[part 10 of 11: package /COM/VECTOR/CFG/WORKFLOW/SYSDESC/SYNC]
AUTOSAR XML (schema 00053)
package /COM/VECTOR/CFG/WORKFLOW/SYSDESC/SYNC  (continued)
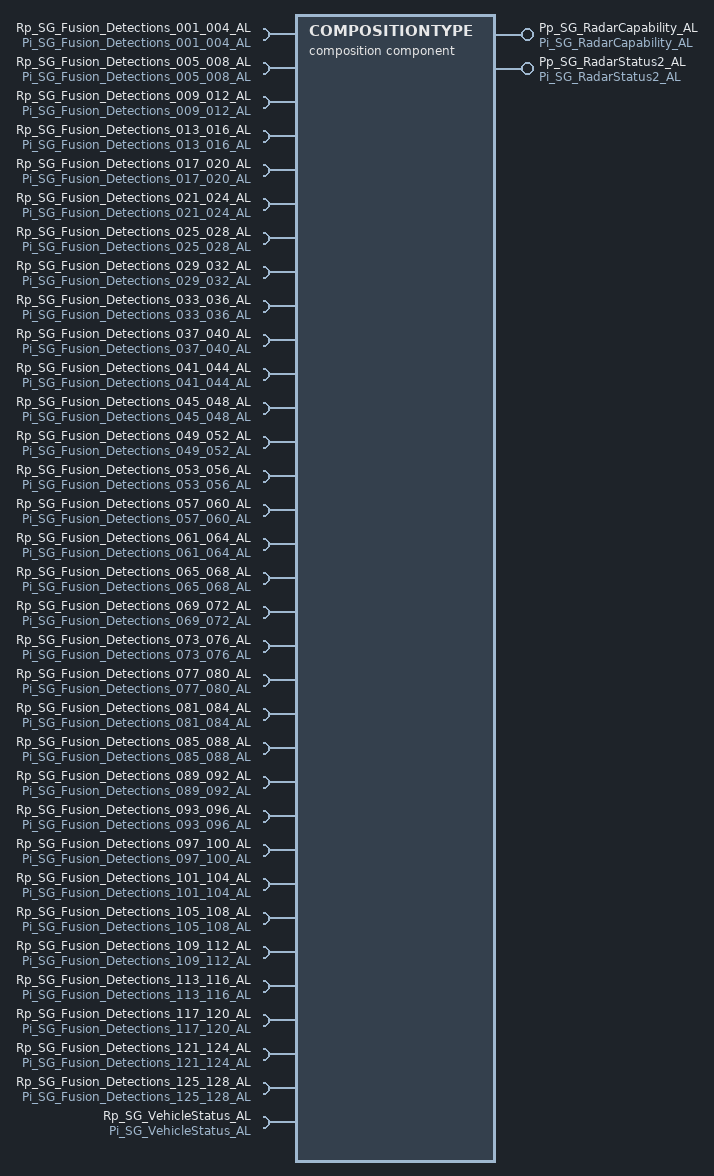
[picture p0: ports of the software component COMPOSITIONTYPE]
  composition sw component type COMPOSITIONTYPE  (continued)
    106 x provide port:  (continued)
      Pp_SG_Detections_185_188_AL: nonqueued-sender-com-spec{data-element=Vdp_SG_Detections_185_188_AL, init-value=fields=[DET_AZIMUTH_185:0, DET_AZIMUTH_186:0, DET_AZIMUTH_187:0, DET_AZIMUTH_188:0, DET_AZIMUTH_ERR_185:0, DET_AZIMUTH_ERR_186:0, DET_AZIMUTH_ERR_187:0, DET_AZIMUTH_ERR_188:0, DET_BELOW_RAIN_THOLD_185:0, DET_BELOW_RAIN_THOLD_186:0, DET_BELOW_RAIN_THOLD_187:0, DET_BELOW_RAIN_THOLD_188:0, DET_BI_STATIC_FLAG_185:0, DET_BI_STATIC_FLAG_186:0, DET_BI_STATIC_FLAG_187:0, DET_BI_STATIC_FLAG_188:0, DET_CONFD_AZIMUTH_185:0, DET_CONFD_AZIMUTH_186:0, DET_CONFD_AZIMUTH_187:0, DET_CONFD_AZIMUTH_188:0, DET_CONFD_ELEVATION_185:0, DET_CONFD_ELEVATION_186:0, DET_CONFD_ELEVATION_187:0, DET_CONFD_ELEVATION_188:0, DET_ELEVATION_185:0, DET_ELEVATION_186:0, DET_ELEVATION_187:0, DET_ELEVATION_188:0, DET_ELEVATION_ERR_185:0, DET_ELEVATION_ERR_186:0, DET_ELEVATION_ERR_187:0, DET_ELEVATION_ERR_188:0, DET_EXISTENCE_PROB_185:0, DET_EXISTENCE_PROB_186:0, DET_EXISTENCE_PROB_187:0, DET_EXISTENCE_PROB_188:0, DET_HVC_FLAG_185:0, DET_HVC_FLAG_186:0, DET_HVC_FLAG_187:0, DET_HVC_FLAG_188:0, DET_IDM_185:0, DET_IDM_186:0, DET_IDM_187:0, DET_IDM_188:0, DET_MH_CRC16_185_188:0, DET_MH_CYCLE_COUNTER_185_188:0, DET_MH_SCAN_INDEX_4LSB_185_188:0, DET_MTD_185:0, DET_MTD_186:0, DET_MTD_187:0, DET_MTD_188:0, DET_PROB_1STAZHYPO_185:0, DET_PROB_1STAZHYPO_186:0, DET_PROB_1STAZHYPO_187:0, DET_PROB_1STAZHYPO_188:0, DET_RANGE_185:0, DET_RANGE_186:0, DET_RANGE_187:0, DET_RANGE_188:0, DET_RANGE_ERR_185:0, DET_RANGE_ERR_186:0, DET_RANGE_ERR_187:0, DET_RANGE_ERR_188:0, DET_RANGE_VELOCITY_185:16384, DET_RANGE_VELOCITY_186:16384, DET_RANGE_VELOCITY_187:16384, DET_RANGE_VELOCITY_188:16384, DET_RANGE_VELOCITY_ERR_185:0, DET_RANGE_VELOCITY_ERR_186:0, DET_RANGE_VELOCITY_ERR_187:0, DET_RANGE_VELOCITY_ERR_188:0, DET_RCS_185:128, DET_RCS_186:128, DET_RCS_187:128, DET_RCS_188:128, DET_SNR_185:0, DET_SNR_186:0, DET_SNR_187:0, DET_SNR_188:0, DET_SUPER_RES_TARGET_185:0, DET_SUPER_RES_TARGET_186:0, DET_SUPER_RES_TARGET_187:0, DET_SUPER_RES_TARGET_188:0]}, provided-interface=Pi_SG_Detections_185_188_AL
      Pp_SG_Detections_189_192_AL: nonqueued-sender-com-spec{data-element=Vdp_SG_Detections_189_192_AL, init-value=fields=[DET_AZIMUTH_189:0, DET_AZIMUTH_190:0, DET_AZIMUTH_191:0, DET_AZIMUTH_192:0, DET_AZIMUTH_ERR_189:0, DET_AZIMUTH_ERR_190:0, DET_AZIMUTH_ERR_191:0, DET_AZIMUTH_ERR_192:0, DET_BELOW_RAIN_THOLD_189:0, DET_BELOW_RAIN_THOLD_190:0, DET_BELOW_RAIN_THOLD_191:0, DET_BELOW_RAIN_THOLD_192:0, DET_BI_STATIC_FLAG_189:0, DET_BI_STATIC_FLAG_190:0, DET_BI_STATIC_FLAG_191:0, DET_BI_STATIC_FLAG_192:0, DET_CONFD_AZIMUTH_189:0, DET_CONFD_AZIMUTH_190:0, DET_CONFD_AZIMUTH_191:0, DET_CONFD_AZIMUTH_192:0, DET_CONFD_ELEVATION_189:0, DET_CONFD_ELEVATION_190:0, DET_CONFD_ELEVATION_191:0, DET_CONFD_ELEVATION_192:0, DET_ELEVATION_189:0, DET_ELEVATION_190:0, DET_ELEVATION_191:0, DET_ELEVATION_192:0, DET_ELEVATION_ERR_189:0, DET_ELEVATION_ERR_190:0, DET_ELEVATION_ERR_191:0, DET_ELEVATION_ERR_192:0, DET_EXISTENCE_PROB_189:0, DET_EXISTENCE_PROB_190:0, DET_EXISTENCE_PROB_191:0, DET_EXISTENCE_PROB_192:0, DET_HVC_FLAG_189:0, DET_HVC_FLAG_190:0, DET_HVC_FLAG_191:0, DET_HVC_FLAG_192:0, DET_IDM_189:0, DET_IDM_190:0, DET_IDM_191:0, DET_IDM_192:0, DET_MH_CRC16_189_192:0, DET_MH_CYCLE_COUNTER_189_192:0, DET_MH_SCAN_INDEX_4LSB_189_192:0, DET_MTD_189:0, DET_MTD_190:0, DET_MTD_191:0, DET_MTD_192:0, DET_PROB_1STAZHYPO_189:0, DET_PROB_1STAZHYPO_190:0, DET_PROB_1STAZHYPO_191:0, DET_PROB_1STAZHYPO_192:0, DET_RANGE_189:0, DET_RANGE_190:0, DET_RANGE_191:0, DET_RANGE_192:0, DET_RANGE_ERR_189:0, DET_RANGE_ERR_190:0, DET_RANGE_ERR_191:0, DET_RANGE_ERR_192:0, DET_RANGE_VELOCITY_189:16384, DET_RANGE_VELOCITY_190:16384, DET_RANGE_VELOCITY_191:16384, DET_RANGE_VELOCITY_192:16384, DET_RANGE_VELOCITY_ERR_189:0, DET_RANGE_VELOCITY_ERR_190:0, DET_RANGE_VELOCITY_ERR_191:0, DET_RANGE_VELOCITY_ERR_192:0, DET_RCS_189:128, DET_RCS_190:128, DET_RCS_191:128, DET_RCS_192:128, DET_SNR_189:0, DET_SNR_190:0, DET_SNR_191:0, DET_SNR_192:0, DET_SUPER_RES_TARGET_189:0, DET_SUPER_RES_TARGET_190:0, DET_SUPER_RES_TARGET_191:0, DET_SUPER_RES_TARGET_192:0]}, provided-interface=Pi_SG_Detections_189_192_AL
      Pp_SG_Detections_193_196_AL: nonqueued-sender-com-spec{data-element=Vdp_SG_Detections_193_196_AL, init-value=fields=[DET_AZIMUTH_193:0, DET_AZIMUTH_194:0, DET_AZIMUTH_195:0, DET_AZIMUTH_196:0, DET_AZIMUTH_ERR_193:0, DET_AZIMUTH_ERR_194:0, DET_AZIMUTH_ERR_195:0, DET_AZIMUTH_ERR_196:0, DET_BELOW_RAIN_THOLD_193:0, DET_BELOW_RAIN_THOLD_194:0, DET_BELOW_RAIN_THOLD_195:0, DET_BELOW_RAIN_THOLD_196:0, DET_BI_STATIC_FLAG_193:0, DET_BI_STATIC_FLAG_194:0, DET_BI_STATIC_FLAG_195:0, DET_BI_STATIC_FLAG_196:0, DET_CONFD_AZIMUTH_193:0, DET_CONFD_AZIMUTH_194:0, DET_CONFD_AZIMUTH_195:0, DET_CONFD_AZIMUTH_196:0, DET_CONFD_ELEVATION_193:0, DET_CONFD_ELEVATION_194:0, DET_CONFD_ELEVATION_195:0, DET_CONFD_ELEVATION_196:0, DET_ELEVATION_193:0, DET_ELEVATION_194:0, DET_ELEVATION_195:0, DET_ELEVATION_196:0, DET_ELEVATION_ERR_193:0, DET_ELEVATION_ERR_194:0, DET_ELEVATION_ERR_195:0, DET_ELEVATION_ERR_196:0, DET_EXISTENCE_PROB_193:0, DET_EXISTENCE_PROB_194:0, DET_EXISTENCE_PROB_195:0, DET_EXISTENCE_PROB_196:0, DET_HVC_FLAG_193:0, DET_HVC_FLAG_194:0, DET_HVC_FLAG_195:0, DET_HVC_FLAG_196:0, DET_IDM_193:0, DET_IDM_194:0, DET_IDM_195:0, DET_IDM_196:0, DET_MH_CRC16_193_196:0, DET_MH_CYCLE_COUNTER_193_196:0, DET_MH_SCAN_INDEX_4LSB_193_196:0, DET_MTD_193:0, DET_MTD_194:0, DET_MTD_195:0, DET_MTD_196:0, DET_PROB_1STAZHYPO_193:0, DET_PROB_1STAZHYPO_194:0, DET_PROB_1STAZHYPO_195:0, DET_PROB_1STAZHYPO_196:0, DET_RANGE_193:0, DET_RANGE_194:0, DET_RANGE_195:0, DET_RANGE_196:0, DET_RANGE_ERR_193:0, DET_RANGE_ERR_194:0, DET_RANGE_ERR_195:0, DET_RANGE_ERR_196:0, DET_RANGE_VELOCITY_193:16384, DET_RANGE_VELOCITY_194:16384, DET_RANGE_VELOCITY_195:16384, DET_RANGE_VELOCITY_196:16384, DET_RANGE_VELOCITY_ERR_193:0, DET_RANGE_VELOCITY_ERR_194:0, DET_RANGE_VELOCITY_ERR_195:0, DET_RANGE_VELOCITY_ERR_196:0, DET_RCS_193:128, DET_RCS_194:128, DET_RCS_195:128, DET_RCS_196:128, DET_SNR_193:0, DET_SNR_194:0, DET_SNR_195:0, DET_SNR_196:0, DET_SUPER_RES_TARGET_193:0, DET_SUPER_RES_TARGET_194:0, DET_SUPER_RES_TARGET_195:0, DET_SUPER_RES_TARGET_196:0]}, provided-interface=Pi_SG_Detections_193_196_AL
      Pp_SG_Detections_197_200_AL: nonqueued-sender-com-spec{data-element=Vdp_SG_Detections_197_200_AL, init-value=fields=[DET_AZIMUTH_197:0, DET_AZIMUTH_198:0, DET_AZIMUTH_199:0, DET_AZIMUTH_200:0, DET_AZIMUTH_ERR_197:0, DET_AZIMUTH_ERR_198:0, DET_AZIMUTH_ERR_199:0, DET_AZIMUTH_ERR_200:0, DET_BELOW_RAIN_THOLD_197:0, DET_BELOW_RAIN_THOLD_198:0, DET_BELOW_RAIN_THOLD_199:0, DET_BELOW_RAIN_THOLD_200:0, DET_BI_STATIC_FLAG_197:0, DET_BI_STATIC_FLAG_198:0, DET_BI_STATIC_FLAG_199:0, DET_BI_STATIC_FLAG_200:0, DET_CONFD_AZIMUTH_197:0, DET_CONFD_AZIMUTH_198:0, DET_CONFD_AZIMUTH_199:0, DET_CONFD_AZIMUTH_200:0, DET_CONFD_ELEVATION_197:0, DET_CONFD_ELEVATION_198:0, DET_CONFD_ELEVATION_199:0, DET_CONFD_ELEVATION_200:0, DET_ELEVATION_197:0, DET_ELEVATION_198:0, DET_ELEVATION_199:0, DET_ELEVATION_200:0, DET_ELEVATION_ERR_197:0, DET_ELEVATION_ERR_198:0, DET_ELEVATION_ERR_199:0, DET_ELEVATION_ERR_200:0, DET_EXISTENCE_PROB_197:0, DET_EXISTENCE_PROB_198:0, DET_EXISTENCE_PROB_199:0, DET_EXISTENCE_PROB_200:0, DET_HVC_FLAG_197:0, DET_HVC_FLAG_198:0, DET_HVC_FLAG_199:0, DET_HVC_FLAG_200:0, DET_IDM_197:0, DET_IDM_198:0, DET_IDM_199:0, DET_IDM_200:0, DET_MH_CRC16_197_200:0, DET_MH_CYCLE_COUNTER_197_200:0, DET_MH_SCAN_INDEX_4LSB_197_200:0, DET_MTD_197:0, DET_MTD_198:0, DET_MTD_199:0, DET_MTD_200:0, DET_PROB_1STAZHYPO_197:0, DET_PROB_1STAZHYPO_198:0, DET_PROB_1STAZHYPO_199:0, DET_PROB_1STAZHYPO_200:0, DET_RANGE_197:0, DET_RANGE_198:0, DET_RANGE_199:0, DET_RANGE_200:0, DET_RANGE_ERR_197:0, DET_RANGE_ERR_198:0, DET_RANGE_ERR_199:0, DET_RANGE_ERR_200:0, DET_RANGE_VELOCITY_197:16384, DET_RANGE_VELOCITY_198:16384, DET_RANGE_VELOCITY_199:16384, DET_RANGE_VELOCITY_200:16384, DET_RANGE_VELOCITY_ERR_197:0, DET_RANGE_VELOCITY_ERR_198:0, DET_RANGE_VELOCITY_ERR_199:0, DET_RANGE_VELOCITY_ERR_200:0, DET_RCS_197:128, DET_RCS_198:128, DET_RCS_199:128, DET_RCS_200:128, DET_SNR_197:0, DET_SNR_198:0, DET_SNR_199:0, DET_SNR_200:0, DET_SUPER_RES_TARGET_197:0, DET_SUPER_RES_TARGET_198:0, DET_SUPER_RES_TARGET_199:0, DET_SUPER_RES_TARGET_200:0]}, provided-interface=Pi_SG_Detections_197_200_AL
      Pp_SG_Detections_201_204_AL: nonqueued-sender-com-spec{data-element=Vdp_SG_Detections_201_204_AL, init-value=fields=[DET_AZIMUTH_201:0, DET_AZIMUTH_202:0, DET_AZIMUTH_203:0, DET_AZIMUTH_204:0, DET_AZIMUTH_ERR_201:0, DET_AZIMUTH_ERR_202:0, DET_AZIMUTH_ERR_203:0, DET_AZIMUTH_ERR_204:0, DET_BELOW_RAIN_THOLD_201:0, DET_BELOW_RAIN_THOLD_202:0, DET_BELOW_RAIN_THOLD_203:0, DET_BELOW_RAIN_THOLD_204:0, DET_BI_STATIC_FLAG_201:0, DET_BI_STATIC_FLAG_202:0, DET_BI_STATIC_FLAG_203:0, DET_BI_STATIC_FLAG_204:0, DET_CONFD_AZIMUTH_201:0, DET_CONFD_AZIMUTH_202:0, DET_CONFD_AZIMUTH_203:0, DET_CONFD_AZIMUTH_204:0, DET_CONFD_ELEVATION_201:0, DET_CONFD_ELEVATION_202:0, DET_CONFD_ELEVATION_203:0, DET_CONFD_ELEVATION_204:0, DET_ELEVATION_201:0, DET_ELEVATION_202:0, DET_ELEVATION_203:0, DET_ELEVATION_204:0, DET_ELEVATION_ERR_201:0, DET_ELEVATION_ERR_202:0, DET_ELEVATION_ERR_203:0, DET_ELEVATION_ERR_204:0, DET_EXISTENCE_PROB_201:0, DET_EXISTENCE_PROB_202:0, DET_EXISTENCE_PROB_203:0, DET_EXISTENCE_PROB_204:0, DET_HVC_FLAG_201:0, DET_HVC_FLAG_202:0, DET_HVC_FLAG_203:0, DET_HVC_FLAG_204:0, DET_IDM_201:0, DET_IDM_202:0, DET_IDM_203:0, DET_IDM_204:0, DET_MH_CRC16_201_204:0, DET_MH_CYCLE_COUNTER_201_204:0, DET_MH_SCAN_INDEX_4LSB_201_204:0, DET_MTD_201:0, DET_MTD_202:0, DET_MTD_203:0, DET_MTD_204:0, DET_PROB_1STAZHYPO_201:0, DET_PROB_1STAZHYPO_202:0, DET_PROB_1STAZHYPO_203:0, DET_PROB_1STAZHYPO_204:0, DET_RANGE_201:0, DET_RANGE_202:0, DET_RANGE_203:0, DET_RANGE_204:0, DET_RANGE_ERR_201:0, DET_RANGE_ERR_202:0, DET_RANGE_ERR_203:0, DET_RANGE_ERR_204:0, DET_RANGE_VELOCITY_201:16384, DET_RANGE_VELOCITY_202:16384, DET_RANGE_VELOCITY_203:16384, DET_RANGE_VELOCITY_204:16384, DET_RANGE_VELOCITY_ERR_201:0, DET_RANGE_VELOCITY_ERR_202:0, DET_RANGE_VELOCITY_ERR_203:0, DET_RANGE_VELOCITY_ERR_204:0, DET_RCS_201:128, DET_RCS_202:128, DET_RCS_203:128, DET_RCS_204:128, DET_SNR_201:0, DET_SNR_202:0, DET_SNR_203:0, DET_SNR_204:0, DET_SUPER_RES_TARGET_201:0, DET_SUPER_RES_TARGET_202:0, DET_SUPER_RES_TARGET_203:0, DET_SUPER_RES_TARGET_204:0]}, provided-interface=Pi_SG_Detections_201_204_AL
      Pp_SG_Detections_205_208_AL: nonqueued-sender-com-spec{data-element=Vdp_SG_Detections_205_208_AL, init-value=fields=[DET_AZIMUTH_205:0, DET_AZIMUTH_206:0, DET_AZIMUTH_207:0, DET_AZIMUTH_208:0, DET_AZIMUTH_ERR_205:0, DET_AZIMUTH_ERR_206:0, DET_AZIMUTH_ERR_207:0, DET_AZIMUTH_ERR_208:0, DET_BELOW_RAIN_THOLD_205:0, DET_BELOW_RAIN_THOLD_206:0, DET_BELOW_RAIN_THOLD_207:0, DET_BELOW_RAIN_THOLD_208:0, DET_BI_STATIC_FLAG_205:0, DET_BI_STATIC_FLAG_206:0, DET_BI_STATIC_FLAG_207:0, DET_BI_STATIC_FLAG_208:0, DET_CONFD_AZIMUTH_205:0, DET_CONFD_AZIMUTH_206:0, DET_CONFD_AZIMUTH_207:0, DET_CONFD_AZIMUTH_208:0, DET_CONFD_ELEVATION_205:0, DET_CONFD_ELEVATION_206:0, DET_CONFD_ELEVATION_207:0, DET_CONFD_ELEVATION_208:0, DET_ELEVATION_205:0, DET_ELEVATION_206:0, DET_ELEVATION_207:0, DET_ELEVATION_208:0, DET_ELEVATION_ERR_205:0, DET_ELEVATION_ERR_206:0, DET_ELEVATION_ERR_207:0, DET_ELEVATION_ERR_208:0, DET_EXISTENCE_PROB_205:0, DET_EXISTENCE_PROB_206:0, DET_EXISTENCE_PROB_207:0, DET_EXISTENCE_PROB_208:0, DET_HVC_FLAG_205:0, DET_HVC_FLAG_206:0, DET_HVC_FLAG_207:0, DET_HVC_FLAG_208:0, DET_IDM_205:0, DET_IDM_206:0, DET_IDM_207:0, DET_IDM_208:0, DET_MH_CRC16_205_208:0, DET_MH_CYCLE_COUNTER_205_208:0, DET_MH_SCAN_INDEX_4LSB_205_208:0, DET_MTD_205:0, DET_MTD_206:0, DET_MTD_207:0, DET_MTD_208:0, DET_PROB_1STAZHYPO_205:0, DET_PROB_1STAZHYPO_206:0, DET_PROB_1STAZHYPO_207:0, DET_PROB_1STAZHYPO_208:0, DET_RANGE_205:0, DET_RANGE_206:0, DET_RANGE_207:0, DET_RANGE_208:0, DET_RANGE_ERR_205:0, DET_RANGE_ERR_206:0, DET_RANGE_ERR_207:0, DET_RANGE_ERR_208:0, DET_RANGE_VELOCITY_205:16384, DET_RANGE_VELOCITY_206:16384, DET_RANGE_VELOCITY_207:16384, DET_RANGE_VELOCITY_208:16384, DET_RANGE_VELOCITY_ERR_205:0, DET_RANGE_VELOCITY_ERR_206:0, DET_RANGE_VELOCITY_ERR_207:0, DET_RANGE_VELOCITY_ERR_208:0, DET_RCS_205:128, DET_RCS_206:128, DET_RCS_207:128, DET_RCS_208:128, DET_SNR_205:0, DET_SNR_206:0, DET_SNR_207:0, DET_SNR_208:0, DET_SUPER_RES_TARGET_205:0, DET_SUPER_RES_TARGET_206:0, DET_SUPER_RES_TARGET_207:0, DET_SUPER_RES_TARGET_208:0]}, provided-interface=Pi_SG_Detections_205_208_AL
      Pp_SG_Detections_209_212_AL: nonqueued-sender-com-spec{data-element=Vdp_SG_Detections_209_212_AL, init-value=fields=[DET_AZIMUTH_209:0, DET_AZIMUTH_210:0, DET_AZIMUTH_211:0, DET_AZIMUTH_212:0, DET_AZIMUTH_ERR_209:0, DET_AZIMUTH_ERR_210:0, DET_AZIMUTH_ERR_211:0, DET_AZIMUTH_ERR_212:0, DET_BELOW_RAIN_THOLD_209:0, DET_BELOW_RAIN_THOLD_210:0, DET_BELOW_RAIN_THOLD_211:0, DET_BELOW_RAIN_THOLD_212:0, DET_BI_STATIC_FLAG_209:0, DET_BI_STATIC_FLAG_210:0, DET_BI_STATIC_FLAG_211:0, DET_BI_STATIC_FLAG_212:0, DET_CONFD_AZIMUTH_209:0, DET_CONFD_AZIMUTH_210:0, DET_CONFD_AZIMUTH_211:0, DET_CONFD_AZIMUTH_212:0, DET_CONFD_ELEVATION_209:0, DET_CONFD_ELEVATION_210:0, DET_CONFD_ELEVATION_211:0, DET_CONFD_ELEVATION_212:0, DET_ELEVATION_209:0, DET_ELEVATION_210:0, DET_ELEVATION_211:0, DET_ELEVATION_212:0, DET_ELEVATION_ERR_209:0, DET_ELEVATION_ERR_210:0, DET_ELEVATION_ERR_211:0, DET_ELEVATION_ERR_212:0, DET_EXISTENCE_PROB_209:0, DET_EXISTENCE_PROB_210:0, DET_EXISTENCE_PROB_211:0, DET_EXISTENCE_PROB_212:0, DET_HVC_FLAG_209:0, DET_HVC_FLAG_210:0, DET_HVC_FLAG_211:0, DET_HVC_FLAG_212:0, DET_IDM_209:0, DET_IDM_210:0, DET_IDM_211:0, DET_IDM_212:0, DET_MH_CRC16_209_212:0, DET_MH_CYCLE_COUNTER_209_212:0, DET_MH_SCAN_INDEX_4LSB_209_212:0, DET_MTD_209:0, DET_MTD_210:0, DET_MTD_211:0, DET_MTD_212:0, DET_PROB_1STAZHYPO_209:0, DET_PROB_1STAZHYPO_210:0, DET_PROB_1STAZHYPO_211:0, DET_PROB_1STAZHYPO_212:0, DET_RANGE_209:0, DET_RANGE_210:0, DET_RANGE_211:0, DET_RANGE_212:0, DET_RANGE_ERR_209:0, DET_RANGE_ERR_210:0, DET_RANGE_ERR_211:0, DET_RANGE_ERR_212:0, DET_RANGE_VELOCITY_209:16384, DET_RANGE_VELOCITY_210:16384, DET_RANGE_VELOCITY_211:16384, DET_RANGE_VELOCITY_212:16384, DET_RANGE_VELOCITY_ERR_209:0, DET_RANGE_VELOCITY_ERR_210:0, DET_RANGE_VELOCITY_ERR_211:0, DET_RANGE_VELOCITY_ERR_212:0, DET_RCS_209:128, DET_RCS_210:128, DET_RCS_211:128, DET_RCS_212:128, DET_SNR_209:0, DET_SNR_210:0, DET_SNR_211:0, DET_SNR_212:0, DET_SUPER_RES_TARGET_209:0, DET_SUPER_RES_TARGET_210:0, DET_SUPER_RES_TARGET_211:0, DET_SUPER_RES_TARGET_212:0]}, provided-interface=Pi_SG_Detections_209_212_AL
      Pp_SG_Detections_213_216_AL: nonqueued-sender-com-spec{data-element=Vdp_SG_Detections_213_216_AL, init-value=fields=[DET_AZIMUTH_213:0, DET_AZIMUTH_214:0, DET_AZIMUTH_215:0, DET_AZIMUTH_216:0, DET_AZIMUTH_ERR_213:0, DET_AZIMUTH_ERR_214:0, DET_AZIMUTH_ERR_215:0, DET_AZIMUTH_ERR_216:0, DET_BELOW_RAIN_THOLD_213:0, DET_BELOW_RAIN_THOLD_214:0, DET_BELOW_RAIN_THOLD_215:0, DET_BELOW_RAIN_THOLD_216:0, DET_BI_STATIC_FLAG_213:0, DET_BI_STATIC_FLAG_214:0, DET_BI_STATIC_FLAG_215:0, DET_BI_STATIC_FLAG_216:0, DET_CONFD_AZIMUTH_213:0, DET_CONFD_AZIMUTH_214:0, DET_CONFD_AZIMUTH_215:0, DET_CONFD_AZIMUTH_216:0, DET_CONFD_ELEVATION_213:0, DET_CONFD_ELEVATION_214:0, DET_CONFD_ELEVATION_215:0, DET_CONFD_ELEVATION_216:0, DET_ELEVATION_213:0, DET_ELEVATION_214:0, DET_ELEVATION_215:0, DET_ELEVATION_216:0, DET_ELEVATION_ERR_213:0, DET_ELEVATION_ERR_214:0, DET_ELEVATION_ERR_215:0, DET_ELEVATION_ERR_216:0, DET_EXISTENCE_PROB_213:0, DET_EXISTENCE_PROB_214:0, DET_EXISTENCE_PROB_215:0, DET_EXISTENCE_PROB_216:0, DET_HVC_FLAG_213:0, DET_HVC_FLAG_214:0, DET_HVC_FLAG_215:0, DET_HVC_FLAG_216:0, DET_IDM_213:0, DET_IDM_214:0, DET_IDM_215:0, DET_IDM_216:0, DET_MH_CRC16_213_216:0, DET_MH_CYCLE_COUNTER_213_216:0, DET_MH_SCAN_INDEX_4LSB_213_216:0, DET_MTD_213:0, DET_MTD_214:0, DET_MTD_215:0, DET_MTD_216:0, DET_PROB_1STAZHYPO_213:0, DET_PROB_1STAZHYPO_214:0, DET_PROB_1STAZHYPO_215:0, DET_PROB_1STAZHYPO_216:0, DET_RANGE_213:0, DET_RANGE_214:0, DET_RANGE_215:0, DET_RANGE_216:0, DET_RANGE_ERR_213:0, DET_RANGE_ERR_214:0, DET_RANGE_ERR_215:0, DET_RANGE_ERR_216:0, DET_RANGE_VELOCITY_213:16384, DET_RANGE_VELOCITY_214:16384, DET_RANGE_VELOCITY_215:16384, DET_RANGE_VELOCITY_216:16384, DET_RANGE_VELOCITY_ERR_213:0, DET_RANGE_VELOCITY_ERR_214:0, DET_RANGE_VELOCITY_ERR_215:0, DET_RANGE_VELOCITY_ERR_216:0, DET_RCS_213:128, DET_RCS_214:128, DET_RCS_215:128, DET_RCS_216:128, DET_SNR_213:0, DET_SNR_214:0, DET_SNR_215:0, DET_SNR_216:0, DET_SUPER_RES_TARGET_213:0, DET_SUPER_RES_TARGET_214:0, DET_SUPER_RES_TARGET_215:0, DET_SUPER_RES_TARGET_216:0]}, provided-interface=Pi_SG_Detections_213_216_AL
      Pp_SG_Detections_217_220_AL: nonqueued-sender-com-spec{data-element=Vdp_SG_Detections_217_220_AL, init-value=fields=[DET_AZIMUTH_217:0, DET_AZIMUTH_218:0, DET_AZIMUTH_219:0, DET_AZIMUTH_220:0, DET_AZIMUTH_ERR_217:0, DET_AZIMUTH_ERR_218:0, DET_AZIMUTH_ERR_219:0, DET_AZIMUTH_ERR_220:0, DET_BELOW_RAIN_THOLD_217:0, DET_BELOW_RAIN_THOLD_218:0, DET_BELOW_RAIN_THOLD_219:0, DET_BELOW_RAIN_THOLD_220:0, DET_BI_STATIC_FLAG_217:0, DET_BI_STATIC_FLAG_218:0, DET_BI_STATIC_FLAG_219:0, DET_BI_STATIC_FLAG_220:0, DET_CONFD_AZIMUTH_217:0, DET_CONFD_AZIMUTH_218:0, DET_CONFD_AZIMUTH_219:0, DET_CONFD_AZIMUTH_220:0, DET_CONFD_ELEVATION_217:0, DET_CONFD_ELEVATION_218:0, DET_CONFD_ELEVATION_219:0, DET_CONFD_ELEVATION_220:0, DET_ELEVATION_217:0, DET_ELEVATION_218:0, DET_ELEVATION_219:0, DET_ELEVATION_220:0, DET_ELEVATION_ERR_217:0, DET_ELEVATION_ERR_218:0, DET_ELEVATION_ERR_219:0, DET_ELEVATION_ERR_220:0, DET_EXISTENCE_PROB_217:0, DET_EXISTENCE_PROB_218:0, DET_EXISTENCE_PROB_219:0, DET_EXISTENCE_PROB_220:0, DET_HVC_FLAG_217:0, DET_HVC_FLAG_218:0, DET_HVC_FLAG_219:0, DET_HVC_FLAG_220:0, DET_IDM_217:0, DET_IDM_218:0, DET_IDM_219:0, DET_IDM_220:0, DET_MH_CRC16_217_220:0, DET_MH_CYCLE_COUNTER_217_220:0, DET_MH_SCAN_INDEX_4LSB_217_220:0, DET_MTD_217:0, DET_MTD_218:0, DET_MTD_219:0, DET_MTD_220:0, DET_PROB_1STAZHYPO_217:0, DET_PROB_1STAZHYPO_218:0, DET_PROB_1STAZHYPO_219:0, DET_PROB_1STAZHYPO_220:0, DET_RANGE_217:0, DET_RANGE_218:0, DET_RANGE_219:0, DET_RANGE_220:0, DET_RANGE_ERR_217:0, DET_RANGE_ERR_218:0, DET_RANGE_ERR_219:0, DET_RANGE_ERR_220:0, DET_RANGE_VELOCITY_217:16384, DET_RANGE_VELOCITY_218:16384, DET_RANGE_VELOCITY_219:16384, DET_RANGE_VELOCITY_220:16384, DET_RANGE_VELOCITY_ERR_217:0, DET_RANGE_VELOCITY_ERR_218:0, DET_RANGE_VELOCITY_ERR_219:0, DET_RANGE_VELOCITY_ERR_220:0, DET_RCS_217:128, DET_RCS_218:128, DET_RCS_219:128, DET_RCS_220:128, DET_SNR_217:0, DET_SNR_218:0, DET_SNR_219:0, DET_SNR_220:0, DET_SUPER_RES_TARGET_217:0, DET_SUPER_RES_TARGET_218:0, DET_SUPER_RES_TARGET_219:0, DET_SUPER_RES_TARGET_220:0]}, provided-interface=Pi_SG_Detections_217_220_AL
      Pp_SG_Detections_221_224_AL: nonqueued-sender-com-spec{data-element=Vdp_SG_Detections_221_224_AL, init-value=fields=[DET_AZIMUTH_221:0, DET_AZIMUTH_222:0, DET_AZIMUTH_223:0, DET_AZIMUTH_224:0, DET_AZIMUTH_ERR_221:0, DET_AZIMUTH_ERR_222:0, DET_AZIMUTH_ERR_223:0, DET_AZIMUTH_ERR_224:0, DET_BELOW_RAIN_THOLD_221:0, DET_BELOW_RAIN_THOLD_222:0, DET_BELOW_RAIN_THOLD_223:0, DET_BELOW_RAIN_THOLD_224:0, DET_BI_STATIC_FLAG_221:0, DET_BI_STATIC_FLAG_222:0, DET_BI_STATIC_FLAG_223:0, DET_BI_STATIC_FLAG_224:0, DET_CONFD_AZIMUTH_221:0, DET_CONFD_AZIMUTH_222:0, DET_CONFD_AZIMUTH_223:0, DET_CONFD_AZIMUTH_224:0, DET_CONFD_ELEVATION_221:0, DET_CONFD_ELEVATION_222:0, DET_CONFD_ELEVATION_223:0, DET_CONFD_ELEVATION_224:0, DET_ELEVATION_221:0, DET_ELEVATION_222:0, DET_ELEVATION_223:0, DET_ELEVATION_224:0, DET_ELEVATION_ERR_221:0, DET_ELEVATION_ERR_222:0, DET_ELEVATION_ERR_223:0, DET_ELEVATION_ERR_224:0, DET_EXISTENCE_PROB_221:0, DET_EXISTENCE_PROB_222:0, DET_EXISTENCE_PROB_223:0, DET_EXISTENCE_PROB_224:0, DET_HVC_FLAG_221:0, DET_HVC_FLAG_222:0, DET_HVC_FLAG_223:0, DET_HVC_FLAG_224:0, DET_IDM_221:0, DET_IDM_222:0, DET_IDM_223:0, DET_IDM_224:0, DET_MH_CRC16_221_224:0, DET_MH_CYCLE_COUNTER_221_224:0, DET_MH_SCAN_INDEX_4LSB_221_224:0, DET_MTD_221:0, DET_MTD_222:0, DET_MTD_223:0, DET_MTD_224:0, DET_PROB_1STAZHYPO_221:0, DET_PROB_1STAZHYPO_222:0, DET_PROB_1STAZHYPO_223:0, DET_PROB_1STAZHYPO_224:0, DET_RANGE_221:0, DET_RANGE_222:0, DET_RANGE_223:0, DET_RANGE_224:0, DET_RANGE_ERR_221:0, DET_RANGE_ERR_222:0, DET_RANGE_ERR_223:0, DET_RANGE_ERR_224:0, DET_RANGE_VELOCITY_221:16384, DET_RANGE_VELOCITY_222:16384, DET_RANGE_VELOCITY_223:16384, DET_RANGE_VELOCITY_224:16384, DET_RANGE_VELOCITY_ERR_221:0, DET_RANGE_VELOCITY_ERR_222:0, DET_RANGE_VELOCITY_ERR_223:0, DET_RANGE_VELOCITY_ERR_224:0, DET_RCS_221:128, DET_RCS_222:128, DET_RCS_223:128, DET_RCS_224:128, DET_SNR_221:0, DET_SNR_222:0, DET_SNR_223:0, DET_SNR_224:0, DET_SUPER_RES_TARGET_221:0, DET_SUPER_RES_TARGET_222:0, DET_SUPER_RES_TARGET_223:0, DET_SUPER_RES_TARGET_224:0]}, provided-interface=Pi_SG_Detections_221_224_AL
      Pp_SG_Detections_225_228_AL: nonqueued-sender-com-spec{data-element=Vdp_SG_Detections_225_228_AL, init-value=fields=[DET_AZIMUTH_225:0, DET_AZIMUTH_226:0, DET_AZIMUTH_227:0, DET_AZIMUTH_228:0, DET_AZIMUTH_ERR_225:0, DET_AZIMUTH_ERR_226:0, DET_AZIMUTH_ERR_227:0, DET_AZIMUTH_ERR_228:0, DET_BELOW_RAIN_THOLD_225:0, DET_BELOW_RAIN_THOLD_226:0, DET_BELOW_RAIN_THOLD_227:0, DET_BELOW_RAIN_THOLD_228:0, DET_BI_STATIC_FLAG_225:0, DET_BI_STATIC_FLAG_226:0, DET_BI_STATIC_FLAG_227:0, DET_BI_STATIC_FLAG_228:0, DET_CONFD_AZIMUTH_225:0, DET_CONFD_AZIMUTH_226:0, DET_CONFD_AZIMUTH_227:0, DET_CONFD_AZIMUTH_228:0, DET_CONFD_ELEVATION_225:0, DET_CONFD_ELEVATION_226:0, DET_CONFD_ELEVATION_227:0, DET_CONFD_ELEVATION_228:0, DET_ELEVATION_225:0, DET_ELEVATION_226:0, DET_ELEVATION_227:0, DET_ELEVATION_228:0, DET_ELEVATION_ERR_225:0, DET_ELEVATION_ERR_226:0, DET_ELEVATION_ERR_227:0, DET_ELEVATION_ERR_228:0, DET_EXISTENCE_PROB_225:0, DET_EXISTENCE_PROB_226:0, DET_EXISTENCE_PROB_227:0, DET_EXISTENCE_PROB_228:0, DET_HVC_FLAG_225:0, DET_HVC_FLAG_226:0, DET_HVC_FLAG_227:0, DET_HVC_FLAG_228:0, DET_IDM_225:0, DET_IDM_226:0, DET_IDM_227:0, DET_IDM_228:0, DET_MH_CRC16_225_228:0, DET_MH_CYCLE_COUNTER_225_228:0, DET_MH_SCAN_INDEX_4LSB_225_228:0, DET_MTD_225:0, DET_MTD_226:0, DET_MTD_227:0, DET_MTD_228:0, DET_PROB_1STAZHYPO_225:0, DET_PROB_1STAZHYPO_226:0, DET_PROB_1STAZHYPO_227:0, DET_PROB_1STAZHYPO_228:0, DET_RANGE_225:0, DET_RANGE_226:0, DET_RANGE_227:0, DET_RANGE_228:0, DET_RANGE_ERR_225:0, DET_RANGE_ERR_226:0, DET_RANGE_ERR_227:0, DET_RANGE_ERR_228:0, DET_RANGE_VELOCITY_225:16384, DET_RANGE_VELOCITY_226:16384, DET_RANGE_VELOCITY_227:16384, DET_RANGE_VELOCITY_228:16384, DET_RANGE_VELOCITY_ERR_225:0, DET_RANGE_VELOCITY_ERR_226:0, DET_RANGE_VELOCITY_ERR_227:0, DET_RANGE_VELOCITY_ERR_228:0, DET_RCS_225:128, DET_RCS_226:128, DET_RCS_227:128, DET_RCS_228:128, DET_SNR_225:0, DET_SNR_226:0, DET_SNR_227:0, DET_SNR_228:0, DET_SUPER_RES_TARGET_225:0, DET_SUPER_RES_TARGET_226:0, DET_SUPER_RES_TARGET_227:0, DET_SUPER_RES_TARGET_228:0]}, provided-interface=Pi_SG_Detections_225_228_AL
      Pp_SG_Detections_229_232_AL: nonqueued-sender-com-spec{data-element=Vdp_SG_Detections_229_232_AL, init-value=fields=[DET_AZIMUTH_229:0, DET_AZIMUTH_230:0, DET_AZIMUTH_231:0, DET_AZIMUTH_232:0, DET_AZIMUTH_ERR_229:0, DET_AZIMUTH_ERR_230:0, DET_AZIMUTH_ERR_231:0, DET_AZIMUTH_ERR_232:0, DET_BELOW_RAIN_THOLD_229:0, DET_BELOW_RAIN_THOLD_230:0, DET_BELOW_RAIN_THOLD_231:0, DET_BELOW_RAIN_THOLD_232:0, DET_BI_STATIC_FLAG_229:0, DET_BI_STATIC_FLAG_230:0, DET_BI_STATIC_FLAG_231:0, DET_BI_STATIC_FLAG_232:0, DET_CONFD_AZIMUTH_229:0, DET_CONFD_AZIMUTH_230:0, DET_CONFD_AZIMUTH_231:0, DET_CONFD_AZIMUTH_232:0, DET_CONFD_ELEVATION_229:0, DET_CONFD_ELEVATION_230:0, DET_CONFD_ELEVATION_231:0, DET_CONFD_ELEVATION_232:0, DET_ELEVATION_229:0, DET_ELEVATION_230:0, DET_ELEVATION_231:0, DET_ELEVATION_232:0, DET_ELEVATION_ERR_229:0, DET_ELEVATION_ERR_230:0, DET_ELEVATION_ERR_231:0, DET_ELEVATION_ERR_232:0, DET_EXISTENCE_PROB_229:0, DET_EXISTENCE_PROB_230:0, DET_EXISTENCE_PROB_231:0, DET_EXISTENCE_PROB_232:0, DET_HVC_FLAG_229:0, DET_HVC_FLAG_230:0, DET_HVC_FLAG_231:0, DET_HVC_FLAG_232:0, DET_IDM_229:0, DET_IDM_230:0, DET_IDM_231:0, DET_IDM_232:0, DET_MH_CRC16_229_232:0, DET_MH_CYCLE_COUNTER_229_232:0, DET_MH_SCAN_INDEX_4LSB_229_232:0, DET_MTD_229:0, DET_MTD_230:0, DET_MTD_231:0, DET_MTD_232:0, DET_PROB_1STAZHYPO_229:0, DET_PROB_1STAZHYPO_230:0, DET_PROB_1STAZHYPO_231:0, DET_PROB_1STAZHYPO_232:0, DET_RANGE_229:0, DET_RANGE_230:0, DET_RANGE_231:0, DET_RANGE_232:0, DET_RANGE_ERR_229:0, DET_RANGE_ERR_230:0, DET_RANGE_ERR_231:0, DET_RANGE_ERR_232:0, DET_RANGE_VELOCITY_229:16384, DET_RANGE_VELOCITY_230:16384, DET_RANGE_VELOCITY_231:16384, DET_RANGE_VELOCITY_232:16384, DET_RANGE_VELOCITY_ERR_229:0, DET_RANGE_VELOCITY_ERR_230:0, DET_RANGE_VELOCITY_ERR_231:0, DET_RANGE_VELOCITY_ERR_232:0, DET_RCS_229:128, DET_RCS_230:128, DET_RCS_231:128, DET_RCS_232:128, DET_SNR_229:0, DET_SNR_230:0, DET_SNR_231:0, DET_SNR_232:0, DET_SUPER_RES_TARGET_229:0, DET_SUPER_RES_TARGET_230:0, DET_SUPER_RES_TARGET_231:0, DET_SUPER_RES_TARGET_232:0]}, provided-interface=Pi_SG_Detections_229_232_AL
      Pp_SG_Detections_233_236_AL: nonqueued-sender-com-spec{data-element=Vdp_SG_Detections_233_236_AL, init-value=fields=[DET_AZIMUTH_233:0, DET_AZIMUTH_234:0, DET_AZIMUTH_235:0, DET_AZIMUTH_236:0, DET_AZIMUTH_ERR_233:0, DET_AZIMUTH_ERR_234:0, DET_AZIMUTH_ERR_235:0, DET_AZIMUTH_ERR_236:0, DET_BELOW_RAIN_THOLD_233:0, DET_BELOW_RAIN_THOLD_234:0, DET_BELOW_RAIN_THOLD_235:0, DET_BELOW_RAIN_THOLD_236:0, DET_BI_STATIC_FLAG_233:0, DET_BI_STATIC_FLAG_234:0, DET_BI_STATIC_FLAG_235:0, DET_BI_STATIC_FLAG_236:0, DET_CONFD_AZIMUTH_233:0, DET_CONFD_AZIMUTH_234:0, DET_CONFD_AZIMUTH_235:0, DET_CONFD_AZIMUTH_236:0, DET_CONFD_ELEVATION_233:0, DET_CONFD_ELEVATION_234:0, DET_CONFD_ELEVATION_235:0, DET_CONFD_ELEVATION_236:0, DET_ELEVATION_233:0, DET_ELEVATION_234:0, DET_ELEVATION_235:0, DET_ELEVATION_236:0, DET_ELEVATION_ERR_233:0, DET_ELEVATION_ERR_234:0, DET_ELEVATION_ERR_235:0, DET_ELEVATION_ERR_236:0, DET_EXISTENCE_PROB_233:0, DET_EXISTENCE_PROB_234:0, DET_EXISTENCE_PROB_235:0, DET_EXISTENCE_PROB_236:0, DET_HVC_FLAG_233:0, DET_HVC_FLAG_234:0, DET_HVC_FLAG_235:0, DET_HVC_FLAG_236:0, DET_IDM_233:0, DET_IDM_234:0, DET_IDM_235:0, DET_IDM_236:0, DET_MH_CRC16_233_236:0, DET_MH_CYCLE_COUNTER_233_236:0, DET_MH_SCAN_INDEX_4LSB_233_236:0, DET_MTD_233:0, DET_MTD_234:0, DET_MTD_235:0, DET_MTD_236:0, DET_PROB_1STAZHYPO_233:0, DET_PROB_1STAZHYPO_234:0, DET_PROB_1STAZHYPO_235:0, DET_PROB_1STAZHYPO_236:0, DET_RANGE_233:0, DET_RANGE_234:0, DET_RANGE_235:0, DET_RANGE_236:0, DET_RANGE_ERR_233:0, DET_RANGE_ERR_234:0, DET_RANGE_ERR_235:0, DET_RANGE_ERR_236:0, DET_RANGE_VELOCITY_233:16384, DET_RANGE_VELOCITY_234:16384, DET_RANGE_VELOCITY_235:16384, DET_RANGE_VELOCITY_236:16384, DET_RANGE_VELOCITY_ERR_233:0, DET_RANGE_VELOCITY_ERR_234:0, DET_RANGE_VELOCITY_ERR_235:0, DET_RANGE_VELOCITY_ERR_236:0, DET_RCS_233:128, DET_RCS_234:128, DET_RCS_235:128, DET_RCS_236:128, DET_SNR_233:0, DET_SNR_234:0, DET_SNR_235:0, DET_SNR_236:0, DET_SUPER_RES_TARGET_233:0, DET_SUPER_RES_TARGET_234:0, DET_SUPER_RES_TARGET_235:0, DET_SUPER_RES_TARGET_236:0]}, provided-interface=Pi_SG_Detections_233_236_AL
      Pp_SG_Detections_237_240_AL: nonqueued-sender-com-spec{data-element=Vdp_SG_Detections_237_240_AL, init-value=fields=[DET_AZIMUTH_237:0, DET_AZIMUTH_238:0, DET_AZIMUTH_239:0, DET_AZIMUTH_240:0, DET_AZIMUTH_ERR_237:0, DET_AZIMUTH_ERR_238:0, DET_AZIMUTH_ERR_239:0, DET_AZIMUTH_ERR_240:0, DET_BELOW_RAIN_THOLD_237:0, DET_BELOW_RAIN_THOLD_238:0, DET_BELOW_RAIN_THOLD_239:0, DET_BELOW_RAIN_THOLD_240:0, DET_BI_STATIC_FLAG_237:0, DET_BI_STATIC_FLAG_238:0, DET_BI_STATIC_FLAG_239:0, DET_BI_STATIC_FLAG_240:0, DET_CONFD_AZIMUTH_237:0, DET_CONFD_AZIMUTH_238:0, DET_CONFD_AZIMUTH_239:0, DET_CONFD_AZIMUTH_240:0, DET_CONFD_ELEVATION_237:0, DET_CONFD_ELEVATION_238:0, DET_CONFD_ELEVATION_239:0, DET_CONFD_ELEVATION_240:0, DET_ELEVATION_237:0, DET_ELEVATION_238:0, DET_ELEVATION_239:0, DET_ELEVATION_240:0, DET_ELEVATION_ERR_237:0, DET_ELEVATION_ERR_238:0, DET_ELEVATION_ERR_239:0, DET_ELEVATION_ERR_240:0, DET_EXISTENCE_PROB_237:0, DET_EXISTENCE_PROB_238:0, DET_EXISTENCE_PROB_239:0, DET_EXISTENCE_PROB_240:0, DET_HVC_FLAG_237:0, DET_HVC_FLAG_238:0, DET_HVC_FLAG_239:0, DET_HVC_FLAG_240:0, DET_IDM_237:0, DET_IDM_238:0, DET_IDM_239:0, DET_IDM_240:0, DET_MH_CRC16_237_240:0, DET_MH_CYCLE_COUNTER_237_240:0, DET_MH_SCAN_INDEX_4LSB_237_240:0, DET_MTD_237:0, DET_MTD_238:0, DET_MTD_239:0, DET_MTD_240:0, DET_PROB_1STAZHYPO_237:0, DET_PROB_1STAZHYPO_238:0, DET_PROB_1STAZHYPO_239:0, DET_PROB_1STAZHYPO_240:0, DET_RANGE_237:0, DET_RANGE_238:0, DET_RANGE_239:0, DET_RANGE_240:0, DET_RANGE_ERR_237:0, DET_RANGE_ERR_238:0, DET_RANGE_ERR_239:0, DET_RANGE_ERR_240:0, DET_RANGE_VELOCITY_237:16384, DET_RANGE_VELOCITY_238:16384, DET_RANGE_VELOCITY_239:16384, DET_RANGE_VELOCITY_240:16384, DET_RANGE_VELOCITY_ERR_237:0, DET_RANGE_VELOCITY_ERR_238:0, DET_RANGE_VELOCITY_ERR_239:0, DET_RANGE_VELOCITY_ERR_240:0, DET_RCS_237:128, DET_RCS_238:128, DET_RCS_239:128, DET_RCS_240:128, DET_SNR_237:0, DET_SNR_238:0, DET_SNR_239:0, DET_SNR_240:0, DET_SUPER_RES_TARGET_237:0, DET_SUPER_RES_TARGET_238:0, DET_SUPER_RES_TARGET_239:0, DET_SUPER_RES_TARGET_240:0]}, provided-interface=Pi_SG_Detections_237_240_AL
      Pp_SG_Detections_241_244_AL: nonqueued-sender-com-spec{data-element=Vdp_SG_Detections_241_244_AL, init-value=fields=[DET_AZIMUTH_241:0, DET_AZIMUTH_242:0, DET_AZIMUTH_243:0, DET_AZIMUTH_244:0, DET_AZIMUTH_ERR_241:0, DET_AZIMUTH_ERR_242:0, DET_AZIMUTH_ERR_243:0, DET_AZIMUTH_ERR_244:0, DET_BELOW_RAIN_THOLD_241:0, DET_BELOW_RAIN_THOLD_242:0, DET_BELOW_RAIN_THOLD_243:0, DET_BELOW_RAIN_THOLD_244:0, DET_BI_STATIC_FLAG_241:0, DET_BI_STATIC_FLAG_242:0, DET_BI_STATIC_FLAG_243:0, DET_BI_STATIC_FLAG_244:0, DET_CONFD_AZIMUTH_241:0, DET_CONFD_AZIMUTH_242:0, DET_CONFD_AZIMUTH_243:0, DET_CONFD_AZIMUTH_244:0, DET_CONFD_ELEVATION_241:0, DET_CONFD_ELEVATION_242:0, DET_CONFD_ELEVATION_243:0, DET_CONFD_ELEVATION_244:0, DET_ELEVATION_241:0, DET_ELEVATION_242:0, DET_ELEVATION_243:0, DET_ELEVATION_244:0, DET_ELEVATION_ERR_241:0, DET_ELEVATION_ERR_242:0, DET_ELEVATION_ERR_243:0, DET_ELEVATION_ERR_244:0, DET_EXISTENCE_PROB_241:0, DET_EXISTENCE_PROB_242:0, DET_EXISTENCE_PROB_243:0, DET_EXISTENCE_PROB_244:0, DET_HVC_FLAG_241:0, DET_HVC_FLAG_242:0, DET_HVC_FLAG_243:0, DET_HVC_FLAG_244:0, DET_IDM_241:0, DET_IDM_242:0, DET_IDM_243:0, DET_IDM_244:0, DET_MH_CRC16_241_244:0, DET_MH_CYCLE_COUNTER_241_244:0, DET_MH_SCAN_INDEX_4LSB_241_244:0, DET_MTD_241:0, DET_MTD_242:0, DET_MTD_243:0, DET_MTD_244:0, DET_PROB_1STAZHYPO_241:0, DET_PROB_1STAZHYPO_242:0, DET_PROB_1STAZHYPO_243:0, DET_PROB_1STAZHYPO_244:0, DET_RANGE_241:0, DET_RANGE_242:0, DET_RANGE_243:0, DET_RANGE_244:0, DET_RANGE_ERR_241:0, DET_RANGE_ERR_242:0, DET_RANGE_ERR_243:0, DET_RANGE_ERR_244:0, DET_RANGE_VELOCITY_241:16384, DET_RANGE_VELOCITY_242:16384, DET_RANGE_VELOCITY_243:16384, DET_RANGE_VELOCITY_244:16384, DET_RANGE_VELOCITY_ERR_241:0, DET_RANGE_VELOCITY_ERR_242:0, DET_RANGE_VELOCITY_ERR_243:0, DET_RANGE_VELOCITY_ERR_244:0, DET_RCS_241:128, DET_RCS_242:128, DET_RCS_243:128, DET_RCS_244:128, DET_SNR_241:0, DET_SNR_242:0, DET_SNR_243:0, DET_SNR_244:0, DET_SUPER_RES_TARGET_241:0, DET_SUPER_RES_TARGET_242:0, DET_SUPER_RES_TARGET_243:0, DET_SUPER_RES_TARGET_244:0]}, provided-interface=Pi_SG_Detections_241_244_AL
      Pp_SG_Detections_245_248_AL: nonqueued-sender-com-spec{data-element=Vdp_SG_Detections_245_248_AL, init-value=fields=[DET_AZIMUTH_245:0, DET_AZIMUTH_246:0, DET_AZIMUTH_247:0, DET_AZIMUTH_248:0, DET_AZIMUTH_ERR_245:0, DET_AZIMUTH_ERR_246:0, DET_AZIMUTH_ERR_247:0, DET_AZIMUTH_ERR_248:0, DET_BELOW_RAIN_THOLD_245:0, DET_BELOW_RAIN_THOLD_246:0, DET_BELOW_RAIN_THOLD_247:0, DET_BELOW_RAIN_THOLD_248:0, DET_BI_STATIC_FLAG_245:0, DET_BI_STATIC_FLAG_246:0, DET_BI_STATIC_FLAG_247:0, DET_BI_STATIC_FLAG_248:0, DET_CONFD_AZIMUTH_245:0, DET_CONFD_AZIMUTH_246:0, DET_CONFD_AZIMUTH_247:0, DET_CONFD_AZIMUTH_248:0, DET_CONFD_ELEVATION_245:0, DET_CONFD_ELEVATION_246:0, DET_CONFD_ELEVATION_247:0, DET_CONFD_ELEVATION_248:0, DET_ELEVATION_245:0, DET_ELEVATION_246:0, DET_ELEVATION_247:0, DET_ELEVATION_248:0, DET_ELEVATION_ERR_245:0, DET_ELEVATION_ERR_246:0, DET_ELEVATION_ERR_247:0, DET_ELEVATION_ERR_248:0, DET_EXISTENCE_PROB_245:0, DET_EXISTENCE_PROB_246:0, DET_EXISTENCE_PROB_247:0, DET_EXISTENCE_PROB_248:0, DET_HVC_FLAG_245:0, DET_HVC_FLAG_246:0, DET_HVC_FLAG_247:0, DET_HVC_FLAG_248:0, DET_IDM_245:0, DET_IDM_246:0, DET_IDM_247:0, DET_IDM_248:0, DET_MH_CRC16_245_248:0, DET_MH_CYCLE_COUNTER_245_248:0, DET_MH_SCAN_INDEX_4LSB_245_248:0, DET_MTD_245:0, DET_MTD_246:0, DET_MTD_247:0, DET_MTD_248:0, DET_PROB_1STAZHYPO_245:0, DET_PROB_1STAZHYPO_246:0, DET_PROB_1STAZHYPO_247:0, DET_PROB_1STAZHYPO_248:0, DET_RANGE_245:0, DET_RANGE_246:0, DET_RANGE_247:0, DET_RANGE_248:0, DET_RANGE_ERR_245:0, DET_RANGE_ERR_246:0, DET_RANGE_ERR_247:0, DET_RANGE_ERR_248:0, DET_RANGE_VELOCITY_245:16384, DET_RANGE_VELOCITY_246:16384, DET_RANGE_VELOCITY_247:16384, DET_RANGE_VELOCITY_248:16384, DET_RANGE_VELOCITY_ERR_245:0, DET_RANGE_VELOCITY_ERR_246:0, DET_RANGE_VELOCITY_ERR_247:0, DET_RANGE_VELOCITY_ERR_248:0, DET_RCS_245:128, DET_RCS_246:128, DET_RCS_247:128, DET_RCS_248:128, DET_SNR_245:0, DET_SNR_246:0, DET_SNR_247:0, DET_SNR_248:0, DET_SUPER_RES_TARGET_245:0, DET_SUPER_RES_TARGET_246:0, DET_SUPER_RES_TARGET_247:0, DET_SUPER_RES_TARGET_248:0]}, provided-interface=Pi_SG_Detections_245_248_AL
      Pp_SG_Detections_249_252_AL: nonqueued-sender-com-spec{data-element=Vdp_SG_Detections_249_252_AL, init-value=fields=[DET_AZIMUTH_249:0, DET_AZIMUTH_250:0, DET_AZIMUTH_251:0, DET_AZIMUTH_252:0, DET_AZIMUTH_ERR_249:0, DET_AZIMUTH_ERR_250:0, DET_AZIMUTH_ERR_251:0, DET_AZIMUTH_ERR_252:0, DET_BELOW_RAIN_THOLD_249:0, DET_BELOW_RAIN_THOLD_250:0, DET_BELOW_RAIN_THOLD_251:0, DET_BELOW_RAIN_THOLD_252:0, DET_BI_STATIC_FLAG_249:0, DET_BI_STATIC_FLAG_250:0, DET_BI_STATIC_FLAG_251:0, DET_BI_STATIC_FLAG_252:0, DET_CONFD_AZIMUTH_249:0, DET_CONFD_AZIMUTH_250:0, DET_CONFD_AZIMUTH_251:0, DET_CONFD_AZIMUTH_252:0, DET_CONFD_ELEVATION_249:0, DET_CONFD_ELEVATION_250:0, DET_CONFD_ELEVATION_251:0, DET_CONFD_ELEVATION_252:0, DET_ELEVATION_249:0, DET_ELEVATION_250:0, DET_ELEVATION_251:0, DET_ELEVATION_252:0, DET_ELEVATION_ERR_249:0, DET_ELEVATION_ERR_250:0, DET_ELEVATION_ERR_251:0, DET_ELEVATION_ERR_252:0, DET_EXISTENCE_PROB_249:0, DET_EXISTENCE_PROB_250:0, DET_EXISTENCE_PROB_251:0, DET_EXISTENCE_PROB_252:0, DET_HVC_FLAG_249:0, DET_HVC_FLAG_250:0, DET_HVC_FLAG_251:0, DET_HVC_FLAG_252:0, DET_IDM_249:0, DET_IDM_250:0, DET_IDM_251:0, DET_IDM_252:0, DET_MH_CRC16_249_252:0, DET_MH_CYCLE_COUNTER_249_252:0, DET_MH_SCAN_INDEX_4LSB_249_252:0, DET_MTD_249:0, DET_MTD_250:0, DET_MTD_251:0, DET_MTD_252:0, DET_PROB_1STAZHYPO_249:0, DET_PROB_1STAZHYPO_250:0, DET_PROB_1STAZHYPO_251:0, DET_PROB_1STAZHYPO_252:0, DET_RANGE_249:0, DET_RANGE_250:0, DET_RANGE_251:0, DET_RANGE_252:0, DET_RANGE_ERR_249:0, DET_RANGE_ERR_250:0, DET_RANGE_ERR_251:0, DET_RANGE_ERR_252:0, DET_RANGE_VELOCITY_249:16384, DET_RANGE_VELOCITY_250:16384, DET_RANGE_VELOCITY_251:16384, DET_RANGE_VELOCITY_252:16384, DET_RANGE_VELOCITY_ERR_249:0, DET_RANGE_VELOCITY_ERR_250:0, DET_RANGE_VELOCITY_ERR_251:0, DET_RANGE_VELOCITY_ERR_252:0, DET_RCS_249:128, DET_RCS_250:128, DET_RCS_251:128, DET_RCS_252:128, DET_SNR_249:0, DET_SNR_250:0, DET_SNR_251:0, DET_SNR_252:0, DET_SUPER_RES_TARGET_249:0, DET_SUPER_RES_TARGET_250:0, DET_SUPER_RES_TARGET_251:0, DET_SUPER_RES_TARGET_252:0]}, provided-interface=Pi_SG_Detections_249_252_AL
      Pp_SG_Detections_253_256_AL: nonqueued-sender-com-spec{data-element=Vdp_SG_Detections_253_256_AL, init-value=fields=[DET_AZIMUTH_253:0, DET_AZIMUTH_254:0, DET_AZIMUTH_255:0, DET_AZIMUTH_256:0, DET_AZIMUTH_ERR_253:0, DET_AZIMUTH_ERR_254:0, DET_AZIMUTH_ERR_255:0, DET_AZIMUTH_ERR_256:0, DET_BELOW_RAIN_THOLD_253:0, DET_BELOW_RAIN_THOLD_254:0, DET_BELOW_RAIN_THOLD_255:0, DET_BELOW_RAIN_THOLD_256:0, DET_BI_STATIC_FLAG_253:0, DET_BI_STATIC_FLAG_254:0, DET_BI_STATIC_FLAG_255:0, DET_BI_STATIC_FLAG_256:0, DET_CONFD_AZIMUTH_253:0, DET_CONFD_AZIMUTH_254:0, DET_CONFD_AZIMUTH_255:0, DET_CONFD_AZIMUTH_256:0, DET_CONFD_ELEVATION_253:0, DET_CONFD_ELEVATION_254:0, DET_CONFD_ELEVATION_255:0, DET_CONFD_ELEVATION_256:0, DET_ELEVATION_253:0, DET_ELEVATION_254:0, DET_ELEVATION_255:0, DET_ELEVATION_256:0, DET_ELEVATION_ERR_253:0, DET_ELEVATION_ERR_254:0, DET_ELEVATION_ERR_255:0, DET_ELEVATION_ERR_256:0, DET_EXISTENCE_PROB_253:0, DET_EXISTENCE_PROB_254:0, DET_EXISTENCE_PROB_255:0, DET_EXISTENCE_PROB_256:0, DET_HVC_FLAG_253:0, DET_HVC_FLAG_254:0, DET_HVC_FLAG_255:0, DET_HVC_FLAG_256:0, DET_IDM_253:0, DET_IDM_254:0, DET_IDM_255:0, DET_IDM_256:0, DET_MH_CRC16_253_256:0, DET_MH_CYCLE_COUNTER_253_256:0, DET_MH_SCAN_INDEX_4LSB_253_256:0, DET_MTD_253:0, DET_MTD_254:0, DET_MTD_255:0, DET_MTD_256:0, DET_PROB_1STAZHYPO_253:0, DET_PROB_1STAZHYPO_254:0, DET_PROB_1STAZHYPO_255:0, DET_PROB_1STAZHYPO_256:0, DET_RANGE_253:0, DET_RANGE_254:0, DET_RANGE_255:0, DET_RANGE_256:0, DET_RANGE_ERR_253:0, DET_RANGE_ERR_254:0, DET_RANGE_ERR_255:0, DET_RANGE_ERR_256:0, DET_RANGE_VELOCITY_253:16384, DET_RANGE_VELOCITY_254:16384, DET_RANGE_VELOCITY_255:16384, DET_RANGE_VELOCITY_256:16384, DET_RANGE_VELOCITY_ERR_253:0, DET_RANGE_VELOCITY_ERR_254:0, DET_RANGE_VELOCITY_ERR_255:0, DET_RANGE_VELOCITY_ERR_256:0, DET_RCS_253:128, DET_RCS_254:128, DET_RCS_255:128, DET_RCS_256:128, DET_SNR_253:0, DET_SNR_254:0, DET_SNR_255:0, DET_SNR_256:0, DET_SUPER_RES_TARGET_253:0, DET_SUPER_RES_TARGET_254:0, DET_SUPER_RES_TARGET_255:0, DET_SUPER_RES_TARGET_256:0]}, provided-interface=Pi_SG_Detections_253_256_AL
      Pp_SG_Detections_257_260_AL: nonqueued-sender-com-spec{data-element=Vdp_SG_Detections_257_260_AL, init-value=fields=[DET_AZIMUTH_257:0, DET_AZIMUTH_258:0, DET_AZIMUTH_259:0, DET_AZIMUTH_260:0, DET_AZIMUTH_ERR_257:0, DET_AZIMUTH_ERR_258:0, DET_AZIMUTH_ERR_259:0, DET_AZIMUTH_ERR_260:0, DET_BELOW_RAIN_THOLD_257:0, DET_BELOW_RAIN_THOLD_258:0, DET_BELOW_RAIN_THOLD_259:0, DET_BELOW_RAIN_THOLD_260:0, DET_BI_STATIC_FLAG_257:0, DET_BI_STATIC_FLAG_258:0, DET_BI_STATIC_FLAG_259:0, DET_BI_STATIC_FLAG_260:0, DET_CONFD_AZIMUTH_257:0, DET_CONFD_AZIMUTH_258:0, DET_CONFD_AZIMUTH_259:0, DET_CONFD_AZIMUTH_260:0, DET_CONFD_ELEVATION_257:0, DET_CONFD_ELEVATION_258:0, DET_CONFD_ELEVATION_259:0, DET_CONFD_ELEVATION_260:0, DET_ELEVATION_257:0, DET_ELEVATION_258:0, DET_ELEVATION_259:0, DET_ELEVATION_260:0, DET_ELEVATION_ERR_257:0, DET_ELEVATION_ERR_258:0, DET_ELEVATION_ERR_259:0, DET_ELEVATION_ERR_260:0, DET_EXISTENCE_PROB_257:0, DET_EXISTENCE_PROB_258:0, DET_EXISTENCE_PROB_259:0, DET_EXISTENCE_PROB_260:0, DET_HVC_FLAG_257:0, DET_HVC_FLAG_258:0, DET_HVC_FLAG_259:0, DET_HVC_FLAG_260:0, DET_IDM_257:0, DET_IDM_258:0, DET_IDM_259:0, DET_IDM_260:0, DET_MH_CRC16_257_260:0, DET_MH_CYCLE_COUNTER_257_260:0, DET_MH_SCAN_INDEX_4LSB_257_260:0, DET_MTD_257:0, DET_MTD_258:0, DET_MTD_259:0, DET_MTD_260:0, DET_PROB_1STAZHYPO_257:0, DET_PROB_1STAZHYPO_258:0, DET_PROB_1STAZHYPO_259:0, DET_PROB_1STAZHYPO_260:0, DET_RANGE_257:0, DET_RANGE_258:0, DET_RANGE_259:0, DET_RANGE_260:0, DET_RANGE_ERR_257:0, DET_RANGE_ERR_258:0, DET_RANGE_ERR_259:0, DET_RANGE_ERR_260:0, DET_RANGE_VELOCITY_257:16384, DET_RANGE_VELOCITY_258:16384, DET_RANGE_VELOCITY_259:16384, DET_RANGE_VELOCITY_260:16384, DET_RANGE_VELOCITY_ERR_257:0, DET_RANGE_VELOCITY_ERR_258:0, DET_RANGE_VELOCITY_ERR_259:0, DET_RANGE_VELOCITY_ERR_260:0, DET_RCS_257:128, DET_RCS_258:128, DET_RCS_259:128, DET_RCS_260:128, DET_SNR_257:0, DET_SNR_258:0, DET_SNR_259:0, DET_SNR_260:0, DET_SUPER_RES_TARGET_257:0, DET_SUPER_RES_TARGET_258:0, DET_SUPER_RES_TARGET_259:0, DET_SUPER_RES_TARGET_260:0]}, provided-interface=Pi_SG_Detections_257_260_AL
      Pp_SG_Detections_261_264_AL: nonqueued-sender-com-spec{data-element=Vdp_SG_Detections_261_264_AL, init-value=fields=[DET_AZIMUTH_261:0, DET_AZIMUTH_262:0, DET_AZIMUTH_263:0, DET_AZIMUTH_264:0, DET_AZIMUTH_ERR_261:0, DET_AZIMUTH_ERR_262:0, DET_AZIMUTH_ERR_263:0, DET_AZIMUTH_ERR_264:0, DET_BELOW_RAIN_THOLD_261:0, DET_BELOW_RAIN_THOLD_262:0, DET_BELOW_RAIN_THOLD_263:0, DET_BELOW_RAIN_THOLD_264:0, DET_BI_STATIC_FLAG_261:0, DET_BI_STATIC_FLAG_262:0, DET_BI_STATIC_FLAG_263:0, DET_BI_STATIC_FLAG_264:0, DET_CONFD_AZIMUTH_261:0, DET_CONFD_AZIMUTH_262:0, DET_CONFD_AZIMUTH_263:0, DET_CONFD_AZIMUTH_264:0, DET_CONFD_ELEVATION_261:0, DET_CONFD_ELEVATION_262:0, DET_CONFD_ELEVATION_263:0, DET_CONFD_ELEVATION_264:0, DET_ELEVATION_261:0, DET_ELEVATION_262:0, DET_ELEVATION_263:0, DET_ELEVATION_264:0, DET_ELEVATION_ERR_261:0, DET_ELEVATION_ERR_262:0, DET_ELEVATION_ERR_263:0, DET_ELEVATION_ERR_264:0, DET_EXISTENCE_PROB_261:0, DET_EXISTENCE_PROB_262:0, DET_EXISTENCE_PROB_263:0, DET_EXISTENCE_PROB_264:0, DET_HVC_FLAG_261:0, DET_HVC_FLAG_262:0, DET_HVC_FLAG_263:0, DET_HVC_FLAG_264:0, DET_IDM_261:0, DET_IDM_262:0, DET_IDM_263:0, DET_IDM_264:0, DET_MH_CRC16_261_264:0, DET_MH_CYCLE_COUNTER_261_264:0, DET_MH_SCAN_INDEX_4LSB_261_264:0, DET_MTD_261:0, DET_MTD_262:0, DET_MTD_263:0, DET_MTD_264:0, DET_PROB_1STAZHYPO_261:0, DET_PROB_1STAZHYPO_262:0, DET_PROB_1STAZHYPO_263:0, DET_PROB_1STAZHYPO_264:0, DET_RANGE_261:0, DET_RANGE_262:0, DET_RANGE_263:0, DET_RANGE_264:0, DET_RANGE_ERR_261:0, DET_RANGE_ERR_262:0, DET_RANGE_ERR_263:0, DET_RANGE_ERR_264:0, DET_RANGE_VELOCITY_261:16384, DET_RANGE_VELOCITY_262:16384, DET_RANGE_VELOCITY_263:16384, DET_RANGE_VELOCITY_264:16384, DET_RANGE_VELOCITY_ERR_261:0, DET_RANGE_VELOCITY_ERR_262:0, DET_RANGE_VELOCITY_ERR_263:0, DET_RANGE_VELOCITY_ERR_264:0, DET_RCS_261:128, DET_RCS_262:128, DET_RCS_263:128, DET_RCS_264:128, DET_SNR_261:0, DET_SNR_262:0, DET_SNR_263:0, DET_SNR_264:0, DET_SUPER_RES_TARGET_261:0, DET_SUPER_RES_TARGET_262:0, DET_SUPER_RES_TARGET_263:0, DET_SUPER_RES_TARGET_264:0]}, provided-interface=Pi_SG_Detections_261_264_AL
      Pp_SG_Detections_265_268_AL: nonqueued-sender-com-spec{data-element=Vdp_SG_Detections_265_268_AL, init-value=fields=[DET_AZIMUTH_265:0, DET_AZIMUTH_266:0, DET_AZIMUTH_267:0, DET_AZIMUTH_268:0, DET_AZIMUTH_ERR_265:0, DET_AZIMUTH_ERR_266:0, DET_AZIMUTH_ERR_267:0, DET_AZIMUTH_ERR_268:0, DET_BELOW_RAIN_THOLD_265:0, DET_BELOW_RAIN_THOLD_266:0, DET_BELOW_RAIN_THOLD_267:0, DET_BELOW_RAIN_THOLD_268:0, DET_BI_STATIC_FLAG_265:0, DET_BI_STATIC_FLAG_266:0, DET_BI_STATIC_FLAG_267:0, DET_BI_STATIC_FLAG_268:0, DET_CONFD_AZIMUTH_265:0, DET_CONFD_AZIMUTH_266:0, DET_CONFD_AZIMUTH_267:0, DET_CONFD_AZIMUTH_268:0, DET_CONFD_ELEVATION_265:0, DET_CONFD_ELEVATION_266:0, DET_CONFD_ELEVATION_267:0, DET_CONFD_ELEVATION_268:0, DET_ELEVATION_265:0, DET_ELEVATION_266:0, DET_ELEVATION_267:0, DET_ELEVATION_268:0, DET_ELEVATION_ERR_265:0, DET_ELEVATION_ERR_266:0, DET_ELEVATION_ERR_267:0, DET_ELEVATION_ERR_268:0, DET_EXISTENCE_PROB_265:0, DET_EXISTENCE_PROB_266:0, DET_EXISTENCE_PROB_267:0, DET_EXISTENCE_PROB_268:0, DET_HVC_FLAG_265:0, DET_HVC_FLAG_266:0, DET_HVC_FLAG_267:0, DET_HVC_FLAG_268:0, DET_IDM_265:0, DET_IDM_266:0, DET_IDM_267:0, DET_IDM_268:0, DET_MH_CRC16_265_268:0, DET_MH_CYCLE_COUNTER_265_268:0, DET_MH_SCAN_INDEX_4LSB_265_268:0, DET_MTD_265:0, DET_MTD_266:0, DET_MTD_267:0, DET_MTD_268:0, DET_PROB_1STAZHYPO_265:0, DET_PROB_1STAZHYPO_266:0, DET_PROB_1STAZHYPO_267:0, DET_PROB_1STAZHYPO_268:0, DET_RANGE_265:0, DET_RANGE_266:0, DET_RANGE_267:0, DET_RANGE_268:0, DET_RANGE_ERR_265:0, DET_RANGE_ERR_266:0, DET_RANGE_ERR_267:0, DET_RANGE_ERR_268:0, DET_RANGE_VELOCITY_265:16384, DET_RANGE_VELOCITY_266:16384, DET_RANGE_VELOCITY_267:16384, DET_RANGE_VELOCITY_268:16384, DET_RANGE_VELOCITY_ERR_265:0, DET_RANGE_VELOCITY_ERR_266:0, DET_RANGE_VELOCITY_ERR_267:0, DET_RANGE_VELOCITY_ERR_268:0, DET_RCS_265:128, DET_RCS_266:128, DET_RCS_267:128, DET_RCS_268:128, DET_SNR_265:0, DET_SNR_266:0, DET_SNR_267:0, DET_SNR_268:0, DET_SUPER_RES_TARGET_265:0, DET_SUPER_RES_TARGET_266:0, DET_SUPER_RES_TARGET_267:0, DET_SUPER_RES_TARGET_268:0]}, provided-interface=Pi_SG_Detections_265_268_AL
      Pp_SG_Detections_269_272_AL: nonqueued-sender-com-spec{data-element=Vdp_SG_Detections_269_272_AL, init-value=fields=[DET_AZIMUTH_269:0, DET_AZIMUTH_270:0, DET_AZIMUTH_271:0, DET_AZIMUTH_272:0, DET_AZIMUTH_ERR_269:0, DET_AZIMUTH_ERR_270:0, DET_AZIMUTH_ERR_271:0, DET_AZIMUTH_ERR_272:0, DET_BELOW_RAIN_THOLD_269:0, DET_BELOW_RAIN_THOLD_270:0, DET_BELOW_RAIN_THOLD_271:0, DET_BELOW_RAIN_THOLD_272:0, DET_BI_STATIC_FLAG_269:0, DET_BI_STATIC_FLAG_270:0, DET_BI_STATIC_FLAG_271:0, DET_BI_STATIC_FLAG_272:0, DET_CONFD_AZIMUTH_269:0, DET_CONFD_AZIMUTH_270:0, DET_CONFD_AZIMUTH_271:0, DET_CONFD_AZIMUTH_272:0, DET_CONFD_ELEVATION_269:0, DET_CONFD_ELEVATION_270:0, DET_CONFD_ELEVATION_271:0, DET_CONFD_ELEVATION_272:0, DET_ELEVATION_269:0, DET_ELEVATION_270:0, DET_ELEVATION_271:0, DET_ELEVATION_272:0, DET_ELEVATION_ERR_269:0, DET_ELEVATION_ERR_270:0, DET_ELEVATION_ERR_271:0, DET_ELEVATION_ERR_272:0, DET_EXISTENCE_PROB_269:0, DET_EXISTENCE_PROB_270:0, DET_EXISTENCE_PROB_271:0, DET_EXISTENCE_PROB_272:0, DET_HVC_FLAG_269:0, DET_HVC_FLAG_270:0, DET_HVC_FLAG_271:0, DET_HVC_FLAG_272:0, DET_IDM_269:0, DET_IDM_270:0, DET_IDM_271:0, DET_IDM_272:0, DET_MH_CRC16_269_272:0, DET_MH_CYCLE_COUNTER_269_272:0, DET_MH_SCAN_INDEX_4LSB_269_272:0, DET_MTD_269:0, DET_MTD_270:0, DET_MTD_271:0, DET_MTD_272:0, DET_PROB_1STAZHYPO_269:0, DET_PROB_1STAZHYPO_270:0, DET_PROB_1STAZHYPO_271:0, DET_PROB_1STAZHYPO_272:0, DET_RANGE_269:0, DET_RANGE_270:0, DET_RANGE_271:0, DET_RANGE_272:0, DET_RANGE_ERR_269:0, DET_RANGE_ERR_270:0, DET_RANGE_ERR_271:0, DET_RANGE_ERR_272:0, DET_RANGE_VELOCITY_269:16384, DET_RANGE_VELOCITY_270:16384, DET_RANGE_VELOCITY_271:16384, DET_RANGE_VELOCITY_272:16384, DET_RANGE_VELOCITY_ERR_269:0, DET_RANGE_VELOCITY_ERR_270:0, DET_RANGE_VELOCITY_ERR_271:0, DET_RANGE_VELOCITY_ERR_272:0, DET_RCS_269:128, DET_RCS_270:128, DET_RCS_271:128, DET_RCS_272:128, DET_SNR_269:0, DET_SNR_270:0, DET_SNR_271:0, DET_SNR_272:0, DET_SUPER_RES_TARGET_269:0, DET_SUPER_RES_TARGET_270:0, DET_SUPER_RES_TARGET_271:0, DET_SUPER_RES_TARGET_272:0]}, provided-interface=Pi_SG_Detections_269_272_AL
      Pp_SG_Detections_273_276_AL: nonqueued-sender-com-spec{data-element=Vdp_SG_Detections_273_276_AL, init-value=fields=[DET_AZIMUTH_273:0, DET_AZIMUTH_274:0, DET_AZIMUTH_275:0, DET_AZIMUTH_276:0, DET_AZIMUTH_ERR_273:0, DET_AZIMUTH_ERR_274:0, DET_AZIMUTH_ERR_275:0, DET_AZIMUTH_ERR_276:0, DET_BELOW_RAIN_THOLD_273:0, DET_BELOW_RAIN_THOLD_274:0, DET_BELOW_RAIN_THOLD_275:0, DET_BELOW_RAIN_THOLD_276:0, DET_BI_STATIC_FLAG_273:0, DET_BI_STATIC_FLAG_274:0, DET_BI_STATIC_FLAG_275:0, DET_BI_STATIC_FLAG_276:0, DET_CONFD_AZIMUTH_273:0, DET_CONFD_AZIMUTH_274:0, DET_CONFD_AZIMUTH_275:0, DET_CONFD_AZIMUTH_276:0, DET_CONFD_ELEVATION_273:0, DET_CONFD_ELEVATION_274:0, DET_CONFD_ELEVATION_275:0, DET_CONFD_ELEVATION_276:0, DET_ELEVATION_273:0, DET_ELEVATION_274:0, DET_ELEVATION_275:0, DET_ELEVATION_276:0, DET_ELEVATION_ERR_273:0, DET_ELEVATION_ERR_274:0, DET_ELEVATION_ERR_275:0, DET_ELEVATION_ERR_276:0, DET_EXISTENCE_PROB_273:0, DET_EXISTENCE_PROB_274:0, DET_EXISTENCE_PROB_275:0, DET_EXISTENCE_PROB_276:0, DET_HVC_FLAG_273:0, DET_HVC_FLAG_274:0, DET_HVC_FLAG_275:0, DET_HVC_FLAG_276:0, DET_IDM_273:0, DET_IDM_274:0, DET_IDM_275:0, DET_IDM_276:0, DET_MH_CRC16_273_276:0, DET_MH_CYCLE_COUNTER_273_276:0, DET_MH_SCAN_INDEX_4LSB_273_276:0, DET_MTD_273:0, DET_MTD_274:0, DET_MTD_275:0, DET_MTD_276:0, DET_PROB_1STAZHYPO_273:0, DET_PROB_1STAZHYPO_274:0, DET_PROB_1STAZHYPO_275:0, DET_PROB_1STAZHYPO_276:0, DET_RANGE_273:0, DET_RANGE_274:0, DET_RANGE_275:0, DET_RANGE_276:0, DET_RANGE_ERR_273:0, DET_RANGE_ERR_274:0, DET_RANGE_ERR_275:0, DET_RANGE_ERR_276:0, DET_RANGE_VELOCITY_273:16384, DET_RANGE_VELOCITY_274:16384, DET_RANGE_VELOCITY_275:16384, DET_RANGE_VELOCITY_276:16384, DET_RANGE_VELOCITY_ERR_273:0, DET_RANGE_VELOCITY_ERR_274:0, DET_RANGE_VELOCITY_ERR_275:0, DET_RANGE_VELOCITY_ERR_276:0, DET_RCS_273:128, DET_RCS_274:128, DET_RCS_275:128, DET_RCS_276:128, DET_SNR_273:0, DET_SNR_274:0, DET_SNR_275:0, DET_SNR_276:0, DET_SUPER_RES_TARGET_273:0, DET_SUPER_RES_TARGET_274:0, DET_SUPER_RES_TARGET_275:0, DET_SUPER_RES_TARGET_276:0]}, provided-interface=Pi_SG_Detections_273_276_AL
      Pp_SG_Detections_277_280_AL: nonqueued-sender-com-spec{data-element=Vdp_SG_Detections_277_280_AL, init-value=fields=[DET_AZIMUTH_277:0, DET_AZIMUTH_278:0, DET_AZIMUTH_279:0, DET_AZIMUTH_280:0, DET_AZIMUTH_ERR_277:0, DET_AZIMUTH_ERR_278:0, DET_AZIMUTH_ERR_279:0, DET_AZIMUTH_ERR_280:0, DET_BELOW_RAIN_THOLD_277:0, DET_BELOW_RAIN_THOLD_278:0, DET_BELOW_RAIN_THOLD_279:0, DET_BELOW_RAIN_THOLD_280:0, DET_BI_STATIC_FLAG_277:0, DET_BI_STATIC_FLAG_278:0, DET_BI_STATIC_FLAG_279:0, DET_BI_STATIC_FLAG_280:0, DET_CONFD_AZIMUTH_277:0, DET_CONFD_AZIMUTH_278:0, DET_CONFD_AZIMUTH_279:0, DET_CONFD_AZIMUTH_280:0, DET_CONFD_ELEVATION_277:0, DET_CONFD_ELEVATION_278:0, DET_CONFD_ELEVATION_279:0, DET_CONFD_ELEVATION_280:0, DET_ELEVATION_277:0, DET_ELEVATION_278:0, DET_ELEVATION_279:0, DET_ELEVATION_280:0, DET_ELEVATION_ERR_277:0, DET_ELEVATION_ERR_278:0, DET_ELEVATION_ERR_279:0, DET_ELEVATION_ERR_280:0, DET_EXISTENCE_PROB_277:0, DET_EXISTENCE_PROB_278:0, DET_EXISTENCE_PROB_279:0, DET_EXISTENCE_PROB_280:0, DET_HVC_FLAG_277:0, DET_HVC_FLAG_278:0, DET_HVC_FLAG_279:0, DET_HVC_FLAG_280:0, DET_IDM_277:0, DET_IDM_278:0, DET_IDM_279:0, DET_IDM_280:0, DET_MH_CRC16_277_280:0, DET_MH_CYCLE_COUNTER_277_280:0, DET_MH_SCAN_INDEX_4LSB_277_280:0, DET_MTD_277:0, DET_MTD_278:0, DET_MTD_279:0, DET_MTD_280:0, DET_PROB_1STAZHYPO_277:0, DET_PROB_1STAZHYPO_278:0, DET_PROB_1STAZHYPO_279:0, DET_PROB_1STAZHYPO_280:0, DET_RANGE_277:0, DET_RANGE_278:0, DET_RANGE_279:0, DET_RANGE_280:0, DET_RANGE_ERR_277:0, DET_RANGE_ERR_278:0, DET_RANGE_ERR_279:0, DET_RANGE_ERR_280:0, DET_RANGE_VELOCITY_277:16384, DET_RANGE_VELOCITY_278:16384, DET_RANGE_VELOCITY_279:16384, DET_RANGE_VELOCITY_280:16384, DET_RANGE_VELOCITY_ERR_277:0, DET_RANGE_VELOCITY_ERR_278:0, DET_RANGE_VELOCITY_ERR_279:0, DET_RANGE_VELOCITY_ERR_280:0, DET_RCS_277:128, DET_RCS_278:128, DET_RCS_279:128, DET_RCS_280:128, DET_SNR_277:0, DET_SNR_278:0, DET_SNR_279:0, DET_SNR_280:0, DET_SUPER_RES_TARGET_277:0, DET_SUPER_RES_TARGET_278:0, DET_SUPER_RES_TARGET_279:0, DET_SUPER_RES_TARGET_280:0]}, provided-interface=Pi_SG_Detections_277_280_AL
      Pp_SG_Detections_281_284_AL: nonqueued-sender-com-spec{data-element=Vdp_SG_Detections_281_284_AL, init-value=fields=[DET_AZIMUTH_281:0, DET_AZIMUTH_282:0, DET_AZIMUTH_283:0, DET_AZIMUTH_284:0, DET_AZIMUTH_ERR_281:0, DET_AZIMUTH_ERR_282:0, DET_AZIMUTH_ERR_283:0, DET_AZIMUTH_ERR_284:0, DET_BELOW_RAIN_THOLD_281:0, DET_BELOW_RAIN_THOLD_282:0, DET_BELOW_RAIN_THOLD_283:0, DET_BELOW_RAIN_THOLD_284:0, DET_BI_STATIC_FLAG_281:0, DET_BI_STATIC_FLAG_282:0, DET_BI_STATIC_FLAG_283:0, DET_BI_STATIC_FLAG_284:0, DET_CONFD_AZIMUTH_281:0, DET_CONFD_AZIMUTH_282:0, DET_CONFD_AZIMUTH_283:0, DET_CONFD_AZIMUTH_284:0, DET_CONFD_ELEVATION_281:0, DET_CONFD_ELEVATION_282:0, DET_CONFD_ELEVATION_283:0, DET_CONFD_ELEVATION_284:0, DET_ELEVATION_281:0, DET_ELEVATION_282:0, DET_ELEVATION_283:0, DET_ELEVATION_284:0, DET_ELEVATION_ERR_281:0, DET_ELEVATION_ERR_282:0, DET_ELEVATION_ERR_283:0, DET_ELEVATION_ERR_284:0, DET_EXISTENCE_PROB_281:0, DET_EXISTENCE_PROB_282:0, DET_EXISTENCE_PROB_283:0, DET_EXISTENCE_PROB_284:0, DET_HVC_FLAG_281:0, DET_HVC_FLAG_282:0, DET_HVC_FLAG_283:0, DET_HVC_FLAG_284:0, DET_IDM_281:0, DET_IDM_282:0, DET_IDM_283:0, DET_IDM_284:0, DET_MH_CRC16_281_284:0, DET_MH_CYCLE_COUNTER_281_284:0, DET_MH_SCAN_INDEX_4LSB_281_284:0, DET_MTD_281:0, DET_MTD_282:0, DET_MTD_283:0, DET_MTD_284:0, DET_PROB_1STAZHYPO_281:0, DET_PROB_1STAZHYPO_282:0, DET_PROB_1STAZHYPO_283:0, DET_PROB_1STAZHYPO_284:0, DET_RANGE_281:0, DET_RANGE_282:0, DET_RANGE_283:0, DET_RANGE_284:0, DET_RANGE_ERR_281:0, DET_RANGE_ERR_282:0, DET_RANGE_ERR_283:0, DET_RANGE_ERR_284:0, DET_RANGE_VELOCITY_281:16384, DET_RANGE_VELOCITY_282:16384, DET_RANGE_VELOCITY_283:16384, DET_RANGE_VELOCITY_284:16384, DET_RANGE_VELOCITY_ERR_281:0, DET_RANGE_VELOCITY_ERR_282:0, DET_RANGE_VELOCITY_ERR_283:0, DET_RANGE_VELOCITY_ERR_284:0, DET_RCS_281:128, DET_RCS_282:128, DET_RCS_283:128, DET_RCS_284:128, DET_SNR_281:0, DET_SNR_282:0, DET_SNR_283:0, DET_SNR_284:0, DET_SUPER_RES_TARGET_281:0, DET_SUPER_RES_TARGET_282:0, DET_SUPER_RES_TARGET_283:0, DET_SUPER_RES_TARGET_284:0]}, provided-interface=Pi_SG_Detections_281_284_AL
      Pp_SG_Detections_285_288_AL: nonqueued-sender-com-spec{data-element=Vdp_SG_Detections_285_288_AL, init-value=fields=[DET_AZIMUTH_285:0, DET_AZIMUTH_286:0, DET_AZIMUTH_287:0, DET_AZIMUTH_288:0, DET_AZIMUTH_ERR_285:0, DET_AZIMUTH_ERR_286:0, DET_AZIMUTH_ERR_287:0, DET_AZIMUTH_ERR_288:0, DET_BELOW_RAIN_THOLD_285:0, DET_BELOW_RAIN_THOLD_286:0, DET_BELOW_RAIN_THOLD_287:0, DET_BELOW_RAIN_THOLD_288:0, DET_BI_STATIC_FLAG_285:0, DET_BI_STATIC_FLAG_286:0, DET_BI_STATIC_FLAG_287:0, DET_BI_STATIC_FLAG_288:0, DET_CONFD_AZIMUTH_285:0, DET_CONFD_AZIMUTH_286:0, DET_CONFD_AZIMUTH_287:0, DET_CONFD_AZIMUTH_288:0, DET_CONFD_ELEVATION_285:0, DET_CONFD_ELEVATION_286:0, DET_CONFD_ELEVATION_287:0, DET_CONFD_ELEVATION_288:0, DET_ELEVATION_285:0, DET_ELEVATION_286:0, DET_ELEVATION_287:0, DET_ELEVATION_288:0, DET_ELEVATION_ERR_285:0, DET_ELEVATION_ERR_286:0, DET_ELEVATION_ERR_287:0, DET_ELEVATION_ERR_288:0, DET_EXISTENCE_PROB_285:0, DET_EXISTENCE_PROB_286:0, DET_EXISTENCE_PROB_287:0, DET_EXISTENCE_PROB_288:0, DET_HVC_FLAG_285:0, DET_HVC_FLAG_286:0, DET_HVC_FLAG_287:0, DET_HVC_FLAG_288:0, DET_IDM_285:0, DET_IDM_286:0, DET_IDM_287:0, DET_IDM_288:0, DET_MH_CRC16_285_288:0, DET_MH_CYCLE_COUNTER_285_288:0, DET_MH_SCAN_INDEX_4LSB_285_288:0, DET_MTD_285:0, DET_MTD_286:0, DET_MTD_287:0, DET_MTD_288:0, DET_PROB_1STAZHYPO_285:0, DET_PROB_1STAZHYPO_286:0, DET_PROB_1STAZHYPO_287:0, DET_PROB_1STAZHYPO_288:0, DET_RANGE_285:0, DET_RANGE_286:0, DET_RANGE_287:0, DET_RANGE_288:0, DET_RANGE_ERR_285:0, DET_RANGE_ERR_286:0, DET_RANGE_ERR_287:0, DET_RANGE_ERR_288:0, DET_RANGE_VELOCITY_285:16384, DET_RANGE_VELOCITY_286:16384, DET_RANGE_VELOCITY_287:16384, DET_RANGE_VELOCITY_288:16384, DET_RANGE_VELOCITY_ERR_285:0, DET_RANGE_VELOCITY_ERR_286:0, DET_RANGE_VELOCITY_ERR_287:0, DET_RANGE_VELOCITY_ERR_288:0, DET_RCS_285:128, DET_RCS_286:128, DET_RCS_287:128, DET_RCS_288:128, DET_SNR_285:0, DET_SNR_286:0, DET_SNR_287:0, DET_SNR_288:0, DET_SUPER_RES_TARGET_285:0, DET_SUPER_RES_TARGET_286:0, DET_SUPER_RES_TARGET_287:0, DET_SUPER_RES_TARGET_288:0]}, provided-interface=Pi_SG_Detections_285_288_AL
      Pp_SG_Detections_289_292_AL: nonqueued-sender-com-spec{data-element=Vdp_SG_Detections_289_292_AL, init-value=fields=[DET_AZIMUTH_289:0, DET_AZIMUTH_290:0, DET_AZIMUTH_291:0, DET_AZIMUTH_292:0, DET_AZIMUTH_ERR_289:0, DET_AZIMUTH_ERR_290:0, DET_AZIMUTH_ERR_291:0, DET_AZIMUTH_ERR_292:0, DET_BELOW_RAIN_THOLD_289:0, DET_BELOW_RAIN_THOLD_290:0, DET_BELOW_RAIN_THOLD_291:0, DET_BELOW_RAIN_THOLD_292:0, DET_BI_STATIC_FLAG_289:0, DET_BI_STATIC_FLAG_290:0, DET_BI_STATIC_FLAG_291:0, DET_BI_STATIC_FLAG_292:0, DET_CONFD_AZIMUTH_289:0, DET_CONFD_AZIMUTH_290:0, DET_CONFD_AZIMUTH_291:0, DET_CONFD_AZIMUTH_292:0, DET_CONFD_ELEVATION_289:0, DET_CONFD_ELEVATION_290:0, DET_CONFD_ELEVATION_291:0, DET_CONFD_ELEVATION_292:0, DET_ELEVATION_289:0, DET_ELEVATION_290:0, DET_ELEVATION_291:0, DET_ELEVATION_292:0, DET_ELEVATION_ERR_289:0, DET_ELEVATION_ERR_290:0, DET_ELEVATION_ERR_291:0, DET_ELEVATION_ERR_292:0, DET_EXISTENCE_PROB_289:0, DET_EXISTENCE_PROB_290:0, DET_EXISTENCE_PROB_291:0, DET_EXISTENCE_PROB_292:0, DET_HVC_FLAG_289:0, DET_HVC_FLAG_290:0, DET_HVC_FLAG_291:0, DET_HVC_FLAG_292:0, DET_IDM_289:0, DET_IDM_290:0, DET_IDM_291:0, DET_IDM_292:0, DET_MH_CRC16_289_292:0, DET_MH_CYCLE_COUNTER_289_292:0, DET_MH_SCAN_INDEX_4LSB_289_292:0, DET_MTD_289:0, DET_MTD_290:0, DET_MTD_291:0, DET_MTD_292:0, DET_PROB_1STAZHYPO_289:0, DET_PROB_1STAZHYPO_290:0, DET_PROB_1STAZHYPO_291:0, DET_PROB_1STAZHYPO_292:0, DET_RANGE_289:0, DET_RANGE_290:0, DET_RANGE_291:0, DET_RANGE_292:0, DET_RANGE_ERR_289:0, DET_RANGE_ERR_290:0, DET_RANGE_ERR_291:0, DET_RANGE_ERR_292:0, DET_RANGE_VELOCITY_289:16384, DET_RANGE_VELOCITY_290:16384, DET_RANGE_VELOCITY_291:16384, DET_RANGE_VELOCITY_292:16384, DET_RANGE_VELOCITY_ERR_289:0, DET_RANGE_VELOCITY_ERR_290:0, DET_RANGE_VELOCITY_ERR_291:0, DET_RANGE_VELOCITY_ERR_292:0, DET_RCS_289:128, DET_RCS_290:128, DET_RCS_291:128, DET_RCS_292:128, DET_SNR_289:0, DET_SNR_290:0, DET_SNR_291:0, DET_SNR_292:0, DET_SUPER_RES_TARGET_289:0, DET_SUPER_RES_TARGET_290:0, DET_SUPER_RES_TARGET_291:0, DET_SUPER_RES_TARGET_292:0]}, provided-interface=Pi_SG_Detections_289_292_AL
      Pp_SG_Detections_293_296_AL: nonqueued-sender-com-spec{data-element=Vdp_SG_Detections_293_296_AL, init-value=fields=[DET_AZIMUTH_293:0, DET_AZIMUTH_294:0, DET_AZIMUTH_295:0, DET_AZIMUTH_296:0, DET_AZIMUTH_ERR_293:0, DET_AZIMUTH_ERR_294:0, DET_AZIMUTH_ERR_295:0, DET_AZIMUTH_ERR_296:0, DET_BELOW_RAIN_THOLD_293:0, DET_BELOW_RAIN_THOLD_294:0, DET_BELOW_RAIN_THOLD_295:0, DET_BELOW_RAIN_THOLD_296:0, DET_BI_STATIC_FLAG_293:0, DET_BI_STATIC_FLAG_294:0, DET_BI_STATIC_FLAG_295:0, DET_BI_STATIC_FLAG_296:0, DET_CONFD_AZIMUTH_293:0, DET_CONFD_AZIMUTH_294:0, DET_CONFD_AZIMUTH_295:0, DET_CONFD_AZIMUTH_296:0, DET_CONFD_ELEVATION_293:0, DET_CONFD_ELEVATION_294:0, DET_CONFD_ELEVATION_295:0, DET_CONFD_ELEVATION_296:0, DET_ELEVATION_293:0, DET_ELEVATION_294:0, DET_ELEVATION_295:0, DET_ELEVATION_296:0, DET_ELEVATION_ERR_293:0, DET_ELEVATION_ERR_294:0, DET_ELEVATION_ERR_295:0, DET_ELEVATION_ERR_296:0, DET_EXISTENCE_PROB_293:0, DET_EXISTENCE_PROB_294:0, DET_EXISTENCE_PROB_295:0, DET_EXISTENCE_PROB_296:0, DET_HVC_FLAG_293:0, DET_HVC_FLAG_294:0, DET_HVC_FLAG_295:0, DET_HVC_FLAG_296:0, DET_IDM_293:0, DET_IDM_294:0, DET_IDM_295:0, DET_IDM_296:0, DET_MH_CRC16_293_296:0, DET_MH_CYCLE_COUNTER_293_296:0, DET_MH_SCAN_INDEX_4LSB_293_296:0, DET_MTD_293:0, DET_MTD_294:0, DET_MTD_295:0, DET_MTD_296:0, DET_PROB_1STAZHYPO_293:0, DET_PROB_1STAZHYPO_294:0, DET_PROB_1STAZHYPO_295:0, DET_PROB_1STAZHYPO_296:0, DET_RANGE_293:0, DET_RANGE_294:0, DET_RANGE_295:0, DET_RANGE_296:0, DET_RANGE_ERR_293:0, DET_RANGE_ERR_294:0, DET_RANGE_ERR_295:0, DET_RANGE_ERR_296:0, DET_RANGE_VELOCITY_293:16384, DET_RANGE_VELOCITY_294:16384, DET_RANGE_VELOCITY_295:16384, DET_RANGE_VELOCITY_296:16384, DET_RANGE_VELOCITY_ERR_293:0, DET_RANGE_VELOCITY_ERR_294:0, DET_RANGE_VELOCITY_ERR_295:0, DET_RANGE_VELOCITY_ERR_296:0, DET_RCS_293:128, DET_RCS_294:128, DET_RCS_295:128, DET_RCS_296:128, DET_SNR_293:0, DET_SNR_294:0, DET_SNR_295:0, DET_SNR_296:0, DET_SUPER_RES_TARGET_293:0, DET_SUPER_RES_TARGET_294:0, DET_SUPER_RES_TARGET_295:0, DET_SUPER_RES_TARGET_296:0]}, provided-interface=Pi_SG_Detections_293_296_AL
      Pp_SG_Detections_297_300_AL: nonqueued-sender-com-spec{data-element=Vdp_SG_Detections_297_300_AL, init-value=fields=[DET_AZIMUTH_297:0, DET_AZIMUTH_298:0, DET_AZIMUTH_299:0, DET_AZIMUTH_300:0, DET_AZIMUTH_ERR_297:0, DET_AZIMUTH_ERR_298:0, DET_AZIMUTH_ERR_299:0, DET_AZIMUTH_ERR_300:0, DET_BELOW_RAIN_THOLD_297:0, DET_BELOW_RAIN_THOLD_298:0, DET_BELOW_RAIN_THOLD_299:0, DET_BELOW_RAIN_THOLD_300:0, DET_BI_STATIC_FLAG_297:0, DET_BI_STATIC_FLAG_298:0, DET_BI_STATIC_FLAG_299:0, DET_BI_STATIC_FLAG_300:0, DET_CONFD_AZIMUTH_297:0, DET_CONFD_AZIMUTH_298:0, DET_CONFD_AZIMUTH_299:0, DET_CONFD_AZIMUTH_300:0, DET_CONFD_ELEVATION_297:0, DET_CONFD_ELEVATION_298:0, DET_CONFD_ELEVATION_299:0, DET_CONFD_ELEVATION_300:0, DET_ELEVATION_297:0, DET_ELEVATION_298:0, DET_ELEVATION_299:0, DET_ELEVATION_300:0, DET_ELEVATION_ERR_297:0, DET_ELEVATION_ERR_298:0, DET_ELEVATION_ERR_299:0, DET_ELEVATION_ERR_300:0, DET_EXISTENCE_PROB_297:0, DET_EXISTENCE_PROB_298:0, DET_EXISTENCE_PROB_299:0, DET_EXISTENCE_PROB_300:0, DET_HVC_FLAG_297:0, DET_HVC_FLAG_298:0, DET_HVC_FLAG_299:0, DET_HVC_FLAG_300:0, DET_IDM_297:0, DET_IDM_298:0, DET_IDM_299:0, DET_IDM_300:0, DET_MH_CRC16_297_300:0, DET_MH_CYCLE_COUNTER_297_300:0, DET_MH_SCAN_INDEX_4LSB_297_300:0, DET_MTD_297:0, DET_MTD_298:0, DET_MTD_299:0, DET_MTD_300:0, DET_PROB_1STAZHYPO_297:0, DET_PROB_1STAZHYPO_298:0, DET_PROB_1STAZHYPO_299:0, DET_PROB_1STAZHYPO_300:0, DET_RANGE_297:0, DET_RANGE_298:0, DET_RANGE_299:0, DET_RANGE_300:0, DET_RANGE_ERR_297:0, DET_RANGE_ERR_298:0, DET_RANGE_ERR_299:0, DET_RANGE_ERR_300:0, DET_RANGE_VELOCITY_297:16384, DET_RANGE_VELOCITY_298:16384, DET_RANGE_VELOCITY_299:16384, DET_RANGE_VELOCITY_300:16384, DET_RANGE_VELOCITY_ERR_297:0, DET_RANGE_VELOCITY_ERR_298:0, DET_RANGE_VELOCITY_ERR_299:0, DET_RANGE_VELOCITY_ERR_300:0, DET_RCS_297:128, DET_RCS_298:128, DET_RCS_299:128, DET_RCS_300:128, DET_SNR_297:0, DET_SNR_298:0, DET_SNR_299:0, DET_SNR_300:0, DET_SUPER_RES_TARGET_297:0, DET_SUPER_RES_TARGET_298:0, DET_SUPER_RES_TARGET_299:0, DET_SUPER_RES_TARGET_300:0]}, provided-interface=Pi_SG_Detections_297_300_AL
      Pp_SG_Detections_301_304_AL: nonqueued-sender-com-spec{data-element=Vdp_SG_Detections_301_304_AL, init-value=fields=[DET_AZIMUTH_301:0, DET_AZIMUTH_302:0, DET_AZIMUTH_303:0, DET_AZIMUTH_304:0, DET_AZIMUTH_ERR_301:0, DET_AZIMUTH_ERR_302:0, DET_AZIMUTH_ERR_303:0, DET_AZIMUTH_ERR_304:0, DET_BELOW_RAIN_THOLD_301:0, DET_BELOW_RAIN_THOLD_302:0, DET_BELOW_RAIN_THOLD_303:0, DET_BELOW_RAIN_THOLD_304:0, DET_BI_STATIC_FLAG_301:0, DET_BI_STATIC_FLAG_302:0, DET_BI_STATIC_FLAG_303:0, DET_BI_STATIC_FLAG_304:0, DET_CONFD_AZIMUTH_301:0, DET_CONFD_AZIMUTH_302:0, DET_CONFD_AZIMUTH_303:0, DET_CONFD_AZIMUTH_304:0, DET_CONFD_ELEVATION_301:0, DET_CONFD_ELEVATION_302:0, DET_CONFD_ELEVATION_303:0, DET_CONFD_ELEVATION_304:0, DET_ELEVATION_301:0, DET_ELEVATION_302:0, DET_ELEVATION_303:0, DET_ELEVATION_304:0, DET_ELEVATION_ERR_301:0, DET_ELEVATION_ERR_302:0, DET_ELEVATION_ERR_303:0, DET_ELEVATION_ERR_304:0, DET_EXISTENCE_PROB_301:0, DET_EXISTENCE_PROB_302:0, DET_EXISTENCE_PROB_303:0, DET_EXISTENCE_PROB_304:0, DET_HVC_FLAG_301:0, DET_HVC_FLAG_302:0, DET_HVC_FLAG_303:0, DET_HVC_FLAG_304:0, DET_IDM_301:0, DET_IDM_302:0, DET_IDM_303:0, DET_IDM_304:0, DET_MH_CRC16_301_304:0, DET_MH_CYCLE_COUNTER_301_304:0, DET_MH_SCAN_INDEX_4LSB_301_304:0, DET_MTD_301:0, DET_MTD_302:0, DET_MTD_303:0, DET_MTD_304:0, DET_PROB_1STAZHYPO_301:0, DET_PROB_1STAZHYPO_302:0, DET_PROB_1STAZHYPO_303:0, DET_PROB_1STAZHYPO_304:0, DET_RANGE_301:0, DET_RANGE_302:0, DET_RANGE_303:0, DET_RANGE_304:0, DET_RANGE_ERR_301:0, DET_RANGE_ERR_302:0, DET_RANGE_ERR_303:0, DET_RANGE_ERR_304:0, DET_RANGE_VELOCITY_301:16384, DET_RANGE_VELOCITY_302:16384, DET_RANGE_VELOCITY_303:16384, DET_RANGE_VELOCITY_304:16384, DET_RANGE_VELOCITY_ERR_301:0, DET_RANGE_VELOCITY_ERR_302:0, DET_RANGE_VELOCITY_ERR_303:0, DET_RANGE_VELOCITY_ERR_304:0, DET_RCS_301:128, DET_RCS_302:128, DET_RCS_303:128, DET_RCS_304:128, DET_SNR_301:0, DET_SNR_302:0, DET_SNR_303:0, DET_SNR_304:0, DET_SUPER_RES_TARGET_301:0, DET_SUPER_RES_TARGET_302:0, DET_SUPER_RES_TARGET_303:0, DET_SUPER_RES_TARGET_304:0]}, provided-interface=Pi_SG_Detections_301_304_AL
      Pp_SG_Detections_305_308_AL: nonqueued-sender-com-spec{data-element=Vdp_SG_Detections_305_308_AL, init-value=fields=[DET_AZIMUTH_305:0, DET_AZIMUTH_306:0, DET_AZIMUTH_307:0, DET_AZIMUTH_308:0, DET_AZIMUTH_ERR_305:0, DET_AZIMUTH_ERR_306:0, DET_AZIMUTH_ERR_307:0, DET_AZIMUTH_ERR_308:0, DET_BELOW_RAIN_THOLD_305:0, DET_BELOW_RAIN_THOLD_306:0, DET_BELOW_RAIN_THOLD_307:0, DET_BELOW_RAIN_THOLD_308:0, DET_BI_STATIC_FLAG_305:0, DET_BI_STATIC_FLAG_306:0, DET_BI_STATIC_FLAG_307:0, DET_BI_STATIC_FLAG_308:0, DET_CONFD_AZIMUTH_305:0, DET_CONFD_AZIMUTH_306:0, DET_CONFD_AZIMUTH_307:0, DET_CONFD_AZIMUTH_308:0, DET_CONFD_ELEVATION_305:0, DET_CONFD_ELEVATION_306:0, DET_CONFD_ELEVATION_307:0, DET_CONFD_ELEVATION_308:0, DET_ELEVATION_305:0, DET_ELEVATION_306:0, DET_ELEVATION_307:0, DET_ELEVATION_308:0, DET_ELEVATION_ERR_305:0, DET_ELEVATION_ERR_306:0, DET_ELEVATION_ERR_307:0, DET_ELEVATION_ERR_308:0, DET_EXISTENCE_PROB_305:0, DET_EXISTENCE_PROB_306:0, DET_EXISTENCE_PROB_307:0, DET_EXISTENCE_PROB_308:0, DET_HVC_FLAG_305:0, DET_HVC_FLAG_306:0, DET_HVC_FLAG_307:0, DET_HVC_FLAG_308:0, DET_IDM_305:0, DET_IDM_306:0, DET_IDM_307:0, DET_IDM_308:0, DET_MH_CRC16_305_308:0, DET_MH_CYCLE_COUNTER_305_308:0, DET_MH_SCAN_INDEX_4LSB_305_308:0, DET_MTD_305:0, DET_MTD_306:0, DET_MTD_307:0, DET_MTD_308:0, DET_PROB_1STAZHYPO_305:0, DET_PROB_1STAZHYPO_306:0, DET_PROB_1STAZHYPO_307:0, DET_PROB_1STAZHYPO_308:0, DET_RANGE_305:0, DET_RANGE_306:0, DET_RANGE_307:0, DET_RANGE_308:0, DET_RANGE_ERR_305:0, DET_RANGE_ERR_306:0, DET_RANGE_ERR_307:0, DET_RANGE_ERR_308:0, DET_RANGE_VELOCITY_305:16384, DET_RANGE_VELOCITY_306:16384, DET_RANGE_VELOCITY_307:16384, DET_RANGE_VELOCITY_308:16384, DET_RANGE_VELOCITY_ERR_305:0, DET_RANGE_VELOCITY_ERR_306:0, DET_RANGE_VELOCITY_ERR_307:0, DET_RANGE_VELOCITY_ERR_308:0, DET_RCS_305:128, DET_RCS_306:128, DET_RCS_307:128, DET_RCS_308:128, DET_SNR_305:0, DET_SNR_306:0, DET_SNR_307:0, DET_SNR_308:0, DET_SUPER_RES_TARGET_305:0, DET_SUPER_RES_TARGET_306:0, DET_SUPER_RES_TARGET_307:0, DET_SUPER_RES_TARGET_308:0]}, provided-interface=Pi_SG_Detections_305_308_AL
      Pp_SG_Detections_309_312_AL: nonqueued-sender-com-spec{data-element=Vdp_SG_Detections_309_312_AL, init-value=fields=[DET_AZIMUTH_309:0, DET_AZIMUTH_310:0, DET_AZIMUTH_311:0, DET_AZIMUTH_312:0, DET_AZIMUTH_ERR_309:0, DET_AZIMUTH_ERR_310:0, DET_AZIMUTH_ERR_311:0, DET_AZIMUTH_ERR_312:0, DET_BELOW_RAIN_THOLD_309:0, DET_BELOW_RAIN_THOLD_310:0, DET_BELOW_RAIN_THOLD_311:0, DET_BELOW_RAIN_THOLD_312:0, DET_BI_STATIC_FLAG_309:0, DET_BI_STATIC_FLAG_310:0, DET_BI_STATIC_FLAG_311:0, DET_BI_STATIC_FLAG_312:0, DET_CONFD_AZIMUTH_309:0, DET_CONFD_AZIMUTH_310:0, DET_CONFD_AZIMUTH_311:0, DET_CONFD_AZIMUTH_312:0, DET_CONFD_ELEVATION_309:0, DET_CONFD_ELEVATION_310:0, DET_CONFD_ELEVATION_311:0, DET_CONFD_ELEVATION_312:0, DET_ELEVATION_309:0, DET_ELEVATION_310:0, DET_ELEVATION_311:0, DET_ELEVATION_312:0, DET_ELEVATION_ERR_309:0, DET_ELEVATION_ERR_310:0, DET_ELEVATION_ERR_311:0, DET_ELEVATION_ERR_312:0, DET_EXISTENCE_PROB_309:0, DET_EXISTENCE_PROB_310:0, DET_EXISTENCE_PROB_311:0, DET_EXISTENCE_PROB_312:0, DET_HVC_FLAG_309:0, DET_HVC_FLAG_310:0, DET_HVC_FLAG_311:0, DET_HVC_FLAG_312:0, DET_IDM_309:0, DET_IDM_310:0, DET_IDM_311:0, DET_IDM_312:0, DET_MH_CRC16_309_312:0, DET_MH_CYCLE_COUNTER_309_312:0, DET_MH_SCAN_INDEX_4LSB_309_312:0, DET_MTD_309:0, DET_MTD_310:0, DET_MTD_311:0, DET_MTD_312:0, DET_PROB_1STAZHYPO_309:0, DET_PROB_1STAZHYPO_310:0, DET_PROB_1STAZHYPO_311:0, DET_PROB_1STAZHYPO_312:0, DET_RANGE_309:0, DET_RANGE_310:0, DET_RANGE_311:0, DET_RANGE_312:0, DET_RANGE_ERR_309:0, DET_RANGE_ERR_310:0, DET_RANGE_ERR_311:0, DET_RANGE_ERR_312:0, DET_RANGE_VELOCITY_309:16384, DET_RANGE_VELOCITY_310:16384, DET_RANGE_VELOCITY_311:16384, DET_RANGE_VELOCITY_312:16384, DET_RANGE_VELOCITY_ERR_309:0, DET_RANGE_VELOCITY_ERR_310:0, DET_RANGE_VELOCITY_ERR_311:0, DET_RANGE_VELOCITY_ERR_312:0, DET_RCS_309:128, DET_RCS_310:128, DET_RCS_311:128, DET_RCS_312:128, DET_SNR_309:0, DET_SNR_310:0, DET_SNR_311:0, DET_SNR_312:0, DET_SUPER_RES_TARGET_309:0, DET_SUPER_RES_TARGET_310:0, DET_SUPER_RES_TARGET_311:0, DET_SUPER_RES_TARGET_312:0]}, provided-interface=Pi_SG_Detections_309_312_AL
      Pp_SG_Detections_313_316_AL: nonqueued-sender-com-spec{data-element=Vdp_SG_Detections_313_316_AL, init-value=fields=[DET_AZIMUTH_313:0, DET_AZIMUTH_314:0, DET_AZIMUTH_315:0, DET_AZIMUTH_316:0, DET_AZIMUTH_ERR_313:0, DET_AZIMUTH_ERR_314:0, DET_AZIMUTH_ERR_315:0, DET_AZIMUTH_ERR_316:0, DET_BELOW_RAIN_THOLD_313:0, DET_BELOW_RAIN_THOLD_314:0, DET_BELOW_RAIN_THOLD_315:0, DET_BELOW_RAIN_THOLD_316:0, DET_BI_STATIC_FLAG_313:0, DET_BI_STATIC_FLAG_314:0, DET_BI_STATIC_FLAG_315:0, DET_BI_STATIC_FLAG_316:0, DET_CONFD_AZIMUTH_313:0, DET_CONFD_AZIMUTH_314:0, DET_CONFD_AZIMUTH_315:0, DET_CONFD_AZIMUTH_316:0, DET_CONFD_ELEVATION_313:0, DET_CONFD_ELEVATION_314:0, DET_CONFD_ELEVATION_315:0, DET_CONFD_ELEVATION_316:0, DET_ELEVATION_313:0, DET_ELEVATION_314:0, DET_ELEVATION_315:0, DET_ELEVATION_316:0, DET_ELEVATION_ERR_313:0, DET_ELEVATION_ERR_314:0, DET_ELEVATION_ERR_315:0, DET_ELEVATION_ERR_316:0, DET_EXISTENCE_PROB_313:0, DET_EXISTENCE_PROB_314:0, DET_EXISTENCE_PROB_315:0, DET_EXISTENCE_PROB_316:0, DET_HVC_FLAG_313:0, DET_HVC_FLAG_314:0, DET_HVC_FLAG_315:0, DET_HVC_FLAG_316:0, DET_IDM_313:0, DET_IDM_314:0, DET_IDM_315:0, DET_IDM_316:0, DET_MH_CRC16_313_316:0, DET_MH_CYCLE_COUNTER_313_316:0, DET_MH_SCAN_INDEX_4LSB_313_316:0, DET_MTD_313:0, DET_MTD_314:0, DET_MTD_315:0, DET_MTD_316:0, DET_PROB_1STAZHYPO_313:0, DET_PROB_1STAZHYPO_314:0, DET_PROB_1STAZHYPO_315:0, DET_PROB_1STAZHYPO_316:0, DET_RANGE_313:0, DET_RANGE_314:0, DET_RANGE_315:0, DET_RANGE_316:0, DET_RANGE_ERR_313:0, DET_RANGE_ERR_314:0, DET_RANGE_ERR_315:0, DET_RANGE_ERR_316:0, DET_RANGE_VELOCITY_313:16384, DET_RANGE_VELOCITY_314:16384, DET_RANGE_VELOCITY_315:16384, DET_RANGE_VELOCITY_316:16384, DET_RANGE_VELOCITY_ERR_313:0, DET_RANGE_VELOCITY_ERR_314:0, DET_RANGE_VELOCITY_ERR_315:0, DET_RANGE_VELOCITY_ERR_316:0, DET_RCS_313:128, DET_RCS_314:128, DET_RCS_315:128, DET_RCS_316:128, DET_SNR_313:0, DET_SNR_314:0, DET_SNR_315:0, DET_SNR_316:0, DET_SUPER_RES_TARGET_313:0, DET_SUPER_RES_TARGET_314:0, DET_SUPER_RES_TARGET_315:0, DET_SUPER_RES_TARGET_316:0]}, provided-interface=Pi_SG_Detections_313_316_AL
      Pp_SG_Detections_317_320_AL: nonqueued-sender-com-spec{data-element=Vdp_SG_Detections_317_320_AL, init-value=fields=[DET_AZIMUTH_317:0, DET_AZIMUTH_318:0, DET_AZIMUTH_319:0, DET_AZIMUTH_320:0, DET_AZIMUTH_ERR_317:0, DET_AZIMUTH_ERR_318:0, DET_AZIMUTH_ERR_319:0, DET_AZIMUTH_ERR_320:0, DET_BELOW_RAIN_THOLD_317:0, DET_BELOW_RAIN_THOLD_318:0, DET_BELOW_RAIN_THOLD_319:0, DET_BELOW_RAIN_THOLD_320:0, DET_BI_STATIC_FLAG_317:0, DET_BI_STATIC_FLAG_318:0, DET_BI_STATIC_FLAG_319:0, DET_BI_STATIC_FLAG_320:0, DET_CONFD_AZIMUTH_317:0, DET_CONFD_AZIMUTH_318:0, DET_CONFD_AZIMUTH_319:0, DET_CONFD_AZIMUTH_320:0, DET_CONFD_ELEVATION_317:0, DET_CONFD_ELEVATION_318:0, DET_CONFD_ELEVATION_319:0, DET_CONFD_ELEVATION_320:0, DET_ELEVATION_317:0, DET_ELEVATION_318:0, DET_ELEVATION_319:0, DET_ELEVATION_320:0, DET_ELEVATION_ERR_317:0, DET_ELEVATION_ERR_318:0, DET_ELEVATION_ERR_319:0, DET_ELEVATION_ERR_320:0, DET_EXISTENCE_PROB_317:0, DET_EXISTENCE_PROB_318:0, DET_EXISTENCE_PROB_319:0, DET_EXISTENCE_PROB_320:0, DET_HVC_FLAG_317:0, DET_HVC_FLAG_318:0, DET_HVC_FLAG_319:0, DET_HVC_FLAG_320:0, DET_IDM_317:0, DET_IDM_318:0, DET_IDM_319:0, DET_IDM_320:0, DET_MH_CRC16_317_320:0, DET_MH_CYCLE_COUNTER_317_320:0, DET_MH_SCAN_INDEX_4LSB_317_320:0, DET_MTD_317:0, DET_MTD_318:0, DET_MTD_319:0, DET_MTD_320:0, DET_PROB_1STAZHYPO_317:0, DET_PROB_1STAZHYPO_318:0, DET_PROB_1STAZHYPO_319:0, DET_PROB_1STAZHYPO_320:0, DET_RANGE_317:0, DET_RANGE_318:0, DET_RANGE_319:0, DET_RANGE_320:0, DET_RANGE_ERR_317:0, DET_RANGE_ERR_318:0, DET_RANGE_ERR_319:0, DET_RANGE_ERR_320:0, DET_RANGE_VELOCITY_317:16384, DET_RANGE_VELOCITY_318:16384, DET_RANGE_VELOCITY_319:16384, DET_RANGE_VELOCITY_320:16384, DET_RANGE_VELOCITY_ERR_317:0, DET_RANGE_VELOCITY_ERR_318:0, DET_RANGE_VELOCITY_ERR_319:0, DET_RANGE_VELOCITY_ERR_320:0, DET_RCS_317:128, DET_RCS_318:128, DET_RCS_319:128, DET_RCS_320:128, DET_SNR_317:0, DET_SNR_318:0, DET_SNR_319:0, DET_SNR_320:0, DET_SUPER_RES_TARGET_317:0, DET_SUPER_RES_TARGET_318:0, DET_SUPER_RES_TARGET_319:0, DET_SUPER_RES_TARGET_320:0]}, provided-interface=Pi_SG_Detections_317_320_AL
      Pp_SG_Detections_321_324_AL: nonqueued-sender-com-spec{data-element=Vdp_SG_Detections_321_324_AL, init-value=fields=[DET_AZIMUTH_321:0, DET_AZIMUTH_322:0, DET_AZIMUTH_323:0, DET_AZIMUTH_324:0, DET_AZIMUTH_ERR_321:0, DET_AZIMUTH_ERR_322:0, DET_AZIMUTH_ERR_323:0, DET_AZIMUTH_ERR_324:0, DET_BELOW_RAIN_THOLD_321:0, DET_BELOW_RAIN_THOLD_322:0, DET_BELOW_RAIN_THOLD_323:0, DET_BELOW_RAIN_THOLD_324:0, DET_BI_STATIC_FLAG_321:0, DET_BI_STATIC_FLAG_322:0, DET_BI_STATIC_FLAG_323:0, DET_BI_STATIC_FLAG_324:0, DET_CONFD_AZIMUTH_321:0, DET_CONFD_AZIMUTH_322:0, DET_CONFD_AZIMUTH_323:0, DET_CONFD_AZIMUTH_324:0, DET_CONFD_ELEVATION_321:0, DET_CONFD_ELEVATION_322:0, DET_CONFD_ELEVATION_323:0, DET_CONFD_ELEVATION_324:0, DET_ELEVATION_321:0, DET_ELEVATION_322:0, DET_ELEVATION_323:0, DET_ELEVATION_324:0, DET_ELEVATION_ERR_321:0, DET_ELEVATION_ERR_322:0, DET_ELEVATION_ERR_323:0, DET_ELEVATION_ERR_324:0, DET_EXISTENCE_PROB_321:0, DET_EXISTENCE_PROB_322:0, DET_EXISTENCE_PROB_323:0, DET_EXISTENCE_PROB_324:0, DET_HVC_FLAG_321:0, DET_HVC_FLAG_322:0, DET_HVC_FLAG_323:0, DET_HVC_FLAG_324:0, DET_IDM_321:0, DET_IDM_322:0, DET_IDM_323:0, DET_IDM_324:0, DET_MH_CRC16_321_324:0, DET_MH_CYCLE_COUNTER_321_324:0, DET_MH_SCAN_INDEX_4LSB_321_324:0, DET_MTD_321:0, DET_MTD_322:0, DET_MTD_323:0, DET_MTD_324:0, DET_PROB_1STAZHYPO_321:0, DET_PROB_1STAZHYPO_322:0, DET_PROB_1STAZHYPO_323:0, DET_PROB_1STAZHYPO_324:0, DET_RANGE_321:0, DET_RANGE_322:0, DET_RANGE_323:0, DET_RANGE_324:0, DET_RANGE_ERR_321:0, DET_RANGE_ERR_322:0, DET_RANGE_ERR_323:0, DET_RANGE_ERR_324:0, DET_RANGE_VELOCITY_321:16384, DET_RANGE_VELOCITY_322:16384, DET_RANGE_VELOCITY_323:16384, DET_RANGE_VELOCITY_324:16384, DET_RANGE_VELOCITY_ERR_321:0, DET_RANGE_VELOCITY_ERR_322:0, DET_RANGE_VELOCITY_ERR_323:0, DET_RANGE_VELOCITY_ERR_324:0, DET_RCS_321:128, DET_RCS_322:128, DET_RCS_323:128, DET_RCS_324:128, DET_SNR_321:0, DET_SNR_322:0, DET_SNR_323:0, DET_SNR_324:0, DET_SUPER_RES_TARGET_321:0, DET_SUPER_RES_TARGET_322:0, DET_SUPER_RES_TARGET_323:0, DET_SUPER_RES_TARGET_324:0]}, provided-interface=Pi_SG_Detections_321_324_AL
      Pp_SG_Detections_325_328_AL: nonqueued-sender-com-spec{data-element=Vdp_SG_Detections_325_328_AL, init-value=fields=[DET_AZIMUTH_325:0, DET_AZIMUTH_326:0, DET_AZIMUTH_327:0, DET_AZIMUTH_328:0, DET_AZIMUTH_ERR_325:0, DET_AZIMUTH_ERR_326:0, DET_AZIMUTH_ERR_327:0, DET_AZIMUTH_ERR_328:0, DET_BELOW_RAIN_THOLD_325:0, DET_BELOW_RAIN_THOLD_326:0, DET_BELOW_RAIN_THOLD_327:0, DET_BELOW_RAIN_THOLD_328:0, DET_BI_STATIC_FLAG_325:0, DET_BI_STATIC_FLAG_326:0, DET_BI_STATIC_FLAG_327:0, DET_BI_STATIC_FLAG_328:0, DET_CONFD_AZIMUTH_325:0, DET_CONFD_AZIMUTH_326:0, DET_CONFD_AZIMUTH_327:0, DET_CONFD_AZIMUTH_328:0, DET_CONFD_ELEVATION_325:0, DET_CONFD_ELEVATION_326:0, DET_CONFD_ELEVATION_327:0, DET_CONFD_ELEVATION_328:0, DET_ELEVATION_325:0, DET_ELEVATION_326:0, DET_ELEVATION_327:0, DET_ELEVATION_328:0, DET_ELEVATION_ERR_325:0, DET_ELEVATION_ERR_326:0, DET_ELEVATION_ERR_327:0, DET_ELEVATION_ERR_328:0, DET_EXISTENCE_PROB_325:0, DET_EXISTENCE_PROB_326:0, DET_EXISTENCE_PROB_327:0, DET_EXISTENCE_PROB_328:0, DET_HVC_FLAG_325:0, DET_HVC_FLAG_326:0, DET_HVC_FLAG_327:0, DET_HVC_FLAG_328:0, DET_IDM_325:0, DET_IDM_326:0, DET_IDM_327:0, DET_IDM_328:0, DET_MH_CRC16_325_328:0, DET_MH_CYCLE_COUNTER_325_328:0, DET_MH_SCAN_INDEX_4LSB_325_328:0, DET_MTD_325:0, DET_MTD_326:0, DET_MTD_327:0, DET_MTD_328:0, DET_PROB_1STAZHYPO_325:0, DET_PROB_1STAZHYPO_326:0, DET_PROB_1STAZHYPO_327:0, DET_PROB_1STAZHYPO_328:0, DET_RANGE_325:0, DET_RANGE_326:0, DET_RANGE_327:0, DET_RANGE_328:0, DET_RANGE_ERR_325:0, DET_RANGE_ERR_326:0, DET_RANGE_ERR_327:0, DET_RANGE_ERR_328:0, DET_RANGE_VELOCITY_325:16384, DET_RANGE_VELOCITY_326:16384, DET_RANGE_VELOCITY_327:16384, DET_RANGE_VELOCITY_328:16384, DET_RANGE_VELOCITY_ERR_325:0, DET_RANGE_VELOCITY_ERR_326:0, DET_RANGE_VELOCITY_ERR_327:0, DET_RANGE_VELOCITY_ERR_328:0, DET_RCS_325:128, DET_RCS_326:128, DET_RCS_327:128, DET_RCS_328:128, DET_SNR_325:0, DET_SNR_326:0, DET_SNR_327:0, DET_SNR_328:0, DET_SUPER_RES_TARGET_325:0, DET_SUPER_RES_TARGET_326:0, DET_SUPER_RES_TARGET_327:0, DET_SUPER_RES_TARGET_328:0]}, provided-interface=Pi_SG_Detections_325_328_AL
      Pp_SG_Detections_329_332_AL: nonqueued-sender-com-spec{data-element=Vdp_SG_Detections_329_332_AL, init-value=fields=[DET_AZIMUTH_329:0, DET_AZIMUTH_330:0, DET_AZIMUTH_331:0, DET_AZIMUTH_332:0, DET_AZIMUTH_ERR_329:0, DET_AZIMUTH_ERR_330:0, DET_AZIMUTH_ERR_331:0, DET_AZIMUTH_ERR_332:0, DET_BELOW_RAIN_THOLD_329:0, DET_BELOW_RAIN_THOLD_330:0, DET_BELOW_RAIN_THOLD_331:0, DET_BELOW_RAIN_THOLD_332:0, DET_BI_STATIC_FLAG_329:0, DET_BI_STATIC_FLAG_330:0, DET_BI_STATIC_FLAG_331:0, DET_BI_STATIC_FLAG_332:0, DET_CONFD_AZIMUTH_329:0, DET_CONFD_AZIMUTH_330:0, DET_CONFD_AZIMUTH_331:0, DET_CONFD_AZIMUTH_332:0, DET_CONFD_ELEVATION_329:0, DET_CONFD_ELEVATION_330:0, DET_CONFD_ELEVATION_331:0, DET_CONFD_ELEVATION_332:0, DET_ELEVATION_329:0, DET_ELEVATION_330:0, DET_ELEVATION_331:0, DET_ELEVATION_332:0, DET_ELEVATION_ERR_329:0, DET_ELEVATION_ERR_330:0, DET_ELEVATION_ERR_331:0, DET_ELEVATION_ERR_332:0, DET_EXISTENCE_PROB_329:0, DET_EXISTENCE_PROB_330:0, DET_EXISTENCE_PROB_331:0, DET_EXISTENCE_PROB_332:0, DET_HVC_FLAG_329:0, DET_HVC_FLAG_330:0, DET_HVC_FLAG_331:0, DET_HVC_FLAG_332:0, DET_IDM_329:0, DET_IDM_330:0, DET_IDM_331:0, DET_IDM_332:0, DET_MH_CRC16_329_332:0, DET_MH_CYCLE_COUNTER_329_332:0, DET_MH_SCAN_INDEX_4LSB_329_332:0, DET_MTD_329:0, DET_MTD_330:0, DET_MTD_331:0, DET_MTD_332:0, DET_PROB_1STAZHYPO_329:0, DET_PROB_1STAZHYPO_330:0, DET_PROB_1STAZHYPO_331:0, DET_PROB_1STAZHYPO_332:0, DET_RANGE_329:0, DET_RANGE_330:0, DET_RANGE_331:0, DET_RANGE_332:0, DET_RANGE_ERR_329:0, DET_RANGE_ERR_330:0, DET_RANGE_ERR_331:0, DET_RANGE_ERR_332:0, DET_RANGE_VELOCITY_329:16384, DET_RANGE_VELOCITY_330:16384, DET_RANGE_VELOCITY_331:16384, DET_RANGE_VELOCITY_332:16384, DET_RANGE_VELOCITY_ERR_329:0, DET_RANGE_VELOCITY_ERR_330:0, DET_RANGE_VELOCITY_ERR_331:0, DET_RANGE_VELOCITY_ERR_332:0, DET_RCS_329:128, DET_RCS_330:128, DET_RCS_331:128, DET_RCS_332:128, DET_SNR_329:0, DET_SNR_330:0, DET_SNR_331:0, DET_SNR_332:0, DET_SUPER_RES_TARGET_329:0, DET_SUPER_RES_TARGET_330:0, DET_SUPER_RES_TARGET_331:0, DET_SUPER_RES_TARGET_332:0]}, provided-interface=Pi_SG_Detections_329_332_AL
      Pp_SG_Detections_333_336_AL: nonqueued-sender-com-spec{data-element=Vdp_SG_Detections_333_336_AL, init-value=fields=[DET_AZIMUTH_333:0, DET_AZIMUTH_334:0, DET_AZIMUTH_335:0, DET_AZIMUTH_336:0, DET_AZIMUTH_ERR_333:0, DET_AZIMUTH_ERR_334:0, DET_AZIMUTH_ERR_335:0, DET_AZIMUTH_ERR_336:0, DET_BELOW_RAIN_THOLD_333:0, DET_BELOW_RAIN_THOLD_334:0, DET_BELOW_RAIN_THOLD_335:0, DET_BELOW_RAIN_THOLD_336:0, DET_BI_STATIC_FLAG_333:0, DET_BI_STATIC_FLAG_334:0, DET_BI_STATIC_FLAG_335:0, DET_BI_STATIC_FLAG_336:0, DET_CONFD_AZIMUTH_333:0, DET_CONFD_AZIMUTH_334:0, DET_CONFD_AZIMUTH_335:0, DET_CONFD_AZIMUTH_336:0, DET_CONFD_ELEVATION_333:0, DET_CONFD_ELEVATION_334:0, DET_CONFD_ELEVATION_335:0, DET_CONFD_ELEVATION_336:0, DET_ELEVATION_333:0, DET_ELEVATION_334:0, DET_ELEVATION_335:0, DET_ELEVATION_336:0, DET_ELEVATION_ERR_333:0, DET_ELEVATION_ERR_334:0, DET_ELEVATION_ERR_335:0, DET_ELEVATION_ERR_336:0, DET_EXISTENCE_PROB_333:0, DET_EXISTENCE_PROB_334:0, DET_EXISTENCE_PROB_335:0, DET_EXISTENCE_PROB_336:0, DET_HVC_FLAG_333:0, DET_HVC_FLAG_334:0, DET_HVC_FLAG_335:0, DET_HVC_FLAG_336:0, DET_IDM_333:0, DET_IDM_334:0, DET_IDM_335:0, DET_IDM_336:0, DET_MH_CRC16_333_336:0, DET_MH_CYCLE_COUNTER_333_336:0, DET_MH_SCAN_INDEX_4LSB_333_336:0, DET_MTD_333:0, DET_MTD_334:0, DET_MTD_335:0, DET_MTD_336:0, DET_PROB_1STAZHYPO_333:0, DET_PROB_1STAZHYPO_334:0, DET_PROB_1STAZHYPO_335:0, DET_PROB_1STAZHYPO_336:0, DET_RANGE_333:0, DET_RANGE_334:0, DET_RANGE_335:0, DET_RANGE_336:0, DET_RANGE_ERR_333:0, DET_RANGE_ERR_334:0, DET_RANGE_ERR_335:0, DET_RANGE_ERR_336:0, DET_RANGE_VELOCITY_333:16384, DET_RANGE_VELOCITY_334:16384, DET_RANGE_VELOCITY_335:16384, DET_RANGE_VELOCITY_336:16384, DET_RANGE_VELOCITY_ERR_333:0, DET_RANGE_VELOCITY_ERR_334:0, DET_RANGE_VELOCITY_ERR_335:0, DET_RANGE_VELOCITY_ERR_336:0, DET_RCS_333:128, DET_RCS_334:128, DET_RCS_335:128, DET_RCS_336:128, DET_SNR_333:0, DET_SNR_334:0, DET_SNR_335:0, DET_SNR_336:0, DET_SUPER_RES_TARGET_333:0, DET_SUPER_RES_TARGET_334:0, DET_SUPER_RES_TARGET_335:0, DET_SUPER_RES_TARGET_336:0]}, provided-interface=Pi_SG_Detections_333_336_AL
      Pp_SG_Detections_337_340_AL: nonqueued-sender-com-spec{data-element=Vdp_SG_Detections_337_340_AL, init-value=fields=[DET_AZIMUTH_337:0, DET_AZIMUTH_338:0, DET_AZIMUTH_339:0, DET_AZIMUTH_340:0, DET_AZIMUTH_ERR_337:0, DET_AZIMUTH_ERR_338:0, DET_AZIMUTH_ERR_339:0, DET_AZIMUTH_ERR_340:0, DET_BELOW_RAIN_THOLD_337:0, DET_BELOW_RAIN_THOLD_338:0, DET_BELOW_RAIN_THOLD_339:0, DET_BELOW_RAIN_THOLD_340:0, DET_BI_STATIC_FLAG_337:0, DET_BI_STATIC_FLAG_338:0, DET_BI_STATIC_FLAG_339:0, DET_BI_STATIC_FLAG_340:0, DET_CONFD_AZIMUTH_337:0, DET_CONFD_AZIMUTH_338:0, DET_CONFD_AZIMUTH_339:0, DET_CONFD_AZIMUTH_340:0, DET_CONFD_ELEVATION_337:0, DET_CONFD_ELEVATION_338:0, DET_CONFD_ELEVATION_339:0, DET_CONFD_ELEVATION_340:0, DET_ELEVATION_337:0, DET_ELEVATION_338:0, DET_ELEVATION_339:0, DET_ELEVATION_340:0, DET_ELEVATION_ERR_337:0, DET_ELEVATION_ERR_338:0, DET_ELEVATION_ERR_339:0, DET_ELEVATION_ERR_340:0, DET_EXISTENCE_PROB_337:0, DET_EXISTENCE_PROB_338:0, DET_EXISTENCE_PROB_339:0, DET_EXISTENCE_PROB_340:0, DET_HVC_FLAG_337:0, DET_HVC_FLAG_338:0, DET_HVC_FLAG_339:0, DET_HVC_FLAG_340:0, DET_IDM_337:0, DET_IDM_338:0, DET_IDM_339:0, DET_IDM_340:0, DET_MH_CRC16_337_340:0, DET_MH_CYCLE_COUNTER_337_340:0, DET_MH_SCAN_INDEX_4LSB_337_340:0, DET_MTD_337:0, DET_MTD_338:0, DET_MTD_339:0, DET_MTD_340:0, DET_PROB_1STAZHYPO_337:0, DET_PROB_1STAZHYPO_338:0, DET_PROB_1STAZHYPO_339:0, DET_PROB_1STAZHYPO_340:0, DET_RANGE_337:0, DET_RANGE_338:0, DET_RANGE_339:0, DET_RANGE_340:0, DET_RANGE_ERR_337:0, DET_RANGE_ERR_338:0, DET_RANGE_ERR_339:0, DET_RANGE_ERR_340:0, DET_RANGE_VELOCITY_337:16384, DET_RANGE_VELOCITY_338:16384, DET_RANGE_VELOCITY_339:16384, DET_RANGE_VELOCITY_340:16384, DET_RANGE_VELOCITY_ERR_337:0, DET_RANGE_VELOCITY_ERR_338:0, DET_RANGE_VELOCITY_ERR_339:0, DET_RANGE_VELOCITY_ERR_340:0, DET_RCS_337:128, DET_RCS_338:128, DET_RCS_339:128, DET_RCS_340:128, DET_SNR_337:0, DET_SNR_338:0, DET_SNR_339:0, DET_SNR_340:0, DET_SUPER_RES_TARGET_337:0, DET_SUPER_RES_TARGET_338:0, DET_SUPER_RES_TARGET_339:0, DET_SUPER_RES_TARGET_340:0]}, provided-interface=Pi_SG_Detections_337_340_AL
      Pp_SG_Detections_341_344_AL: nonqueued-sender-com-spec{data-element=Vdp_SG_Detections_341_344_AL, init-value=fields=[DET_AZIMUTH_341:0, DET_AZIMUTH_342:0, DET_AZIMUTH_343:0, DET_AZIMUTH_344:0, DET_AZIMUTH_ERR_341:0, DET_AZIMUTH_ERR_342:0, DET_AZIMUTH_ERR_343:0, DET_AZIMUTH_ERR_344:0, DET_BELOW_RAIN_THOLD_341:0, DET_BELOW_RAIN_THOLD_342:0, DET_BELOW_RAIN_THOLD_343:0, DET_BELOW_RAIN_THOLD_344:0, DET_BI_STATIC_FLAG_341:0, DET_BI_STATIC_FLAG_342:0, DET_BI_STATIC_FLAG_343:0, DET_BI_STATIC_FLAG_344:0, DET_CONFD_AZIMUTH_341:0, DET_CONFD_AZIMUTH_342:0, DET_CONFD_AZIMUTH_343:0, DET_CONFD_AZIMUTH_344:0, DET_CONFD_ELEVATION_341:0, DET_CONFD_ELEVATION_342:0, DET_CONFD_ELEVATION_343:0, DET_CONFD_ELEVATION_344:0, DET_ELEVATION_341:0, DET_ELEVATION_342:0, DET_ELEVATION_343:0, DET_ELEVATION_344:0, DET_ELEVATION_ERR_341:0, DET_ELEVATION_ERR_342:0, DET_ELEVATION_ERR_343:0, DET_ELEVATION_ERR_344:0, DET_EXISTENCE_PROB_341:0, DET_EXISTENCE_PROB_342:0, DET_EXISTENCE_PROB_343:0, DET_EXISTENCE_PROB_344:0, DET_HVC_FLAG_341:0, DET_HVC_FLAG_342:0, DET_HVC_FLAG_343:0, DET_HVC_FLAG_344:0, DET_IDM_341:0, DET_IDM_342:0, DET_IDM_343:0, DET_IDM_344:0, DET_MH_CRC16_341_344:0, DET_MH_CYCLE_COUNTER_341_344:0, DET_MH_SCAN_INDEX_4LSB_341_344:0, DET_MTD_341:0, DET_MTD_342:0, DET_MTD_343:0, DET_MTD_344:0, DET_PROB_1STAZHYPO_341:0, DET_PROB_1STAZHYPO_342:0, DET_PROB_1STAZHYPO_343:0, DET_PROB_1STAZHYPO_344:0, DET_RANGE_341:0, DET_RANGE_342:0, DET_RANGE_343:0, DET_RANGE_344:0, DET_RANGE_ERR_341:0, DET_RANGE_ERR_342:0, DET_RANGE_ERR_343:0, DET_RANGE_ERR_344:0, DET_RANGE_VELOCITY_341:16384, DET_RANGE_VELOCITY_342:16384, DET_RANGE_VELOCITY_343:16384, DET_RANGE_VELOCITY_344:16384, DET_RANGE_VELOCITY_ERR_341:0, DET_RANGE_VELOCITY_ERR_342:0, DET_RANGE_VELOCITY_ERR_343:0, DET_RANGE_VELOCITY_ERR_344:0, DET_RCS_341:128, DET_RCS_342:128, DET_RCS_343:128, DET_RCS_344:128, DET_SNR_341:0, DET_SNR_342:0, DET_SNR_343:0, DET_SNR_344:0, DET_SUPER_RES_TARGET_341:0, DET_SUPER_RES_TARGET_342:0, DET_SUPER_RES_TARGET_343:0, DET_SUPER_RES_TARGET_344:0]}, provided-interface=Pi_SG_Detections_341_344_AL
      Pp_SG_Detections_345_348_AL: nonqueued-sender-com-spec{data-element=Vdp_SG_Detections_345_348_AL, init-value=fields=[DET_AZIMUTH_345:0, DET_AZIMUTH_346:0, DET_AZIMUTH_347:0, DET_AZIMUTH_348:0, DET_AZIMUTH_ERR_345:0, DET_AZIMUTH_ERR_346:0, DET_AZIMUTH_ERR_347:0, DET_AZIMUTH_ERR_348:0, DET_BELOW_RAIN_THOLD_345:0, DET_BELOW_RAIN_THOLD_346:0, DET_BELOW_RAIN_THOLD_347:0, DET_BELOW_RAIN_THOLD_348:0, DET_BI_STATIC_FLAG_345:0, DET_BI_STATIC_FLAG_346:0, DET_BI_STATIC_FLAG_347:0, DET_BI_STATIC_FLAG_348:0, DET_CONFD_AZIMUTH_345:0, DET_CONFD_AZIMUTH_346:0, DET_CONFD_AZIMUTH_347:0, DET_CONFD_AZIMUTH_348:0, DET_CONFD_ELEVATION_345:0, DET_CONFD_ELEVATION_346:0, DET_CONFD_ELEVATION_347:0, DET_CONFD_ELEVATION_348:0, DET_ELEVATION_345:0, DET_ELEVATION_346:0, DET_ELEVATION_347:0, DET_ELEVATION_348:0, DET_ELEVATION_ERR_345:0, DET_ELEVATION_ERR_346:0, DET_ELEVATION_ERR_347:0, DET_ELEVATION_ERR_348:0, DET_EXISTENCE_PROB_345:0, DET_EXISTENCE_PROB_346:0, DET_EXISTENCE_PROB_347:0, DET_EXISTENCE_PROB_348:0, DET_HVC_FLAG_345:0, DET_HVC_FLAG_346:0, DET_HVC_FLAG_347:0, DET_HVC_FLAG_348:0, DET_IDM_345:0, DET_IDM_346:0, DET_IDM_347:0, DET_IDM_348:0, DET_MH_CRC16_345_348:0, DET_MH_CYCLE_COUNTER_345_348:0, DET_MH_SCAN_INDEX_4LSB_345_348:0, DET_MTD_345:0, DET_MTD_346:0, DET_MTD_347:0, DET_MTD_348:0, DET_PROB_1STAZHYPO_345:0, DET_PROB_1STAZHYPO_346:0, DET_PROB_1STAZHYPO_347:0, DET_PROB_1STAZHYPO_348:0, DET_RANGE_345:0, DET_RANGE_346:0, DET_RANGE_347:0, DET_RANGE_348:0, DET_RANGE_ERR_345:0, DET_RANGE_ERR_346:0, DET_RANGE_ERR_347:0, DET_RANGE_ERR_348:0, DET_RANGE_VELOCITY_345:16384, DET_RANGE_VELOCITY_346:16384, DET_RANGE_VELOCITY_347:16384, DET_RANGE_VELOCITY_348:16384, DET_RANGE_VELOCITY_ERR_345:0, DET_RANGE_VELOCITY_ERR_346:0, DET_RANGE_VELOCITY_ERR_347:0, DET_RANGE_VELOCITY_ERR_348:0, DET_RCS_345:128, DET_RCS_346:128, DET_RCS_347:128, DET_RCS_348:128, DET_SNR_345:0, DET_SNR_346:0, DET_SNR_347:0, DET_SNR_348:0, DET_SUPER_RES_TARGET_345:0, DET_SUPER_RES_TARGET_346:0, DET_SUPER_RES_TARGET_347:0, DET_SUPER_RES_TARGET_348:0]}, provided-interface=Pi_SG_Detections_345_348_AL
      Pp_SG_Detections_349_352_AL: nonqueued-sender-com-spec{data-element=Vdp_SG_Detections_349_352_AL, init-value=fields=[DET_AZIMUTH_349:0, DET_AZIMUTH_350:0, DET_AZIMUTH_351:0, DET_AZIMUTH_352:0, DET_AZIMUTH_ERR_349:0, DET_AZIMUTH_ERR_350:0, DET_AZIMUTH_ERR_351:0, DET_AZIMUTH_ERR_352:0, DET_BELOW_RAIN_THOLD_349:0, DET_BELOW_RAIN_THOLD_350:0, DET_BELOW_RAIN_THOLD_351:0, DET_BELOW_RAIN_THOLD_352:0, DET_BI_STATIC_FLAG_349:0, DET_BI_STATIC_FLAG_350:0, DET_BI_STATIC_FLAG_351:0, DET_BI_STATIC_FLAG_352:0, DET_CONFD_AZIMUTH_349:0, DET_CONFD_AZIMUTH_350:0, DET_CONFD_AZIMUTH_351:0, DET_CONFD_AZIMUTH_352:0, DET_CONFD_ELEVATION_349:0, DET_CONFD_ELEVATION_350:0, DET_CONFD_ELEVATION_351:0, DET_CONFD_ELEVATION_352:0, DET_ELEVATION_349:0, DET_ELEVATION_350:0, DET_ELEVATION_351:0, DET_ELEVATION_352:0, DET_ELEVATION_ERR_349:0, DET_ELEVATION_ERR_350:0, DET_ELEVATION_ERR_351:0, DET_ELEVATION_ERR_352:0, DET_EXISTENCE_PROB_349:0, DET_EXISTENCE_PROB_350:0, DET_EXISTENCE_PROB_351:0, DET_EXISTENCE_PROB_352:0, DET_HVC_FLAG_349:0, DET_HVC_FLAG_350:0, DET_HVC_FLAG_351:0, DET_HVC_FLAG_352:0, DET_IDM_349:0, DET_IDM_350:0, DET_IDM_351:0, DET_IDM_352:0, DET_MH_CRC16_349_352:0, DET_MH_CYCLE_COUNTER_349_352:0, DET_MH_SCAN_INDEX_4LSB_349_352:0, DET_MTD_349:0, DET_MTD_350:0, DET_MTD_351:0, DET_MTD_352:0, DET_PROB_1STAZHYPO_349:0, DET_PROB_1STAZHYPO_350:0, DET_PROB_1STAZHYPO_351:0, DET_PROB_1STAZHYPO_352:0, DET_RANGE_349:0, DET_RANGE_350:0, DET_RANGE_351:0, DET_RANGE_352:0, DET_RANGE_ERR_349:0, DET_RANGE_ERR_350:0, DET_RANGE_ERR_351:0, DET_RANGE_ERR_352:0, DET_RANGE_VELOCITY_349:16384, DET_RANGE_VELOCITY_350:16384, DET_RANGE_VELOCITY_351:16384, DET_RANGE_VELOCITY_352:16384, DET_RANGE_VELOCITY_ERR_349:0, DET_RANGE_VELOCITY_ERR_350:0, DET_RANGE_VELOCITY_ERR_351:0, DET_RANGE_VELOCITY_ERR_352:0, DET_RCS_349:128, DET_RCS_350:128, DET_RCS_351:128, DET_RCS_352:128, DET_SNR_349:0, DET_SNR_350:0, DET_SNR_351:0, DET_SNR_352:0, DET_SUPER_RES_TARGET_349:0, DET_SUPER_RES_TARGET_350:0, DET_SUPER_RES_TARGET_351:0, DET_SUPER_RES_TARGET_352:0]}, provided-interface=Pi_SG_Detections_349_352_AL
      Pp_SG_Detections_353_356_AL: nonqueued-sender-com-spec{data-element=Vdp_SG_Detections_353_356_AL, init-value=fields=[DET_AZIMUTH_353:0, DET_AZIMUTH_354:0, DET_AZIMUTH_355:0, DET_AZIMUTH_356:0, DET_AZIMUTH_ERR_353:0, DET_AZIMUTH_ERR_354:0, DET_AZIMUTH_ERR_355:0, DET_AZIMUTH_ERR_356:0, DET_BELOW_RAIN_THOLD_353:0, DET_BELOW_RAIN_THOLD_354:0, DET_BELOW_RAIN_THOLD_355:0, DET_BELOW_RAIN_THOLD_356:0, DET_BI_STATIC_FLAG_353:0, DET_BI_STATIC_FLAG_354:0, DET_BI_STATIC_FLAG_355:0, DET_BI_STATIC_FLAG_356:0, DET_CONFD_AZIMUTH_353:0, DET_CONFD_AZIMUTH_354:0, DET_CONFD_AZIMUTH_355:0, DET_CONFD_AZIMUTH_356:0, DET_CONFD_ELEVATION_353:0, DET_CONFD_ELEVATION_354:0, DET_CONFD_ELEVATION_355:0, DET_CONFD_ELEVATION_356:0, DET_ELEVATION_353:0, DET_ELEVATION_354:0, DET_ELEVATION_355:0, DET_ELEVATION_356:0, DET_ELEVATION_ERR_353:0, DET_ELEVATION_ERR_354:0, DET_ELEVATION_ERR_355:0, DET_ELEVATION_ERR_356:0, DET_EXISTENCE_PROB_353:0, DET_EXISTENCE_PROB_354:0, DET_EXISTENCE_PROB_355:0, DET_EXISTENCE_PROB_356:0, DET_HVC_FLAG_353:0, DET_HVC_FLAG_354:0, DET_HVC_FLAG_355:0, DET_HVC_FLAG_356:0, DET_IDM_353:0, DET_IDM_354:0, DET_IDM_355:0, DET_IDM_356:0, DET_MH_CRC16_353_356:0, DET_MH_CYCLE_COUNTER_353_356:0, DET_MH_SCAN_INDEX_4LSB_353_356:0, DET_MTD_353:0, DET_MTD_354:0, DET_MTD_355:0, DET_MTD_356:0, DET_PROB_1STAZHYPO_353:0, DET_PROB_1STAZHYPO_354:0, DET_PROB_1STAZHYPO_355:0, DET_PROB_1STAZHYPO_356:0, DET_RANGE_353:0, DET_RANGE_354:0, DET_RANGE_355:0, DET_RANGE_356:0, DET_RANGE_ERR_353:0, DET_RANGE_ERR_354:0, DET_RANGE_ERR_355:0, DET_RANGE_ERR_356:0, DET_RANGE_VELOCITY_353:16384, DET_RANGE_VELOCITY_354:16384, DET_RANGE_VELOCITY_355:16384, DET_RANGE_VELOCITY_356:16384, DET_RANGE_VELOCITY_ERR_353:0, DET_RANGE_VELOCITY_ERR_354:0, DET_RANGE_VELOCITY_ERR_355:0, DET_RANGE_VELOCITY_ERR_356:0, DET_RCS_353:128, DET_RCS_354:128, DET_RCS_355:128, DET_RCS_356:128, DET_SNR_353:0, DET_SNR_354:0, DET_SNR_355:0, DET_SNR_356:0, DET_SUPER_RES_TARGET_353:0, DET_SUPER_RES_TARGET_354:0, DET_SUPER_RES_TARGET_355:0, DET_SUPER_RES_TARGET_356:0]}, provided-interface=Pi_SG_Detections_353_356_AL
      Pp_SG_Detections_357_360_AL: nonqueued-sender-com-spec{data-element=Vdp_SG_Detections_357_360_AL, init-value=fields=[DET_AZIMUTH_357:0, DET_AZIMUTH_358:0, DET_AZIMUTH_359:0, DET_AZIMUTH_360:0, DET_AZIMUTH_ERR_357:0, DET_AZIMUTH_ERR_358:0, DET_AZIMUTH_ERR_359:0, DET_AZIMUTH_ERR_360:0, DET_BELOW_RAIN_THOLD_357:0, DET_BELOW_RAIN_THOLD_358:0, DET_BELOW_RAIN_THOLD_359:0, DET_BELOW_RAIN_THOLD_360:0, DET_BI_STATIC_FLAG_357:0, DET_BI_STATIC_FLAG_358:0, DET_BI_STATIC_FLAG_359:0, DET_BI_STATIC_FLAG_360:0, DET_CONFD_AZIMUTH_357:0, DET_CONFD_AZIMUTH_358:0, DET_CONFD_AZIMUTH_359:0, DET_CONFD_AZIMUTH_360:0, DET_CONFD_ELEVATION_357:0, DET_CONFD_ELEVATION_358:0, DET_CONFD_ELEVATION_359:0, DET_CONFD_ELEVATION_360:0, DET_ELEVATION_357:0, DET_ELEVATION_358:0, DET_ELEVATION_359:0, DET_ELEVATION_360:0, DET_ELEVATION_ERR_357:0, DET_ELEVATION_ERR_358:0, DET_ELEVATION_ERR_359:0, DET_ELEVATION_ERR_360:0, DET_EXISTENCE_PROB_357:0, DET_EXISTENCE_PROB_358:0, DET_EXISTENCE_PROB_359:0, DET_EXISTENCE_PROB_360:0, DET_HVC_FLAG_357:0, DET_HVC_FLAG_358:0, DET_HVC_FLAG_359:0, DET_HVC_FLAG_360:0, DET_IDM_357:0, DET_IDM_358:0, DET_IDM_359:0, DET_IDM_360:0, DET_MH_CRC16_357_360:0, DET_MH_CYCLE_COUNTER_357_360:0, DET_MH_SCAN_INDEX_4LSB_357_360:0, DET_MTD_357:0, DET_MTD_358:0, DET_MTD_359:0, DET_MTD_360:0, DET_PROB_1STAZHYPO_357:0, DET_PROB_1STAZHYPO_358:0, DET_PROB_1STAZHYPO_359:0, DET_PROB_1STAZHYPO_360:0, DET_RANGE_357:0, DET_RANGE_358:0, DET_RANGE_359:0, DET_RANGE_360:0, DET_RANGE_ERR_357:0, DET_RANGE_ERR_358:0, DET_RANGE_ERR_359:0, DET_RANGE_ERR_360:0, DET_RANGE_VELOCITY_357:16384, DET_RANGE_VELOCITY_358:16384, DET_RANGE_VELOCITY_359:16384, DET_RANGE_VELOCITY_360:16384, DET_RANGE_VELOCITY_ERR_357:0, DET_RANGE_VELOCITY_ERR_358:0, DET_RANGE_VELOCITY_ERR_359:0, DET_RANGE_VELOCITY_ERR_360:0, DET_RCS_357:128, DET_RCS_358:128, DET_RCS_359:128, DET_RCS_360:128, DET_SNR_357:0, DET_SNR_358:0, DET_SNR_359:0, DET_SNR_360:0, DET_SUPER_RES_TARGET_357:0, DET_SUPER_RES_TARGET_358:0, DET_SUPER_RES_TARGET_359:0, DET_SUPER_RES_TARGET_360:0]}, provided-interface=Pi_SG_Detections_357_360_AL
      Pp_SG_Detections_361_364_AL: nonqueued-sender-com-spec{data-element=Vdp_SG_Detections_361_364_AL, init-value=fields=[DET_AZIMUTH_361:0, DET_AZIMUTH_362:0, DET_AZIMUTH_363:0, DET_AZIMUTH_364:0, DET_AZIMUTH_ERR_361:0, DET_AZIMUTH_ERR_362:0, DET_AZIMUTH_ERR_363:0, DET_AZIMUTH_ERR_364:0, DET_BELOW_RAIN_THOLD_361:0, DET_BELOW_RAIN_THOLD_362:0, DET_BELOW_RAIN_THOLD_363:0, DET_BELOW_RAIN_THOLD_364:0, DET_BI_STATIC_FLAG_361:0, DET_BI_STATIC_FLAG_362:0, DET_BI_STATIC_FLAG_363:0, DET_BI_STATIC_FLAG_364:0, DET_CONFD_AZIMUTH_361:0, DET_CONFD_AZIMUTH_362:0, DET_CONFD_AZIMUTH_363:0, DET_CONFD_AZIMUTH_364:0, DET_CONFD_ELEVATION_361:0, DET_CONFD_ELEVATION_362:0, DET_CONFD_ELEVATION_363:0, DET_CONFD_ELEVATION_364:0, DET_ELEVATION_361:0, DET_ELEVATION_362:0, DET_ELEVATION_363:0, DET_ELEVATION_364:0, DET_ELEVATION_ERR_361:0, DET_ELEVATION_ERR_362:0, DET_ELEVATION_ERR_363:0, DET_ELEVATION_ERR_364:0, DET_EXISTENCE_PROB_361:0, DET_EXISTENCE_PROB_362:0, DET_EXISTENCE_PROB_363:0, DET_EXISTENCE_PROB_364:0, DET_HVC_FLAG_361:0, DET_HVC_FLAG_362:0, DET_HVC_FLAG_363:0, DET_HVC_FLAG_364:0, DET_IDM_361:0, DET_IDM_362:0, DET_IDM_363:0, DET_IDM_364:0, DET_MH_CRC16_361_364:0, DET_MH_CYCLE_COUNTER_361_364:0, DET_MH_SCAN_INDEX_4LSB_361_364:0, DET_MTD_361:0, DET_MTD_362:0, DET_MTD_363:0, DET_MTD_364:0, DET_PROB_1STAZHYPO_361:0, DET_PROB_1STAZHYPO_362:0, DET_PROB_1STAZHYPO_363:0, DET_PROB_1STAZHYPO_364:0, DET_RANGE_361:0, DET_RANGE_362:0, DET_RANGE_363:0, DET_RANGE_364:0, DET_RANGE_ERR_361:0, DET_RANGE_ERR_362:0, DET_RANGE_ERR_363:0, DET_RANGE_ERR_364:0, DET_RANGE_VELOCITY_361:16384, DET_RANGE_VELOCITY_362:16384, DET_RANGE_VELOCITY_363:16384, DET_RANGE_VELOCITY_364:16384, DET_RANGE_VELOCITY_ERR_361:0, DET_RANGE_VELOCITY_ERR_362:0, DET_RANGE_VELOCITY_ERR_363:0, DET_RANGE_VELOCITY_ERR_364:0, DET_RCS_361:128, DET_RCS_362:128, DET_RCS_363:128, DET_RCS_364:128, DET_SNR_361:0, DET_SNR_362:0, DET_SNR_363:0, DET_SNR_364:0, DET_SUPER_RES_TARGET_361:0, DET_SUPER_RES_TARGET_362:0, DET_SUPER_RES_TARGET_363:0, DET_SUPER_RES_TARGET_364:0]}, provided-interface=Pi_SG_Detections_361_364_AL
      Pp_SG_Detections_365_368_AL: nonqueued-sender-com-spec{data-element=Vdp_SG_Detections_365_368_AL, init-value=fields=[DET_AZIMUTH_365:0, DET_AZIMUTH_366:0, DET_AZIMUTH_367:0, DET_AZIMUTH_368:0, DET_AZIMUTH_ERR_365:0, DET_AZIMUTH_ERR_366:0, DET_AZIMUTH_ERR_367:0, DET_AZIMUTH_ERR_368:0, DET_BELOW_RAIN_THOLD_365:0, DET_BELOW_RAIN_THOLD_366:0, DET_BELOW_RAIN_THOLD_367:0, DET_BELOW_RAIN_THOLD_368:0, DET_BI_STATIC_FLAG_365:0, DET_BI_STATIC_FLAG_366:0, DET_BI_STATIC_FLAG_367:0, DET_BI_STATIC_FLAG_368:0, DET_CONFD_AZIMUTH_365:0, DET_CONFD_AZIMUTH_366:0, DET_CONFD_AZIMUTH_367:0, DET_CONFD_AZIMUTH_368:0, DET_CONFD_ELEVATION_365:0, DET_CONFD_ELEVATION_366:0, DET_CONFD_ELEVATION_367:0, DET_CONFD_ELEVATION_368:0, DET_ELEVATION_365:0, DET_ELEVATION_366:0, DET_ELEVATION_367:0, DET_ELEVATION_368:0, DET_ELEVATION_ERR_365:0, DET_ELEVATION_ERR_366:0, DET_ELEVATION_ERR_367:0, DET_ELEVATION_ERR_368:0, DET_EXISTENCE_PROB_365:0, DET_EXISTENCE_PROB_366:0, DET_EXISTENCE_PROB_367:0, DET_EXISTENCE_PROB_368:0, DET_HVC_FLAG_365:0, DET_HVC_FLAG_366:0, DET_HVC_FLAG_367:0, DET_HVC_FLAG_368:0, DET_IDM_365:0, DET_IDM_366:0, DET_IDM_367:0, DET_IDM_368:0, DET_MH_CRC16_365_368:0, DET_MH_CYCLE_COUNTER_365_368:0, DET_MH_SCAN_INDEX_4LSB_365_368:0, DET_MTD_365:0, DET_MTD_366:0, DET_MTD_367:0, DET_MTD_368:0, DET_PROB_1STAZHYPO_365:0, DET_PROB_1STAZHYPO_366:0, DET_PROB_1STAZHYPO_367:0, DET_PROB_1STAZHYPO_368:0, DET_RANGE_365:0, DET_RANGE_366:0, DET_RANGE_367:0, DET_RANGE_368:0, DET_RANGE_ERR_365:0, DET_RANGE_ERR_366:0, DET_RANGE_ERR_367:0, DET_RANGE_ERR_368:0, DET_RANGE_VELOCITY_365:16384, DET_RANGE_VELOCITY_366:16384, DET_RANGE_VELOCITY_367:16384, DET_RANGE_VELOCITY_368:16384, DET_RANGE_VELOCITY_ERR_365:0, DET_RANGE_VELOCITY_ERR_366:0, DET_RANGE_VELOCITY_ERR_367:0, DET_RANGE_VELOCITY_ERR_368:0, DET_RCS_365:128, DET_RCS_366:128, DET_RCS_367:128, DET_RCS_368:128, DET_SNR_365:0, DET_SNR_366:0, DET_SNR_367:0, DET_SNR_368:0, DET_SUPER_RES_TARGET_365:0, DET_SUPER_RES_TARGET_366:0, DET_SUPER_RES_TARGET_367:0, DET_SUPER_RES_TARGET_368:0]}, provided-interface=Pi_SG_Detections_365_368_AL
      Pp_SG_Detections_369_372_AL: nonqueued-sender-com-spec{data-element=Vdp_SG_Detections_369_372_AL, init-value=fields=[DET_AZIMUTH_369:0, DET_AZIMUTH_370:0, DET_AZIMUTH_371:0, DET_AZIMUTH_372:0, DET_AZIMUTH_ERR_369:0, DET_AZIMUTH_ERR_370:0, DET_AZIMUTH_ERR_371:0, DET_AZIMUTH_ERR_372:0, DET_BELOW_RAIN_THOLD_369:0, DET_BELOW_RAIN_THOLD_370:0, DET_BELOW_RAIN_THOLD_371:0, DET_BELOW_RAIN_THOLD_372:0, DET_BI_STATIC_FLAG_369:0, DET_BI_STATIC_FLAG_370:0, DET_BI_STATIC_FLAG_371:0, DET_BI_STATIC_FLAG_372:0, DET_CONFD_AZIMUTH_369:0, DET_CONFD_AZIMUTH_370:0, DET_CONFD_AZIMUTH_371:0, DET_CONFD_AZIMUTH_372:0, DET_CONFD_ELEVATION_369:0, DET_CONFD_ELEVATION_370:0, DET_CONFD_ELEVATION_371:0, DET_CONFD_ELEVATION_372:0, DET_ELEVATION_369:0, DET_ELEVATION_370:0, DET_ELEVATION_371:0, DET_ELEVATION_372:0, DET_ELEVATION_ERR_369:0, DET_ELEVATION_ERR_370:0, DET_ELEVATION_ERR_371:0, DET_ELEVATION_ERR_372:0, DET_EXISTENCE_PROB_369:0, DET_EXISTENCE_PROB_370:0, DET_EXISTENCE_PROB_371:0, DET_EXISTENCE_PROB_372:0, DET_HVC_FLAG_369:0, DET_HVC_FLAG_370:0, DET_HVC_FLAG_371:0, DET_HVC_FLAG_372:0, DET_IDM_369:0, DET_IDM_370:0, DET_IDM_371:0, DET_IDM_372:0, DET_MH_CRC16_369_372:0, DET_MH_CYCLE_COUNTER_369_372:0, DET_MH_SCAN_INDEX_4LSB_369_372:0, DET_MTD_369:0, DET_MTD_370:0, DET_MTD_371:0, DET_MTD_372:0, DET_PROB_1STAZHYPO_369:0, DET_PROB_1STAZHYPO_370:0, DET_PROB_1STAZHYPO_371:0, DET_PROB_1STAZHYPO_372:0, DET_RANGE_369:0, DET_RANGE_370:0, DET_RANGE_371:0, DET_RANGE_372:0, DET_RANGE_ERR_369:0, DET_RANGE_ERR_370:0, DET_RANGE_ERR_371:0, DET_RANGE_ERR_372:0, DET_RANGE_VELOCITY_369:16384, DET_RANGE_VELOCITY_370:16384, DET_RANGE_VELOCITY_371:16384, DET_RANGE_VELOCITY_372:16384, DET_RANGE_VELOCITY_ERR_369:0, DET_RANGE_VELOCITY_ERR_370:0, DET_RANGE_VELOCITY_ERR_371:0, DET_RANGE_VELOCITY_ERR_372:0, DET_RCS_369:128, DET_RCS_370:128, DET_RCS_371:128, DET_RCS_372:128, DET_SNR_369:0, DET_SNR_370:0, DET_SNR_371:0, DET_SNR_372:0, DET_SUPER_RES_TARGET_369:0, DET_SUPER_RES_TARGET_370:0, DET_SUPER_RES_TARGET_371:0, DET_SUPER_RES_TARGET_372:0]}, provided-interface=Pi_SG_Detections_369_372_AL
      Pp_SG_Detections_373_376_AL: nonqueued-sender-com-spec{data-element=Vdp_SG_Detections_373_376_AL, init-value=fields=[DET_AZIMUTH_373:0, DET_AZIMUTH_374:0, DET_AZIMUTH_375:0, DET_AZIMUTH_376:0, DET_AZIMUTH_ERR_373:0, DET_AZIMUTH_ERR_374:0, DET_AZIMUTH_ERR_375:0, DET_AZIMUTH_ERR_376:0, DET_BELOW_RAIN_THOLD_373:0, DET_BELOW_RAIN_THOLD_374:0, DET_BELOW_RAIN_THOLD_375:0, DET_BELOW_RAIN_THOLD_376:0, DET_BI_STATIC_FLAG_373:0, DET_BI_STATIC_FLAG_374:0, DET_BI_STATIC_FLAG_375:0, DET_BI_STATIC_FLAG_376:0, DET_CONFD_AZIMUTH_373:0, DET_CONFD_AZIMUTH_374:0, DET_CONFD_AZIMUTH_375:0, DET_CONFD_AZIMUTH_376:0, DET_CONFD_ELEVATION_373:0, DET_CONFD_ELEVATION_374:0, DET_CONFD_ELEVATION_375:0, DET_CONFD_ELEVATION_376:0, DET_ELEVATION_373:0, DET_ELEVATION_374:0, DET_ELEVATION_375:0, DET_ELEVATION_376:0, DET_ELEVATION_ERR_373:0, DET_ELEVATION_ERR_374:0, DET_ELEVATION_ERR_375:0, DET_ELEVATION_ERR_376:0, DET_EXISTENCE_PROB_373:0, DET_EXISTENCE_PROB_374:0, DET_EXISTENCE_PROB_375:0, DET_EXISTENCE_PROB_376:0, DET_HVC_FLAG_373:0, DET_HVC_FLAG_374:0, DET_HVC_FLAG_375:0, DET_HVC_FLAG_376:0, DET_IDM_373:0, DET_IDM_374:0, DET_IDM_375:0, DET_IDM_376:0, DET_MH_CRC16_373_376:0, DET_MH_CYCLE_COUNTER_373_376:0, DET_MH_SCAN_INDEX_4LSB_373_376:0, DET_MTD_373:0, DET_MTD_374:0, DET_MTD_375:0, DET_MTD_376:0, DET_PROB_1STAZHYPO_373:0, DET_PROB_1STAZHYPO_374:0, DET_PROB_1STAZHYPO_375:0, DET_PROB_1STAZHYPO_376:0, DET_RANGE_373:0, DET_RANGE_374:0, DET_RANGE_375:0, DET_RANGE_376:0, DET_RANGE_ERR_373:0, DET_RANGE_ERR_374:0, DET_RANGE_ERR_375:0, DET_RANGE_ERR_376:0, DET_RANGE_VELOCITY_373:16384, DET_RANGE_VELOCITY_374:16384, DET_RANGE_VELOCITY_375:16384, DET_RANGE_VELOCITY_376:16384, DET_RANGE_VELOCITY_ERR_373:0, DET_RANGE_VELOCITY_ERR_374:0, DET_RANGE_VELOCITY_ERR_375:0, DET_RANGE_VELOCITY_ERR_376:0, DET_RCS_373:128, DET_RCS_374:128, DET_RCS_375:128, DET_RCS_376:128, DET_SNR_373:0, DET_SNR_374:0, DET_SNR_375:0, DET_SNR_376:0, DET_SUPER_RES_TARGET_373:0, DET_SUPER_RES_TARGET_374:0, DET_SUPER_RES_TARGET_375:0, DET_SUPER_RES_TARGET_376:0]}, provided-interface=Pi_SG_Detections_373_376_AL
      Pp_SG_Detections_377_380_AL: nonqueued-sender-com-spec{data-element=Vdp_SG_Detections_377_380_AL, init-value=fields=[DET_AZIMUTH_377:0, DET_AZIMUTH_378:0, DET_AZIMUTH_379:0, DET_AZIMUTH_380:0, DET_AZIMUTH_ERR_377:0, DET_AZIMUTH_ERR_378:0, DET_AZIMUTH_ERR_379:0, DET_AZIMUTH_ERR_380:0, DET_BELOW_RAIN_THOLD_377:0, DET_BELOW_RAIN_THOLD_378:0, DET_BELOW_RAIN_THOLD_379:0, DET_BELOW_RAIN_THOLD_380:0, DET_BI_STATIC_FLAG_377:0, DET_BI_STATIC_FLAG_378:0, DET_BI_STATIC_FLAG_379:0, DET_BI_STATIC_FLAG_380:0, DET_CONFD_AZIMUTH_377:0, DET_CONFD_AZIMUTH_378:0, DET_CONFD_AZIMUTH_379:0, DET_CONFD_AZIMUTH_380:0, DET_CONFD_ELEVATION_377:0, DET_CONFD_ELEVATION_378:0, DET_CONFD_ELEVATION_379:0, DET_CONFD_ELEVATION_380:0, DET_ELEVATION_377:0, DET_ELEVATION_378:0, DET_ELEVATION_379:0, DET_ELEVATION_380:0, DET_ELEVATION_ERR_377:0, DET_ELEVATION_ERR_378:0, DET_ELEVATION_ERR_379:0, DET_ELEVATION_ERR_380:0, DET_EXISTENCE_PROB_377:0, DET_EXISTENCE_PROB_378:0, DET_EXISTENCE_PROB_379:0, DET_EXISTENCE_PROB_380:0, DET_HVC_FLAG_377:0, DET_HVC_FLAG_378:0, DET_HVC_FLAG_379:0, DET_HVC_FLAG_380:0, DET_IDM_377:0, DET_IDM_378:0, DET_IDM_379:0, DET_IDM_380:0, DET_MH_CRC16_377_380:0, DET_MH_CYCLE_COUNTER_377_380:0, DET_MH_SCAN_INDEX_4LSB_377_380:0, DET_MTD_377:0, DET_MTD_378:0, DET_MTD_379:0, DET_MTD_380:0, DET_PROB_1STAZHYPO_377:0, DET_PROB_1STAZHYPO_378:0, DET_PROB_1STAZHYPO_379:0, DET_PROB_1STAZHYPO_380:0, DET_RANGE_377:0, DET_RANGE_378:0, DET_RANGE_379:0, DET_RANGE_380:0, DET_RANGE_ERR_377:0, DET_RANGE_ERR_378:0, DET_RANGE_ERR_379:0, DET_RANGE_ERR_380:0, DET_RANGE_VELOCITY_377:16384, DET_RANGE_VELOCITY_378:16384, DET_RANGE_VELOCITY_379:16384, DET_RANGE_VELOCITY_380:16384, DET_RANGE_VELOCITY_ERR_377:0, DET_RANGE_VELOCITY_ERR_378:0, DET_RANGE_VELOCITY_ERR_379:0, DET_RANGE_VELOCITY_ERR_380:0, DET_RCS_377:128, DET_RCS_378:128, DET_RCS_379:128, DET_RCS_380:128, DET_SNR_377:0, DET_SNR_378:0, DET_SNR_379:0, DET_SNR_380:0, DET_SUPER_RES_TARGET_377:0, DET_SUPER_RES_TARGET_378:0, DET_SUPER_RES_TARGET_379:0, DET_SUPER_RES_TARGET_380:0]}, provided-interface=Pi_SG_Detections_377_380_AL
      Pp_SG_Detections_381_384_AL: nonqueued-sender-com-spec{data-element=Vdp_SG_Detections_381_384_AL, init-value=fields=[DET_AZIMUTH_381:0, DET_AZIMUTH_382:0, DET_AZIMUTH_383:0, DET_AZIMUTH_384:0, DET_AZIMUTH_ERR_381:0, DET_AZIMUTH_ERR_382:0, DET_AZIMUTH_ERR_383:0, DET_AZIMUTH_ERR_384:0, DET_BELOW_RAIN_THOLD_381:0, DET_BELOW_RAIN_THOLD_382:0, DET_BELOW_RAIN_THOLD_383:0, DET_BELOW_RAIN_THOLD_384:0, DET_BI_STATIC_FLAG_381:0, DET_BI_STATIC_FLAG_382:0, DET_BI_STATIC_FLAG_383:0, DET_BI_STATIC_FLAG_384:0, DET_CONFD_AZIMUTH_381:0, DET_CONFD_AZIMUTH_382:0, DET_CONFD_AZIMUTH_383:0, DET_CONFD_AZIMUTH_384:0, DET_CONFD_ELEVATION_381:0, DET_CONFD_ELEVATION_382:0, DET_CONFD_ELEVATION_383:0, DET_CONFD_ELEVATION_384:0, DET_ELEVATION_381:0, DET_ELEVATION_382:0, DET_ELEVATION_383:0, DET_ELEVATION_384:0, DET_ELEVATION_ERR_381:0, DET_ELEVATION_ERR_382:0, DET_ELEVATION_ERR_383:0, DET_ELEVATION_ERR_384:0, DET_EXISTENCE_PROB_381:0, DET_EXISTENCE_PROB_382:0, DET_EXISTENCE_PROB_383:0, DET_EXISTENCE_PROB_384:0, DET_HVC_FLAG_381:0, DET_HVC_FLAG_382:0, DET_HVC_FLAG_383:0, DET_HVC_FLAG_384:0, DET_IDM_381:0, DET_IDM_382:0, DET_IDM_383:0, DET_IDM_384:0, DET_MH_CRC16_381_384:0, DET_MH_CYCLE_COUNTER_381_384:0, DET_MH_SCAN_INDEX_4LSB_381_384:0, DET_MTD_381:0, DET_MTD_382:0, DET_MTD_383:0, DET_MTD_384:0, DET_PROB_1STAZHYPO_381:0, DET_PROB_1STAZHYPO_382:0, DET_PROB_1STAZHYPO_383:0, DET_PROB_1STAZHYPO_384:0, DET_RANGE_381:0, DET_RANGE_382:0, DET_RANGE_383:0, DET_RANGE_384:0, DET_RANGE_ERR_381:0, DET_RANGE_ERR_382:0, DET_RANGE_ERR_383:0, DET_RANGE_ERR_384:0, DET_RANGE_VELOCITY_381:16384, DET_RANGE_VELOCITY_382:16384, DET_RANGE_VELOCITY_383:16384, DET_RANGE_VELOCITY_384:16384, DET_RANGE_VELOCITY_ERR_381:0, DET_RANGE_VELOCITY_ERR_382:0, DET_RANGE_VELOCITY_ERR_383:0, DET_RANGE_VELOCITY_ERR_384:0, DET_RCS_381:128, DET_RCS_382:128, DET_RCS_383:128, DET_RCS_384:128, DET_SNR_381:0, DET_SNR_382:0, DET_SNR_383:0, DET_SNR_384:0, DET_SUPER_RES_TARGET_381:0, DET_SUPER_RES_TARGET_382:0, DET_SUPER_RES_TARGET_383:0, DET_SUPER_RES_TARGET_384:0]}, provided-interface=Pi_SG_Detections_381_384_AL
      Pp_SG_Detections_385_388_AL: nonqueued-sender-com-spec{data-element=Vdp_SG_Detections_385_388_AL, init-value=fields=[DET_AZIMUTH_385:0, DET_AZIMUTH_386:0, DET_AZIMUTH_387:0, DET_AZIMUTH_388:0, DET_AZIMUTH_ERR_385:0, DET_AZIMUTH_ERR_386:0, DET_AZIMUTH_ERR_387:0, DET_AZIMUTH_ERR_388:0, DET_BELOW_RAIN_THOLD_385:0, DET_BELOW_RAIN_THOLD_386:0, DET_BELOW_RAIN_THOLD_387:0, DET_BELOW_RAIN_THOLD_388:0, DET_BI_STATIC_FLAG_385:0, DET_BI_STATIC_FLAG_386:0, DET_BI_STATIC_FLAG_387:0, DET_BI_STATIC_FLAG_388:0, DET_CONFD_AZIMUTH_385:0, DET_CONFD_AZIMUTH_386:0, DET_CONFD_AZIMUTH_387:0, DET_CONFD_AZIMUTH_388:0, DET_CONFD_ELEVATION_385:0, DET_CONFD_ELEVATION_386:0, DET_CONFD_ELEVATION_387:0, DET_CONFD_ELEVATION_388:0, DET_ELEVATION_385:0, DET_ELEVATION_386:0, DET_ELEVATION_387:0, DET_ELEVATION_388:0, DET_ELEVATION_ERR_385:0, DET_ELEVATION_ERR_386:0, DET_ELEVATION_ERR_387:0, DET_ELEVATION_ERR_388:0, DET_EXISTENCE_PROB_385:0, DET_EXISTENCE_PROB_386:0, DET_EXISTENCE_PROB_387:0, DET_EXISTENCE_PROB_388:0, DET_HVC_FLAG_385:0, DET_HVC_FLAG_386:0, DET_HVC_FLAG_387:0, DET_HVC_FLAG_388:0, DET_IDM_385:0, DET_IDM_386:0, DET_IDM_387:0, DET_IDM_388:0, DET_MH_CRC16_385_388:0, DET_MH_CYCLE_COUNTER_385_388:0, DET_MH_SCAN_INDEX_4LSB_385_388:0, DET_MTD_385:0, DET_MTD_386:0, DET_MTD_387:0, DET_MTD_388:0, DET_PROB_1STAZHYPO_385:0, DET_PROB_1STAZHYPO_386:0, DET_PROB_1STAZHYPO_387:0, DET_PROB_1STAZHYPO_388:0, DET_RANGE_385:0, DET_RANGE_386:0, DET_RANGE_387:0, DET_RANGE_388:0, DET_RANGE_ERR_385:0, DET_RANGE_ERR_386:0, DET_RANGE_ERR_387:0, DET_RANGE_ERR_388:0, DET_RANGE_VELOCITY_385:16384, DET_RANGE_VELOCITY_386:16384, DET_RANGE_VELOCITY_387:16384, DET_RANGE_VELOCITY_388:16384, DET_RANGE_VELOCITY_ERR_385:0, DET_RANGE_VELOCITY_ERR_386:0, DET_RANGE_VELOCITY_ERR_387:0, DET_RANGE_VELOCITY_ERR_388:0, DET_RCS_385:128, DET_RCS_386:128, DET_RCS_387:128, DET_RCS_388:128, DET_SNR_385:0, DET_SNR_386:0, DET_SNR_387:0, DET_SNR_388:0, DET_SUPER_RES_TARGET_385:0, DET_SUPER_RES_TARGET_386:0, DET_SUPER_RES_TARGET_387:0, DET_SUPER_RES_TARGET_388:0]}, provided-interface=Pi_SG_Detections_385_388_AL
      Pp_SG_Detections_389_392_AL: nonqueued-sender-com-spec{data-element=Vdp_SG_Detections_389_392_AL, init-value=fields=[DET_AZIMUTH_389:0, DET_AZIMUTH_390:0, DET_AZIMUTH_391:0, DET_AZIMUTH_392:0, DET_AZIMUTH_ERR_389:0, DET_AZIMUTH_ERR_390:0, DET_AZIMUTH_ERR_391:0, DET_AZIMUTH_ERR_392:0, DET_BELOW_RAIN_THOLD_389:0, DET_BELOW_RAIN_THOLD_390:0, DET_BELOW_RAIN_THOLD_391:0, DET_BELOW_RAIN_THOLD_392:0, DET_BI_STATIC_FLAG_389:0, DET_BI_STATIC_FLAG_390:0, DET_BI_STATIC_FLAG_391:0, DET_BI_STATIC_FLAG_392:0, DET_CONFD_AZIMUTH_389:0, DET_CONFD_AZIMUTH_390:0, DET_CONFD_AZIMUTH_391:0, DET_CONFD_AZIMUTH_392:0, DET_CONFD_ELEVATION_389:0, DET_CONFD_ELEVATION_390:0, DET_CONFD_ELEVATION_391:0, DET_CONFD_ELEVATION_392:0, DET_ELEVATION_389:0, DET_ELEVATION_390:0, DET_ELEVATION_391:0, DET_ELEVATION_392:0, DET_ELEVATION_ERR_389:0, DET_ELEVATION_ERR_390:0, DET_ELEVATION_ERR_391:0, DET_ELEVATION_ERR_392:0, DET_EXISTENCE_PROB_389:0, DET_EXISTENCE_PROB_390:0, DET_EXISTENCE_PROB_391:0, DET_EXISTENCE_PROB_392:0, DET_HVC_FLAG_389:0, DET_HVC_FLAG_390:0, DET_HVC_FLAG_391:0, DET_HVC_FLAG_392:0, DET_IDM_389:0, DET_IDM_390:0, DET_IDM_391:0, DET_IDM_392:0, DET_MH_CRC16_389_392:0, DET_MH_CYCLE_COUNTER_389_392:0, DET_MH_SCAN_INDEX_4LSB_389_392:0, DET_MTD_389:0, DET_MTD_390:0, DET_MTD_391:0, DET_MTD_392:0, DET_PROB_1STAZHYPO_389:0, DET_PROB_1STAZHYPO_390:0, DET_PROB_1STAZHYPO_391:0, DET_PROB_1STAZHYPO_392:0, DET_RANGE_389:0, DET_RANGE_390:0, DET_RANGE_391:0, DET_RANGE_392:0, DET_RANGE_ERR_389:0, DET_RANGE_ERR_390:0, DET_RANGE_ERR_391:0, DET_RANGE_ERR_392:0, DET_RANGE_VELOCITY_389:16384, DET_RANGE_VELOCITY_390:16384, DET_RANGE_VELOCITY_391:16384, DET_RANGE_VELOCITY_392:16384, DET_RANGE_VELOCITY_ERR_389:0, DET_RANGE_VELOCITY_ERR_390:0, DET_RANGE_VELOCITY_ERR_391:0, DET_RANGE_VELOCITY_ERR_392:0, DET_RCS_389:128, DET_RCS_390:128, DET_RCS_391:128, DET_RCS_392:128, DET_SNR_389:0, DET_SNR_390:0, DET_SNR_391:0, DET_SNR_392:0, DET_SUPER_RES_TARGET_389:0, DET_SUPER_RES_TARGET_390:0, DET_SUPER_RES_TARGET_391:0, DET_SUPER_RES_TARGET_392:0]}, provided-interface=Pi_SG_Detections_389_392_AL
      Pp_SG_Detections_393_396_AL: nonqueued-sender-com-spec{data-element=Vdp_SG_Detections_393_396_AL, init-value=fields=[DET_AZIMUTH_393:0, DET_AZIMUTH_394:0, DET_AZIMUTH_395:0, DET_AZIMUTH_396:0, DET_AZIMUTH_ERR_393:0, DET_AZIMUTH_ERR_394:0, DET_AZIMUTH_ERR_395:0, DET_AZIMUTH_ERR_396:0, DET_BELOW_RAIN_THOLD_393:0, DET_BELOW_RAIN_THOLD_394:0, DET_BELOW_RAIN_THOLD_395:0, DET_BELOW_RAIN_THOLD_396:0, DET_BI_STATIC_FLAG_393:0, DET_BI_STATIC_FLAG_394:0, DET_BI_STATIC_FLAG_395:0, DET_BI_STATIC_FLAG_396:0, DET_CONFD_AZIMUTH_393:0, DET_CONFD_AZIMUTH_394:0, DET_CONFD_AZIMUTH_395:0, DET_CONFD_AZIMUTH_396:0, DET_CONFD_ELEVATION_393:0, DET_CONFD_ELEVATION_394:0, DET_CONFD_ELEVATION_395:0, DET_CONFD_ELEVATION_396:0, DET_ELEVATION_393:0, DET_ELEVATION_394:0, DET_ELEVATION_395:0, DET_ELEVATION_396:0, DET_ELEVATION_ERR_393:0, DET_ELEVATION_ERR_394:0, DET_ELEVATION_ERR_395:0, DET_ELEVATION_ERR_396:0, DET_EXISTENCE_PROB_393:0, DET_EXISTENCE_PROB_394:0, DET_EXISTENCE_PROB_395:0, DET_EXISTENCE_PROB_396:0, DET_HVC_FLAG_393:0, DET_HVC_FLAG_394:0, DET_HVC_FLAG_395:0, DET_HVC_FLAG_396:0, DET_IDM_393:0, DET_IDM_394:0, DET_IDM_395:0, DET_IDM_396:0, DET_MH_CRC16_393_396:0, DET_MH_CYCLE_COUNTER_393_396:0, DET_MH_SCAN_INDEX_4LSB_393_396:0, DET_MTD_393:0, DET_MTD_394:0, DET_MTD_395:0, DET_MTD_396:0, DET_PROB_1STAZHYPO_393:0, DET_PROB_1STAZHYPO_394:0, DET_PROB_1STAZHYPO_395:0, DET_PROB_1STAZHYPO_396:0, DET_RANGE_393:0, DET_RANGE_394:0, DET_RANGE_395:0, DET_RANGE_396:0, DET_RANGE_ERR_393:0, DET_RANGE_ERR_394:0, DET_RANGE_ERR_395:0, DET_RANGE_ERR_396:0, DET_RANGE_VELOCITY_393:16384, DET_RANGE_VELOCITY_394:16384, DET_RANGE_VELOCITY_395:16384, DET_RANGE_VELOCITY_396:16384, DET_RANGE_VELOCITY_ERR_393:0, DET_RANGE_VELOCITY_ERR_394:0, DET_RANGE_VELOCITY_ERR_395:0, DET_RANGE_VELOCITY_ERR_396:0, DET_RCS_393:128, DET_RCS_394:128, DET_RCS_395:128, DET_RCS_396:128, DET_SNR_393:0, DET_SNR_394:0, DET_SNR_395:0, DET_SNR_396:0, DET_SUPER_RES_TARGET_393:0, DET_SUPER_RES_TARGET_394:0, DET_SUPER_RES_TARGET_395:0, DET_SUPER_RES_TARGET_396:0]}, provided-interface=Pi_SG_Detections_393_396_AL
      Pp_SG_Detections_397_400_AL: nonqueued-sender-com-spec{data-element=Vdp_SG_Detections_397_400_AL, init-value=fields=[DET_AZIMUTH_397:0, DET_AZIMUTH_398:0, DET_AZIMUTH_399:0, DET_AZIMUTH_400:0, DET_AZIMUTH_ERR_397:0, DET_AZIMUTH_ERR_398:0, DET_AZIMUTH_ERR_399:0, DET_AZIMUTH_ERR_400:0, DET_BELOW_RAIN_THOLD_397:0, DET_BELOW_RAIN_THOLD_398:0, DET_BELOW_RAIN_THOLD_399:0, DET_BELOW_RAIN_THOLD_400:0, DET_BI_STATIC_FLAG_397:0, DET_BI_STATIC_FLAG_398:0, DET_BI_STATIC_FLAG_399:0, DET_BI_STATIC_FLAG_400:0, DET_CONFD_AZIMUTH_397:0, DET_CONFD_AZIMUTH_398:0, DET_CONFD_AZIMUTH_399:0, DET_CONFD_AZIMUTH_400:0, DET_CONFD_ELEVATION_397:0, DET_CONFD_ELEVATION_398:0, DET_CONFD_ELEVATION_399:0, DET_CONFD_ELEVATION_400:0, DET_ELEVATION_397:0, DET_ELEVATION_398:0, DET_ELEVATION_399:0, DET_ELEVATION_400:0, DET_ELEVATION_ERR_397:0, DET_ELEVATION_ERR_398:0, DET_ELEVATION_ERR_399:0, DET_ELEVATION_ERR_400:0, DET_EXISTENCE_PROB_397:0, DET_EXISTENCE_PROB_398:0, DET_EXISTENCE_PROB_399:0, DET_EXISTENCE_PROB_400:0, DET_HVC_FLAG_397:0, DET_HVC_FLAG_398:0, DET_HVC_FLAG_399:0, DET_HVC_FLAG_400:0, DET_IDM_397:0, DET_IDM_398:0, DET_IDM_399:0, DET_IDM_400:0, DET_MH_CRC16_397_400:0, DET_MH_CYCLE_COUNTER_397_400:0, DET_MH_SCAN_INDEX_4LSB_397_400:0, DET_MTD_397:0, DET_MTD_398:0, DET_MTD_399:0, DET_MTD_400:0, DET_PROB_1STAZHYPO_397:0, DET_PROB_1STAZHYPO_398:0, DET_PROB_1STAZHYPO_399:0, DET_PROB_1STAZHYPO_400:0, DET_RANGE_397:0, DET_RANGE_398:0, DET_RANGE_399:0, DET_RANGE_400:0, DET_RANGE_ERR_397:0, DET_RANGE_ERR_398:0, DET_RANGE_ERR_399:0, DET_RANGE_ERR_400:0, DET_RANGE_VELOCITY_397:16384, DET_RANGE_VELOCITY_398:16384, DET_RANGE_VELOCITY_399:16384, DET_RANGE_VELOCITY_400:16384, DET_RANGE_VELOCITY_ERR_397:0, DET_RANGE_VELOCITY_ERR_398:0, DET_RANGE_VELOCITY_ERR_399:0, DET_RANGE_VELOCITY_ERR_400:0, DET_RCS_397:128, DET_RCS_398:128, DET_RCS_399:128, DET_RCS_400:128, DET_SNR_397:0, DET_SNR_398:0, DET_SNR_399:0, DET_SNR_400:0, DET_SUPER_RES_TARGET_397:0, DET_SUPER_RES_TARGET_398:0, DET_SUPER_RES_TARGET_399:0, DET_SUPER_RES_TARGET_400:0]}, provided-interface=Pi_SG_Detections_397_400_AL
    32 x require port:
      Rp_SG_Fusion_Detections_001_004_AL: nonqueued-receiver-com-spec{data-element=Vdp_SG_Fusion_Detections_001_004_AL, init-value=fields=[DET_AZIMUTH_001_Rx:0, DET_AZIMUTH_002_Rx:0, DET_AZIMUTH_003_Rx:0, DET_AZIMUTH_004_Rx:0, DET_AZIMUTH_ERR_001_Rx:0, DET_AZIMUTH_ERR_002_Rx:0, DET_AZIMUTH_ERR_003_Rx:0, DET_AZIMUTH_ERR_004_Rx:0, DET_BELOW_RAIN_THOLD_001_Rx:0, DET_BELOW_RAIN_THOLD_002_Rx:0, DET_BELOW_RAIN_THOLD_003_Rx:0, DET_BELOW_RAIN_THOLD_004_Rx:0, DET_BI_STATIC_FLAG_001_Rx:0, DET_BI_STATIC_FLAG_002_Rx:0, DET_BI_STATIC_FLAG_003_Rx:0, DET_BI_STATIC_FLAG_004_Rx:0, DET_CONFD_AZIMUTH_001_Rx:0, DET_CONFD_AZIMUTH_002_Rx:0, DET_CONFD_AZIMUTH_003_Rx:0, DET_CONFD_AZIMUTH_004_Rx:0, DET_CONFD_ELEVATION_001_Rx:0, DET_CONFD_ELEVATION_002_Rx:0, DET_CONFD_ELEVATION_003_Rx:0, DET_CONFD_ELEVATION_004_Rx:0, DET_ELEVATION_001_Rx:0, DET_ELEVATION_002_Rx:0, DET_ELEVATION_003_Rx:0, DET_ELEVATION_004_Rx:0, DET_ELEVATION_ERR_001_Rx:0, DET_ELEVATION_ERR_002_Rx:0, DET_ELEVATION_ERR_003_Rx:0, DET_ELEVATION_ERR_004_Rx:0, DET_EXISTENCE_PROB_001_Rx:0, DET_EXISTENCE_PROB_002_Rx:0, DET_EXISTENCE_PROB_003_Rx:0, DET_EXISTENCE_PROB_004_Rx:0, DET_HVC_FLAG_001_Rx:0, DET_HVC_FLAG_002_Rx:0, DET_HVC_FLAG_003_Rx:0, DET_HVC_FLAG_004_Rx:0, DET_IDM_001_Rx:0, DET_IDM_002_Rx:0, DET_IDM_003_Rx:0, DET_IDM_004_Rx:0, DET_MH_CRC16_001_004_Rx:0, DET_MH_CYCLE_COUNTER_001_004_Rx:0, DET_MH_SCAN_INDEX_4LSB_001_004_Rx:0, DET_MTD_001_Rx:0, DET_MTD_002_Rx:0, DET_MTD_003_Rx:0, DET_MTD_004_Rx:0, DET_PROB_1STAZHYPO_001_Rx:0, DET_PROB_1STAZHYPO_002_Rx:0, DET_PROB_1STAZHYPO_003_Rx:0, DET_PROB_1STAZHYPO_004_Rx:0, DET_RANGE_001_Rx:0, DET_RANGE_002_Rx:0, DET_RANGE_003_Rx:0, DET_RANGE_004_Rx:0, DET_RANGE_ERR_001_Rx:0, DET_RANGE_ERR_002_Rx:0, DET_RANGE_ERR_003_Rx:0, DET_RANGE_ERR_004_Rx:0, DET_RANGE_VELOCITY_001_Rx:0, DET_RANGE_VELOCITY_002_Rx:0, DET_RANGE_VELOCITY_003_Rx:0, DET_RANGE_VELOCITY_004_Rx:0, DET_RANGE_VELOCITY_ERR_001_Rx:0, DET_RANGE_VELOCITY_ERR_002_Rx:0, DET_RANGE_VELOCITY_ERR_003_Rx:0, DET_RANGE_VELOCITY_ERR_004_Rx:0, DET_RCS_001_Rx:0, DET_RCS_002_Rx:0, DET_RCS_003_Rx:0, DET_RCS_004_Rx:0, DET_SNR_001_Rx:0, DET_SNR_002_Rx:0, DET_SNR_003_Rx:0, DET_SNR_004_Rx:0, DET_SUPER_RES_TARGET_001_Rx:0, DET_SUPER_RES_TARGET_002_Rx:0, DET_SUPER_RES_TARGET_003_Rx:0, DET_SUPER_RES_TARGET_004_Rx:0]}, required-interface=Pi_SG_Fusion_Detections_001_004_AL
      Rp_SG_Fusion_Detections_005_008_AL: nonqueued-receiver-com-spec{data-element=Vdp_SG_Fusion_Detections_005_008_AL, init-value=fields=[DET_AZIMUTH_005_Rx:0, DET_AZIMUTH_006_Rx:0, DET_AZIMUTH_007_Rx:0, DET_AZIMUTH_008_Rx:0, DET_AZIMUTH_ERR_005_Rx:0, DET_AZIMUTH_ERR_006_Rx:0, DET_AZIMUTH_ERR_007_Rx:0, DET_AZIMUTH_ERR_008_Rx:0, DET_BELOW_RAIN_THOLD_005_Rx:0, DET_BELOW_RAIN_THOLD_006_Rx:0, DET_BELOW_RAIN_THOLD_007_Rx:0, DET_BELOW_RAIN_THOLD_008_Rx:0, DET_BI_STATIC_FLAG_005_Rx:0, DET_BI_STATIC_FLAG_006_Rx:0, DET_BI_STATIC_FLAG_007_Rx:0, DET_BI_STATIC_FLAG_008_Rx:0, DET_CONFD_AZIMUTH_005_Rx:0, DET_CONFD_AZIMUTH_006_Rx:0, DET_CONFD_AZIMUTH_007_Rx:0, DET_CONFD_AZIMUTH_008_Rx:0, DET_CONFD_ELEVATION_005_Rx:0, DET_CONFD_ELEVATION_006_Rx:0, DET_CONFD_ELEVATION_007_Rx:0, DET_CONFD_ELEVATION_008_Rx:0, DET_ELEVATION_005_Rx:0, DET_ELEVATION_006_Rx:0, DET_ELEVATION_007_Rx:0, DET_ELEVATION_008_Rx:0, DET_ELEVATION_ERR_005_Rx:0, DET_ELEVATION_ERR_006_Rx:0, DET_ELEVATION_ERR_007_Rx:0, DET_ELEVATION_ERR_008_Rx:0, DET_EXISTENCE_PROB_005_Rx:0, DET_EXISTENCE_PROB_006_Rx:0, DET_EXISTENCE_PROB_007_Rx:0, DET_EXISTENCE_PROB_008_Rx:0, DET_HVC_FLAG_005_Rx:0, DET_HVC_FLAG_006_Rx:0, DET_HVC_FLAG_007_Rx:0, DET_HVC_FLAG_008_Rx:0, DET_IDM_005_Rx:0, DET_IDM_006_Rx:0, DET_IDM_007_Rx:0, DET_IDM_008_Rx:0, DET_MH_CRC16_005_008_Rx:0, DET_MH_CYCLE_COUNTER_005_008_Rx:0, DET_MH_SCAN_INDEX_4LSB_005_008_Rx:0, DET_MTD_005_Rx:0, DET_MTD_006_Rx:0, DET_MTD_007_Rx:0, DET_MTD_008_Rx:0, DET_PROB_1STAZHYPO_005_Rx:0, DET_PROB_1STAZHYPO_006_Rx:0, DET_PROB_1STAZHYPO_007_Rx:0, DET_PROB_1STAZHYPO_008_Rx:0, DET_RANGE_005_Rx:0, DET_RANGE_006_Rx:0, DET_RANGE_007_Rx:0, DET_RANGE_008_Rx:0, DET_RANGE_ERR_005_Rx:0, DET_RANGE_ERR_006_Rx:0, DET_RANGE_ERR_007_Rx:0, DET_RANGE_ERR_008_Rx:0, DET_RANGE_VELOCITY_005_Rx:0, DET_RANGE_VELOCITY_006_Rx:0, DET_RANGE_VELOCITY_007_Rx:0, DET_RANGE_VELOCITY_008_Rx:0, DET_RANGE_VELOCITY_ERR_005_Rx:0, DET_RANGE_VELOCITY_ERR_006_Rx:0, DET_RANGE_VELOCITY_ERR_007_Rx:0, DET_RANGE_VELOCITY_ERR_008_Rx:0, DET_RCS_005_Rx:0, DET_RCS_006_Rx:0, DET_RCS_007_Rx:0, DET_RCS_008_Rx:0, DET_SNR_005_Rx:0, DET_SNR_006_Rx:0, DET_SNR_007_Rx:0, DET_SNR_008_Rx:0, DET_SUPER_RES_TARGET_005_Rx:0, DET_SUPER_RES_TARGET_006_Rx:0, DET_SUPER_RES_TARGET_007_Rx:0, DET_SUPER_RES_TARGET_008_Rx:0]}, required-interface=Pi_SG_Fusion_Detections_005_008_AL
      Rp_SG_Fusion_Detections_009_012_AL: nonqueued-receiver-com-spec{data-element=Vdp_SG_Fusion_Detections_009_012_AL, init-value=fields=[DET_AZIMUTH_009_Rx:0, DET_AZIMUTH_010_Rx:0, DET_AZIMUTH_011_Rx:0, DET_AZIMUTH_012_Rx:0, DET_AZIMUTH_ERR_009_Rx:0, DET_AZIMUTH_ERR_010_Rx:0, DET_AZIMUTH_ERR_011_Rx:0, DET_AZIMUTH_ERR_012_Rx:0, DET_BELOW_RAIN_THOLD_009_Rx:0, DET_BELOW_RAIN_THOLD_010_Rx:0, DET_BELOW_RAIN_THOLD_011_Rx:0, DET_BELOW_RAIN_THOLD_012_Rx:0, DET_BI_STATIC_FLAG_009_Rx:0, DET_BI_STATIC_FLAG_010_Rx:0, DET_BI_STATIC_FLAG_011_Rx:0, DET_BI_STATIC_FLAG_012_Rx:0, DET_CONFD_AZIMUTH_009_Rx:0, DET_CONFD_AZIMUTH_010_Rx:0, DET_CONFD_AZIMUTH_011_Rx:0, DET_CONFD_AZIMUTH_012_Rx:0, DET_CONFD_ELEVATION_009_Rx:0, DET_CONFD_ELEVATION_010_Rx:0, DET_CONFD_ELEVATION_011_Rx:0, DET_CONFD_ELEVATION_012_Rx:0, DET_ELEVATION_009_Rx:0, DET_ELEVATION_010_Rx:0, DET_ELEVATION_011_Rx:0, DET_ELEVATION_012_Rx:0, DET_ELEVATION_ERR_009_Rx:0, DET_ELEVATION_ERR_010_Rx:0, DET_ELEVATION_ERR_011_Rx:0, DET_ELEVATION_ERR_012_Rx:0, DET_EXISTENCE_PROB_009_Rx:0, DET_EXISTENCE_PROB_010_Rx:0, DET_EXISTENCE_PROB_011_Rx:0, DET_EXISTENCE_PROB_012_Rx:0, DET_HVC_FLAG_009_Rx:0, DET_HVC_FLAG_010_Rx:0, DET_HVC_FLAG_011_Rx:0, DET_HVC_FLAG_012_Rx:0, DET_IDM_009_Rx:0, DET_IDM_010_Rx:0, DET_IDM_011_Rx:0, DET_IDM_012_Rx:0, DET_MH_CRC16_009_012_Rx:0, DET_MH_CYCLE_COUNTER_009_012_Rx:0, DET_MH_SCAN_INDEX_4LSB_009_012_Rx:0, DET_MTD_009_Rx:0, DET_MTD_010_Rx:0, DET_MTD_011_Rx:0, DET_MTD_012_Rx:0, DET_PROB_1STAZHYPO_009_Rx:0, DET_PROB_1STAZHYPO_010_Rx:0, DET_PROB_1STAZHYPO_011_Rx:0, DET_PROB_1STAZHYPO_012_Rx:0, DET_RANGE_009_Rx:0, DET_RANGE_010_Rx:0, DET_RANGE_011_Rx:0, DET_RANGE_012_Rx:0, DET_RANGE_ERR_009_Rx:0, DET_RANGE_ERR_010_Rx:0, DET_RANGE_ERR_011_Rx:0, DET_RANGE_ERR_012_Rx:0, DET_RANGE_VELOCITY_009_Rx:0, DET_RANGE_VELOCITY_010_Rx:0, DET_RANGE_VELOCITY_011_Rx:0, DET_RANGE_VELOCITY_012_Rx:0, DET_RANGE_VELOCITY_ERR_009_Rx:0, DET_RANGE_VELOCITY_ERR_010_Rx:0, DET_RANGE_VELOCITY_ERR_011_Rx:0, DET_RANGE_VELOCITY_ERR_012_Rx:0, DET_RCS_009_Rx:0, DET_RCS_010_Rx:0, DET_RCS_011_Rx:0, DET_RCS_012_Rx:0, DET_SNR_009_Rx:0, DET_SNR_010_Rx:0, DET_SNR_011_Rx:0, DET_SNR_012_Rx:0, DET_SUPER_RES_TARGET_009_Rx:0, DET_SUPER_RES_TARGET_010_Rx:0, DET_SUPER_RES_TARGET_011_Rx:0, DET_SUPER_RES_TARGET_012_Rx:0]}, required-interface=Pi_SG_Fusion_Detections_009_012_AL
      Rp_SG_Fusion_Detections_013_016_AL: nonqueued-receiver-com-spec{data-element=Vdp_SG_Fusion_Detections_013_016_AL, init-value=fields=[DET_AZIMUTH_013_Rx:0, DET_AZIMUTH_014_Rx:0, DET_AZIMUTH_015_Rx:0, DET_AZIMUTH_016_Rx:0, DET_AZIMUTH_ERR_013_Rx:0, DET_AZIMUTH_ERR_014_Rx:0, DET_AZIMUTH_ERR_015_Rx:0, DET_AZIMUTH_ERR_016_Rx:0, DET_BELOW_RAIN_THOLD_013_Rx:0, DET_BELOW_RAIN_THOLD_014_Rx:0, DET_BELOW_RAIN_THOLD_015_Rx:0, DET_BELOW_RAIN_THOLD_016_Rx:0, DET_BI_STATIC_FLAG_013_Rx:0, DET_BI_STATIC_FLAG_014_Rx:0, DET_BI_STATIC_FLAG_015_Rx:0, DET_BI_STATIC_FLAG_016_Rx:0, DET_CONFD_AZIMUTH_013_Rx:0, DET_CONFD_AZIMUTH_014_Rx:0, DET_CONFD_AZIMUTH_015_Rx:0, DET_CONFD_AZIMUTH_016_Rx:0, DET_CONFD_ELEVATION_013_Rx:0, DET_CONFD_ELEVATION_014_Rx:0, DET_CONFD_ELEVATION_015_Rx:0, DET_CONFD_ELEVATION_016_Rx:0, DET_ELEVATION_013_Rx:0, DET_ELEVATION_014_Rx:0, DET_ELEVATION_015_Rx:0, DET_ELEVATION_016_Rx:0, DET_ELEVATION_ERR_013_Rx:0, DET_ELEVATION_ERR_014_Rx:0, DET_ELEVATION_ERR_015_Rx:0, DET_ELEVATION_ERR_016_Rx:0, DET_EXISTENCE_PROB_013_Rx:0, DET_EXISTENCE_PROB_014_Rx:0, DET_EXISTENCE_PROB_015_Rx:0, DET_EXISTENCE_PROB_016_Rx:0, DET_HVC_FLAG_013_Rx:0, DET_HVC_FLAG_014_Rx:0, DET_HVC_FLAG_015_Rx:0, DET_HVC_FLAG_016_Rx:0, DET_IDM_013_Rx:0, DET_IDM_014_Rx:0, DET_IDM_015_Rx:0, DET_IDM_016_Rx:0, DET_MH_CRC16_013_016_Rx:0, DET_MH_CYCLE_COUNTER_013_016_Rx:0, DET_MH_SCAN_INDEX_4LSB_013_016_Rx:0, DET_MTD_013_Rx:0, DET_MTD_014_Rx:0, DET_MTD_015_Rx:0, DET_MTD_016_Rx:0, DET_PROB_1STAZHYPO_013_Rx:0, DET_PROB_1STAZHYPO_014_Rx:0, DET_PROB_1STAZHYPO_015_Rx:0, DET_PROB_1STAZHYPO_016_Rx:0, DET_RANGE_013_Rx:0, DET_RANGE_014_Rx:0, DET_RANGE_015_Rx:0, DET_RANGE_016_Rx:0, DET_RANGE_ERR_013_Rx:0, DET_RANGE_ERR_014_Rx:0, DET_RANGE_ERR_015_Rx:0, DET_RANGE_ERR_016_Rx:0, DET_RANGE_VELOCITY_013_Rx:0, DET_RANGE_VELOCITY_014_Rx:0, DET_RANGE_VELOCITY_015_Rx:0, DET_RANGE_VELOCITY_016_Rx:0, DET_RANGE_VELOCITY_ERR_013_Rx:0, DET_RANGE_VELOCITY_ERR_014_Rx:0, DET_RANGE_VELOCITY_ERR_015_Rx:0, DET_RANGE_VELOCITY_ERR_016_Rx:0, DET_RCS_013_Rx:0, DET_RCS_014_Rx:0, DET_RCS_015_Rx:0, DET_RCS_016_Rx:0, DET_SNR_013_Rx:0, DET_SNR_014_Rx:0, DET_SNR_015_Rx:0, DET_SNR_016_Rx:0, DET_SUPER_RES_TARGET_013_Rx:0, DET_SUPER_RES_TARGET_014_Rx:0, DET_SUPER_RES_TARGET_015_Rx:0, DET_SUPER_RES_TARGET_016_Rx:0]}, required-interface=Pi_SG_Fusion_Detections_013_016_AL
      Rp_SG_Fusion_Detections_017_020_AL: nonqueued-receiver-com-spec{data-element=Vdp_SG_Fusion_Detections_017_020_AL, init-value=fields=[DET_AZIMUTH_017_Rx:0, DET_AZIMUTH_018_Rx:0, DET_AZIMUTH_019_Rx:0, DET_AZIMUTH_020_Rx:0, DET_AZIMUTH_ERR_017_Rx:0, DET_AZIMUTH_ERR_018_Rx:0, DET_AZIMUTH_ERR_019_Rx:0, DET_AZIMUTH_ERR_020_Rx:0, DET_BELOW_RAIN_THOLD_017_Rx:0, DET_BELOW_RAIN_THOLD_018_Rx:0, DET_BELOW_RAIN_THOLD_019_Rx:0, DET_BELOW_RAIN_THOLD_020_Rx:0, DET_BI_STATIC_FLAG_017_Rx:0, DET_BI_STATIC_FLAG_018_Rx:0, DET_BI_STATIC_FLAG_019_Rx:0, DET_BI_STATIC_FLAG_020_Rx:0, DET_CONFD_AZIMUTH_017_Rx:0, DET_CONFD_AZIMUTH_018_Rx:0, DET_CONFD_AZIMUTH_019_Rx:0, DET_CONFD_AZIMUTH_020_Rx:0, DET_CONFD_ELEVATION_017_Rx:0, DET_CONFD_ELEVATION_018_Rx:0, DET_CONFD_ELEVATION_019_Rx:0, DET_CONFD_ELEVATION_020_Rx:0, DET_ELEVATION_017_Rx:0, DET_ELEVATION_018_Rx:0, DET_ELEVATION_019_Rx:0, DET_ELEVATION_020_Rx:0, DET_ELEVATION_ERR_017_Rx:0, DET_ELEVATION_ERR_018_Rx:0, DET_ELEVATION_ERR_019_Rx:0, DET_ELEVATION_ERR_020_Rx:0, DET_EXISTENCE_PROB_017_Rx:0, DET_EXISTENCE_PROB_018_Rx:0, DET_EXISTENCE_PROB_019_Rx:0, DET_EXISTENCE_PROB_020_Rx:0, DET_HVC_FLAG_017_Rx:0, DET_HVC_FLAG_018_Rx:0, DET_HVC_FLAG_019_Rx:0, DET_HVC_FLAG_020_Rx:0, DET_IDM_017_Rx:0, DET_IDM_018_Rx:0, DET_IDM_019_Rx:0, DET_IDM_020_Rx:0, DET_MH_CRC16_017_020_Rx:0, DET_MH_CYCLE_COUNTER_017_020_Rx:0, DET_MH_SCAN_INDEX_4LSB_017_020_Rx:0, DET_MTD_017_Rx:0, DET_MTD_018_Rx:0, DET_MTD_019_Rx:0, DET_MTD_020_Rx:0, DET_PROB_1STAZHYPO_017_Rx:0, DET_PROB_1STAZHYPO_018_Rx:0, DET_PROB_1STAZHYPO_019_Rx:0, DET_PROB_1STAZHYPO_020_Rx:0, DET_RANGE_017_Rx:0, DET_RANGE_018_Rx:0, DET_RANGE_019_Rx:0, DET_RANGE_020_Rx:0, DET_RANGE_ERR_017_Rx:0, DET_RANGE_ERR_018_Rx:0, DET_RANGE_ERR_019_Rx:0, DET_RANGE_ERR_020_Rx:0, DET_RANGE_VELOCITY_017_Rx:0, DET_RANGE_VELOCITY_018_Rx:0, DET_RANGE_VELOCITY_019_Rx:0, DET_RANGE_VELOCITY_020_Rx:0, DET_RANGE_VELOCITY_ERR_017_Rx:0, DET_RANGE_VELOCITY_ERR_018_Rx:0, DET_RANGE_VELOCITY_ERR_019_Rx:0, DET_RANGE_VELOCITY_ERR_020_Rx:0, DET_RCS_017_Rx:0, DET_RCS_018_Rx:0, DET_RCS_019_Rx:0, DET_RCS_020_Rx:0, DET_SNR_017_Rx:0, DET_SNR_018_Rx:0, DET_SNR_019_Rx:0, DET_SNR_020_Rx:0, DET_SUPER_RES_TARGET_017_Rx:0, DET_SUPER_RES_TARGET_018_Rx:0, DET_SUPER_RES_TARGET_019_Rx:0, DET_SUPER_RES_TARGET_020_Rx:0]}, required-interface=Pi_SG_Fusion_Detections_017_020_AL
      Rp_SG_Fusion_Detections_021_024_AL: nonqueued-receiver-com-spec{data-element=Vdp_SG_Fusion_Detections_021_024_AL, init-value=fields=[DET_AZIMUTH_021_Rx:0, DET_AZIMUTH_022_Rx:0, DET_AZIMUTH_023_Rx:0, DET_AZIMUTH_024_Rx:0, DET_AZIMUTH_ERR_021_Rx:0, DET_AZIMUTH_ERR_022_Rx:0, DET_AZIMUTH_ERR_023_Rx:0, DET_AZIMUTH_ERR_024_Rx:0, DET_BELOW_RAIN_THOLD_021_Rx:0, DET_BELOW_RAIN_THOLD_022_Rx:0, DET_BELOW_RAIN_THOLD_023_Rx:0, DET_BELOW_RAIN_THOLD_024_Rx:0, DET_BI_STATIC_FLAG_021_Rx:0, DET_BI_STATIC_FLAG_022_Rx:0, DET_BI_STATIC_FLAG_023_Rx:0, DET_BI_STATIC_FLAG_024_Rx:0, DET_CONFD_AZIMUTH_021_Rx:0, DET_CONFD_AZIMUTH_022_Rx:0, DET_CONFD_AZIMUTH_023_Rx:0, DET_CONFD_AZIMUTH_024_Rx:0, DET_CONFD_ELEVATION_021_Rx:0, DET_CONFD_ELEVATION_022_Rx:0, DET_CONFD_ELEVATION_023_Rx:0, DET_CONFD_ELEVATION_024_Rx:0, DET_ELEVATION_021_Rx:0, DET_ELEVATION_022_Rx:0, DET_ELEVATION_023_Rx:0, DET_ELEVATION_024_Rx:0, DET_ELEVATION_ERR_021_Rx:0, DET_ELEVATION_ERR_022_Rx:0, DET_ELEVATION_ERR_023_Rx:0, DET_ELEVATION_ERR_024_Rx:0, DET_EXISTENCE_PROB_021_Rx:0, DET_EXISTENCE_PROB_022_Rx:0, DET_EXISTENCE_PROB_023_Rx:0, DET_EXISTENCE_PROB_024_Rx:0, DET_HVC_FLAG_021_Rx:0, DET_HVC_FLAG_022_Rx:0, DET_HVC_FLAG_023_Rx:0, DET_HVC_FLAG_024_Rx:0, DET_IDM_021_Rx:0, DET_IDM_022_Rx:0, DET_IDM_023_Rx:0, DET_IDM_024_Rx:0, DET_MH_CRC16_021_024_Rx:0, DET_MH_CYCLE_COUNTER_021_024_Rx:0, DET_MH_SCAN_INDEX_4LSB_021_024_Rx:0, DET_MTD_021_Rx:0, DET_MTD_022_Rx:0, DET_MTD_023_Rx:0, DET_MTD_024_Rx:0, DET_PROB_1STAZHYPO_021_Rx:0, DET_PROB_1STAZHYPO_022_Rx:0, DET_PROB_1STAZHYPO_023_Rx:0, DET_PROB_1STAZHYPO_024_Rx:0, DET_RANGE_021_Rx:0, DET_RANGE_022_Rx:0, DET_RANGE_023_Rx:0, DET_RANGE_024_Rx:0, DET_RANGE_ERR_021_Rx:0, DET_RANGE_ERR_022_Rx:0, DET_RANGE_ERR_023_Rx:0, DET_RANGE_ERR_024_Rx:0, DET_RANGE_VELOCITY_021_Rx:0, DET_RANGE_VELOCITY_022_Rx:0, DET_RANGE_VELOCITY_023_Rx:0, DET_RANGE_VELOCITY_024_Rx:0, DET_RANGE_VELOCITY_ERR_021_Rx:0, DET_RANGE_VELOCITY_ERR_022_Rx:0, DET_RANGE_VELOCITY_ERR_023_Rx:0, DET_RANGE_VELOCITY_ERR_024_Rx:0, DET_RCS_021_Rx:0, DET_RCS_022_Rx:0, DET_RCS_023_Rx:0, DET_RCS_024_Rx:0, DET_SNR_021_Rx:0, DET_SNR_022_Rx:0, DET_SNR_023_Rx:0, DET_SNR_024_Rx:0, DET_SUPER_RES_TARGET_021_Rx:0, DET_SUPER_RES_TARGET_022_Rx:0, DET_SUPER_RES_TARGET_023_Rx:0, DET_SUPER_RES_TARGET_024_Rx:0]}, required-interface=Pi_SG_Fusion_Detections_021_024_AL
      Rp_SG_Fusion_Detections_025_028_AL: nonqueued-receiver-com-spec{data-element=Vdp_SG_Fusion_Detections_025_028_AL, init-value=fields=[DET_AZIMUTH_025_Rx:0, DET_AZIMUTH_026_Rx:0, DET_AZIMUTH_027_Rx:0, DET_AZIMUTH_028_Rx:0, DET_AZIMUTH_ERR_025_Rx:0, DET_AZIMUTH_ERR_026_Rx:0, DET_AZIMUTH_ERR_027_Rx:0, DET_AZIMUTH_ERR_028_Rx:0, DET_BELOW_RAIN_THOLD_025_Rx:0, DET_BELOW_RAIN_THOLD_026_Rx:0, DET_BELOW_RAIN_THOLD_027_Rx:0, DET_BELOW_RAIN_THOLD_028_Rx:0, DET_BI_STATIC_FLAG_025_Rx:0, DET_BI_STATIC_FLAG_026_Rx:0, DET_BI_STATIC_FLAG_027_Rx:0, DET_BI_STATIC_FLAG_028_Rx:0, DET_CONFD_AZIMUTH_025_Rx:0, DET_CONFD_AZIMUTH_026_Rx:0, DET_CONFD_AZIMUTH_027_Rx:0, DET_CONFD_AZIMUTH_028_Rx:0, DET_CONFD_ELEVATION_025_Rx:0, DET_CONFD_ELEVATION_026_Rx:0, DET_CONFD_ELEVATION_027_Rx:0, DET_CONFD_ELEVATION_028_Rx:0, DET_ELEVATION_025_Rx:0, DET_ELEVATION_026_Rx:0, DET_ELEVATION_027_Rx:0, DET_ELEVATION_028_Rx:0, DET_ELEVATION_ERR_025_Rx:0, DET_ELEVATION_ERR_026_Rx:0, DET_ELEVATION_ERR_027_Rx:0, DET_ELEVATION_ERR_028_Rx:0, DET_EXISTENCE_PROB_025_Rx:0, DET_EXISTENCE_PROB_026_Rx:0, DET_EXISTENCE_PROB_027_Rx:0, DET_EXISTENCE_PROB_028_Rx:0, DET_HVC_FLAG_025_Rx:0, DET_HVC_FLAG_026_Rx:0, DET_HVC_FLAG_027_Rx:0, DET_HVC_FLAG_028_Rx:0, DET_IDM_025_Rx:0, DET_IDM_026_Rx:0, DET_IDM_027_Rx:0, DET_IDM_028_Rx:0, DET_MH_CRC16_025_028_Rx:0, DET_MH_CYCLE_COUNTER_025_028_Rx:0, DET_MH_SCAN_INDEX_4LSB_025_028_Rx:0, DET_MTD_025_Rx:0, DET_MTD_026_Rx:0, DET_MTD_027_Rx:0, DET_MTD_028_Rx:0, DET_PROB_1STAZHYPO_025_Rx:0, DET_PROB_1STAZHYPO_026_Rx:0, DET_PROB_1STAZHYPO_027_Rx:0, DET_PROB_1STAZHYPO_028_Rx:0, DET_RANGE_025_Rx:0, DET_RANGE_026_Rx:0, DET_RANGE_027_Rx:0, DET_RANGE_028_Rx:0, DET_RANGE_ERR_025_Rx:0, DET_RANGE_ERR_026_Rx:0, DET_RANGE_ERR_027_Rx:0, DET_RANGE_ERR_028_Rx:0, DET_RANGE_VELOCITY_025_Rx:0, DET_RANGE_VELOCITY_026_Rx:0, DET_RANGE_VELOCITY_027_Rx:0, DET_RANGE_VELOCITY_028_Rx:0, DET_RANGE_VELOCITY_ERR_025_Rx:0, DET_RANGE_VELOCITY_ERR_026_Rx:0, DET_RANGE_VELOCITY_ERR_027_Rx:0, DET_RANGE_VELOCITY_ERR_028_Rx:0, DET_RCS_025_Rx:0, DET_RCS_026_Rx:0, DET_RCS_027_Rx:0, DET_RCS_028_Rx:0, DET_SNR_025_Rx:0, DET_SNR_026_Rx:0, DET_SNR_027_Rx:0, DET_SNR_028_Rx:0, DET_SUPER_RES_TARGET_025_Rx:0, DET_SUPER_RES_TARGET_026_Rx:0, DET_SUPER_RES_TARGET_027_Rx:0, DET_SUPER_RES_TARGET_028_Rx:0]}, required-interface=Pi_SG_Fusion_Detections_025_028_AL
      Rp_SG_Fusion_Detections_029_032_AL: nonqueued-receiver-com-spec{data-element=Vdp_SG_Fusion_Detections_029_032_AL, init-value=fields=[DET_AZIMUTH_029_Rx:0, DET_AZIMUTH_030_Rx:0, DET_AZIMUTH_031_Rx:0, DET_AZIMUTH_032_Rx:0, DET_AZIMUTH_ERR_029_Rx:0, DET_AZIMUTH_ERR_030_Rx:0, DET_AZIMUTH_ERR_031_Rx:0, DET_AZIMUTH_ERR_032_Rx:0, DET_BELOW_RAIN_THOLD_029_Rx:0, DET_BELOW_RAIN_THOLD_030_Rx:0, DET_BELOW_RAIN_THOLD_031_Rx:0, DET_BELOW_RAIN_THOLD_032_Rx:0, DET_BI_STATIC_FLAG_029_Rx:0, DET_BI_STATIC_FLAG_030_Rx:0, DET_BI_STATIC_FLAG_031_Rx:0, DET_BI_STATIC_FLAG_032_Rx:0, DET_CONFD_AZIMUTH_029_Rx:0, DET_CONFD_AZIMUTH_030_Rx:0, DET_CONFD_AZIMUTH_031_Rx:0, DET_CONFD_AZIMUTH_032_Rx:0, DET_CONFD_ELEVATION_029_Rx:0, DET_CONFD_ELEVATION_030_Rx:0, DET_CONFD_ELEVATION_031_Rx:0, DET_CONFD_ELEVATION_032_Rx:0, DET_ELEVATION_029_Rx:0, DET_ELEVATION_030_Rx:0, DET_ELEVATION_031_Rx:0, DET_ELEVATION_032_Rx:0, DET_ELEVATION_ERR_029_Rx:0, DET_ELEVATION_ERR_030_Rx:0, DET_ELEVATION_ERR_031_Rx:0, DET_ELEVATION_ERR_032_Rx:0, DET_EXISTENCE_PROB_029_Rx:0, DET_EXISTENCE_PROB_030_Rx:0, DET_EXISTENCE_PROB_031_Rx:0, DET_EXISTENCE_PROB_032_Rx:0, DET_HVC_FLAG_029_Rx:0, DET_HVC_FLAG_030_Rx:0, DET_HVC_FLAG_031_Rx:0, DET_HVC_FLAG_032_Rx:0, DET_IDM_029_Rx:0, DET_IDM_030_Rx:0, DET_IDM_031_Rx:0, DET_IDM_032_Rx:0, DET_MH_CRC16_029_032_Rx:0, DET_MH_CYCLE_COUNTER_029_032_Rx:0, DET_MH_SCAN_INDEX_4LSB_029_032_Rx:0, DET_MTD_029_Rx:0, DET_MTD_030_Rx:0, DET_MTD_031_Rx:0, DET_MTD_032_Rx:0, DET_PROB_1STAZHYPO_029_Rx:0, DET_PROB_1STAZHYPO_030_Rx:0, DET_PROB_1STAZHYPO_031_Rx:0, DET_PROB_1STAZHYPO_032_Rx:0, DET_RANGE_029_Rx:0, DET_RANGE_030_Rx:0, DET_RANGE_031_Rx:0, DET_RANGE_032_Rx:0, DET_RANGE_ERR_029_Rx:0, DET_RANGE_ERR_030_Rx:0, DET_RANGE_ERR_031_Rx:0, DET_RANGE_ERR_032_Rx:0, DET_RANGE_VELOCITY_029_Rx:0, DET_RANGE_VELOCITY_030_Rx:0, DET_RANGE_VELOCITY_031_Rx:0, DET_RANGE_VELOCITY_032_Rx:0, DET_RANGE_VELOCITY_ERR_029_Rx:0, DET_RANGE_VELOCITY_ERR_030_Rx:0, DET_RANGE_VELOCITY_ERR_031_Rx:0, DET_RANGE_VELOCITY_ERR_032_Rx:0, DET_RCS_029_Rx:0, DET_RCS_030_Rx:0, DET_RCS_031_Rx:0, DET_RCS_032_Rx:0, DET_SNR_029_Rx:0, DET_SNR_030_Rx:0, DET_SNR_031_Rx:0, DET_SNR_032_Rx:0, DET_SUPER_RES_TARGET_029_Rx:0, DET_SUPER_RES_TARGET_030_Rx:0, DET_SUPER_RES_TARGET_031_Rx:0, DET_SUPER_RES_TARGET_032_Rx:0]}, required-interface=Pi_SG_Fusion_Detections_029_032_AL
      Rp_SG_Fusion_Detections_033_036_AL: nonqueued-receiver-com-spec{data-element=Vdp_SG_Fusion_Detections_033_036_AL, init-value=fields=[DET_AZIMUTH_033_Rx:0, DET_AZIMUTH_034_Rx:0, DET_AZIMUTH_035_Rx:0, DET_AZIMUTH_036_Rx:0, DET_AZIMUTH_ERR_033_Rx:0, DET_AZIMUTH_ERR_034_Rx:0, DET_AZIMUTH_ERR_035_Rx:0, DET_AZIMUTH_ERR_036_Rx:0, DET_BELOW_RAIN_THOLD_033_Rx:0, DET_BELOW_RAIN_THOLD_034_Rx:0, DET_BELOW_RAIN_THOLD_035_Rx:0, DET_BELOW_RAIN_THOLD_036_Rx:0, DET_BI_STATIC_FLAG_033_Rx:0, DET_BI_STATIC_FLAG_034_Rx:0, DET_BI_STATIC_FLAG_035_Rx:0, DET_BI_STATIC_FLAG_036_Rx:0, DET_CONFD_AZIMUTH_033_Rx:0, DET_CONFD_AZIMUTH_034_Rx:0, DET_CONFD_AZIMUTH_035_Rx:0, DET_CONFD_AZIMUTH_036_Rx:0, DET_CONFD_ELEVATION_033_Rx:0, DET_CONFD_ELEVATION_034_Rx:0, DET_CONFD_ELEVATION_035_Rx:0, DET_CONFD_ELEVATION_036_Rx:0, DET_ELEVATION_033_Rx:0, DET_ELEVATION_034_Rx:0, DET_ELEVATION_035_Rx:0, DET_ELEVATION_036_Rx:0, DET_ELEVATION_ERR_033_Rx:0, DET_ELEVATION_ERR_034_Rx:0, DET_ELEVATION_ERR_035_Rx:0, DET_ELEVATION_ERR_036_Rx:0, DET_EXISTENCE_PROB_033_Rx:0, DET_EXISTENCE_PROB_034_Rx:0, DET_EXISTENCE_PROB_035_Rx:0, DET_EXISTENCE_PROB_036_Rx:0, DET_HVC_FLAG_033_Rx:0, DET_HVC_FLAG_034_Rx:0, DET_HVC_FLAG_035_Rx:0, DET_HVC_FLAG_036_Rx:0, DET_IDM_033_Rx:0, DET_IDM_034_Rx:0, DET_IDM_035_Rx:0, DET_IDM_036_Rx:0, DET_MH_CRC16_033_036_Rx:0, DET_MH_CYCLE_COUNTER_033_036_Rx:0, DET_MH_SCAN_INDEX_4LSB_033_036_Rx:0, DET_MTD_033_Rx:0, DET_MTD_034_Rx:0, DET_MTD_035_Rx:0, DET_MTD_036_Rx:0, DET_PROB_1STAZHYPO_033_Rx:0, DET_PROB_1STAZHYPO_034_Rx:0, DET_PROB_1STAZHYPO_035_Rx:0, DET_PROB_1STAZHYPO_036_Rx:0, DET_RANGE_033_Rx:0, DET_RANGE_034_Rx:0, DET_RANGE_035_Rx:0, DET_RANGE_036_Rx:0, DET_RANGE_ERR_033_Rx:0, DET_RANGE_ERR_034_Rx:0, DET_RANGE_ERR_035_Rx:0, DET_RANGE_ERR_036_Rx:0, DET_RANGE_VELOCITY_033_Rx:0, DET_RANGE_VELOCITY_034_Rx:0, DET_RANGE_VELOCITY_035_Rx:0, DET_RANGE_VELOCITY_036_Rx:0, DET_RANGE_VELOCITY_ERR_033_Rx:0, DET_RANGE_VELOCITY_ERR_034_Rx:0, DET_RANGE_VELOCITY_ERR_035_Rx:0, DET_RANGE_VELOCITY_ERR_036_Rx:0, DET_RCS_033_Rx:0, DET_RCS_034_Rx:0, DET_RCS_035_Rx:0, DET_RCS_036_Rx:0, DET_SNR_033_Rx:0, DET_SNR_034_Rx:0, DET_SNR_035_Rx:0, DET_SNR_036_Rx:0, DET_SUPER_RES_TARGET_033_Rx:0, DET_SUPER_RES_TARGET_034_Rx:0, DET_SUPER_RES_TARGET_035_Rx:0, DET_SUPER_RES_TARGET_036_Rx:0]}, required-interface=Pi_SG_Fusion_Detections_033_036_AL
      Rp_SG_Fusion_Detections_037_040_AL: nonqueued-receiver-com-spec{data-element=Vdp_SG_Fusion_Detections_037_040_AL, init-value=fields=[DET_AZIMUTH_037_Rx:0, DET_AZIMUTH_038_Rx:0, DET_AZIMUTH_039_Rx:0, DET_AZIMUTH_040_Rx:0, DET_AZIMUTH_ERR_037_Rx:0, DET_AZIMUTH_ERR_038_Rx:0, DET_AZIMUTH_ERR_039_Rx:0, DET_AZIMUTH_ERR_040_Rx:0, DET_BELOW_RAIN_THOLD_037_Rx:0, DET_BELOW_RAIN_THOLD_038_Rx:0, DET_BELOW_RAIN_THOLD_039_Rx:0, DET_BELOW_RAIN_THOLD_040_Rx:0, DET_BI_STATIC_FLAG_037_Rx:0, DET_BI_STATIC_FLAG_038_Rx:0, DET_BI_STATIC_FLAG_039_Rx:0, DET_BI_STATIC_FLAG_040_Rx:0, DET_CONFD_AZIMUTH_037_Rx:0, DET_CONFD_AZIMUTH_038_Rx:0, DET_CONFD_AZIMUTH_039_Rx:0, DET_CONFD_AZIMUTH_040_Rx:0, DET_CONFD_ELEVATION_037_Rx:0, DET_CONFD_ELEVATION_038_Rx:0, DET_CONFD_ELEVATION_039_Rx:0, DET_CONFD_ELEVATION_040_Rx:0, DET_ELEVATION_037_Rx:0, DET_ELEVATION_038_Rx:0, DET_ELEVATION_039_Rx:0, DET_ELEVATION_040_Rx:0, DET_ELEVATION_ERR_037_Rx:0, DET_ELEVATION_ERR_038_Rx:0, DET_ELEVATION_ERR_039_Rx:0, DET_ELEVATION_ERR_040_Rx:0, DET_EXISTENCE_PROB_037_Rx:0, DET_EXISTENCE_PROB_038_Rx:0, DET_EXISTENCE_PROB_039_Rx:0, DET_EXISTENCE_PROB_040_Rx:0, DET_HVC_FLAG_037_Rx:0, DET_HVC_FLAG_038_Rx:0, DET_HVC_FLAG_039_Rx:0, DET_HVC_FLAG_040_Rx:0, DET_IDM_037_Rx:0, DET_IDM_038_Rx:0, DET_IDM_039_Rx:0, DET_IDM_040_Rx:0, DET_MH_CRC16_037_040_Rx:0, DET_MH_CYCLE_COUNTER_037_040_Rx:0, DET_MH_SCAN_INDEX_4LSB_037_040_Rx:0, DET_MTD_037_Rx:0, DET_MTD_038_Rx:0, DET_MTD_039_Rx:0, DET_MTD_040_Rx:0, DET_PROB_1STAZHYPO_037_Rx:0, DET_PROB_1STAZHYPO_038_Rx:0, DET_PROB_1STAZHYPO_039_Rx:0, DET_PROB_1STAZHYPO_040_Rx:0, DET_RANGE_037_Rx:0, DET_RANGE_038_Rx:0, DET_RANGE_039_Rx:0, DET_RANGE_040_Rx:0, DET_RANGE_ERR_037_Rx:0, DET_RANGE_ERR_038_Rx:0, DET_RANGE_ERR_039_Rx:0, DET_RANGE_ERR_040_Rx:0, DET_RANGE_VELOCITY_037_Rx:0, DET_RANGE_VELOCITY_038_Rx:0, DET_RANGE_VELOCITY_039_Rx:0, DET_RANGE_VELOCITY_040_Rx:0, DET_RANGE_VELOCITY_ERR_037_Rx:0, DET_RANGE_VELOCITY_ERR_038_Rx:0, DET_RANGE_VELOCITY_ERR_039_Rx:0, DET_RANGE_VELOCITY_ERR_040_Rx:0, DET_RCS_037_Rx:0, DET_RCS_038_Rx:0, DET_RCS_039_Rx:0, DET_RCS_040_Rx:0, DET_SNR_037_Rx:0, DET_SNR_038_Rx:0, DET_SNR_039_Rx:0, DET_SNR_040_Rx:0, DET_SUPER_RES_TARGET_037_Rx:0, DET_SUPER_RES_TARGET_038_Rx:0, DET_SUPER_RES_TARGET_039_Rx:0, DET_SUPER_RES_TARGET_040_Rx:0]}, required-interface=Pi_SG_Fusion_Detections_037_040_AL
      Rp_SG_Fusion_Detections_041_044_AL: nonqueued-receiver-com-spec{data-element=Vdp_SG_Fusion_Detections_041_044_AL, init-value=fields=[DET_AZIMUTH_041_Rx:0, DET_AZIMUTH_042_Rx:0, DET_AZIMUTH_043_Rx:0, DET_AZIMUTH_044_Rx:0, DET_AZIMUTH_ERR_041_Rx:0, DET_AZIMUTH_ERR_042_Rx:0, DET_AZIMUTH_ERR_043_Rx:0, DET_AZIMUTH_ERR_044_Rx:0, DET_BELOW_RAIN_THOLD_041_Rx:0, DET_BELOW_RAIN_THOLD_042_Rx:0, DET_BELOW_RAIN_THOLD_043_Rx:0, DET_BELOW_RAIN_THOLD_044_Rx:0, DET_BI_STATIC_FLAG_041_Rx:0, DET_BI_STATIC_FLAG_042_Rx:0, DET_BI_STATIC_FLAG_043_Rx:0, DET_BI_STATIC_FLAG_044_Rx:0, DET_CONFD_AZIMUTH_041_Rx:0, DET_CONFD_AZIMUTH_042_Rx:0, DET_CONFD_AZIMUTH_043_Rx:0, DET_CONFD_AZIMUTH_044_Rx:0, DET_CONFD_ELEVATION_041_Rx:0, DET_CONFD_ELEVATION_042_Rx:0, DET_CONFD_ELEVATION_043_Rx:0, DET_CONFD_ELEVATION_044_Rx:0, DET_ELEVATION_041_Rx:0, DET_ELEVATION_042_Rx:0, DET_ELEVATION_043_Rx:0, DET_ELEVATION_044_Rx:0, DET_ELEVATION_ERR_041_Rx:0, DET_ELEVATION_ERR_042_Rx:0, DET_ELEVATION_ERR_043_Rx:0, DET_ELEVATION_ERR_044_Rx:0, DET_EXISTENCE_PROB_041_Rx:0, DET_EXISTENCE_PROB_042_Rx:0, DET_EXISTENCE_PROB_043_Rx:0, DET_EXISTENCE_PROB_044_Rx:0, DET_HVC_FLAG_041_Rx:0, DET_HVC_FLAG_042_Rx:0, DET_HVC_FLAG_043_Rx:0, DET_HVC_FLAG_044_Rx:0, DET_IDM_041_Rx:0, DET_IDM_042_Rx:0, DET_IDM_043_Rx:0, DET_IDM_044_Rx:0, DET_MH_CRC16_041_044_Rx:0, DET_MH_CYCLE_COUNTER_041_044_Rx:0, DET_MH_SCAN_INDEX_4LSB_041_044_Rx:0, DET_MTD_041_Rx:0, DET_MTD_042_Rx:0, DET_MTD_043_Rx:0, DET_MTD_044_Rx:0, DET_PROB_1STAZHYPO_041_Rx:0, DET_PROB_1STAZHYPO_042_Rx:0, DET_PROB_1STAZHYPO_043_Rx:0, DET_PROB_1STAZHYPO_044_Rx:0, DET_RANGE_041_Rx:0, DET_RANGE_042_Rx:0, DET_RANGE_043_Rx:0, DET_RANGE_044_Rx:0, DET_RANGE_ERR_041_Rx:0, DET_RANGE_ERR_042_Rx:0, DET_RANGE_ERR_043_Rx:0, DET_RANGE_ERR_044_Rx:0, DET_RANGE_VELOCITY_041_Rx:0, DET_RANGE_VELOCITY_042_Rx:0, DET_RANGE_VELOCITY_043_Rx:0, DET_RANGE_VELOCITY_044_Rx:0, DET_RANGE_VELOCITY_ERR_041_Rx:0, DET_RANGE_VELOCITY_ERR_042_Rx:0, DET_RANGE_VELOCITY_ERR_043_Rx:0, DET_RANGE_VELOCITY_ERR_044_Rx:0, DET_RCS_041_Rx:0, DET_RCS_042_Rx:0, DET_RCS_043_Rx:0, DET_RCS_044_Rx:0, DET_SNR_041_Rx:0, DET_SNR_042_Rx:0, DET_SNR_043_Rx:0, DET_SNR_044_Rx:0, DET_SUPER_RES_TARGET_041_Rx:0, DET_SUPER_RES_TARGET_042_Rx:0, DET_SUPER_RES_TARGET_043_Rx:0, DET_SUPER_RES_TARGET_044_Rx:0]}, required-interface=Pi_SG_Fusion_Detections_041_044_AL
      Rp_SG_Fusion_Detections_045_048_AL: nonqueued-receiver-com-spec{data-element=Vdp_SG_Fusion_Detections_045_048_AL, init-value=fields=[DET_AZIMUTH_045_Rx:0, DET_AZIMUTH_046_Rx:0, DET_AZIMUTH_047_Rx:0, DET_AZIMUTH_048_Rx:0, DET_AZIMUTH_ERR_045_Rx:0, DET_AZIMUTH_ERR_046_Rx:0, DET_AZIMUTH_ERR_047_Rx:0, DET_AZIMUTH_ERR_048_Rx:0, DET_BELOW_RAIN_THOLD_045_Rx:0, DET_BELOW_RAIN_THOLD_046_Rx:0, DET_BELOW_RAIN_THOLD_047_Rx:0, DET_BELOW_RAIN_THOLD_048_Rx:0, DET_BI_STATIC_FLAG_045_Rx:0, DET_BI_STATIC_FLAG_046_Rx:0, DET_BI_STATIC_FLAG_047_Rx:0, DET_BI_STATIC_FLAG_048_Rx:0, DET_CONFD_AZIMUTH_045_Rx:0, DET_CONFD_AZIMUTH_046_Rx:0, DET_CONFD_AZIMUTH_047_Rx:0, DET_CONFD_AZIMUTH_048_Rx:0, DET_CONFD_ELEVATION_045_Rx:0, DET_CONFD_ELEVATION_046_Rx:0, DET_CONFD_ELEVATION_047_Rx:0, DET_CONFD_ELEVATION_048_Rx:0, DET_ELEVATION_045_Rx:0, DET_ELEVATION_046_Rx:0, DET_ELEVATION_047_Rx:0, DET_ELEVATION_048_Rx:0, DET_ELEVATION_ERR_045_Rx:0, DET_ELEVATION_ERR_046_Rx:0, DET_ELEVATION_ERR_047_Rx:0, DET_ELEVATION_ERR_048_Rx:0, DET_EXISTENCE_PROB_045_Rx:0, DET_EXISTENCE_PROB_046_Rx:0, DET_EXISTENCE_PROB_047_Rx:0, DET_EXISTENCE_PROB_048_Rx:0, DET_HVC_FLAG_045_Rx:0, DET_HVC_FLAG_046_Rx:0, DET_HVC_FLAG_047_Rx:0, DET_HVC_FLAG_048_Rx:0, DET_IDM_045_Rx:0, DET_IDM_046_Rx:0, DET_IDM_047_Rx:0, DET_IDM_048_Rx:0, DET_MH_CRC16_045_048_Rx:0, DET_MH_CYCLE_COUNTER_045_048_Rx:0, DET_MH_SCAN_INDEX_4LSB_045_048_Rx:0, DET_MTD_045_Rx:0, DET_MTD_046_Rx:0, DET_MTD_047_Rx:0, DET_MTD_048_Rx:0, DET_PROB_1STAZHYPO_045_Rx:0, DET_PROB_1STAZHYPO_046_Rx:0, DET_PROB_1STAZHYPO_047_Rx:0, DET_PROB_1STAZHYPO_048_Rx:0, DET_RANGE_045_Rx:0, DET_RANGE_046_Rx:0, DET_RANGE_047_Rx:0, DET_RANGE_048_Rx:0, DET_RANGE_ERR_045_Rx:0, DET_RANGE_ERR_046_Rx:0, DET_RANGE_ERR_047_Rx:0, DET_RANGE_ERR_048_Rx:0, DET_RANGE_VELOCITY_045_Rx:0, DET_RANGE_VELOCITY_046_Rx:0, DET_RANGE_VELOCITY_047_Rx:0, DET_RANGE_VELOCITY_048_Rx:0, DET_RANGE_VELOCITY_ERR_045_Rx:0, DET_RANGE_VELOCITY_ERR_046_Rx:0, DET_RANGE_VELOCITY_ERR_047_Rx:0, DET_RANGE_VELOCITY_ERR_048_Rx:0, DET_RCS_045_Rx:0, DET_RCS_046_Rx:0, DET_RCS_047_Rx:0, DET_RCS_048_Rx:0, DET_SNR_045_Rx:0, DET_SNR_046_Rx:0, DET_SNR_047_Rx:0, DET_SNR_048_Rx:0, DET_SUPER_RES_TARGET_045_Rx:0, DET_SUPER_RES_TARGET_046_Rx:0, DET_SUPER_RES_TARGET_047_Rx:0, DET_SUPER_RES_TARGET_048_Rx:0]}, required-interface=Pi_SG_Fusion_Detections_045_048_AL
      Rp_SG_Fusion_Detections_049_052_AL: nonqueued-receiver-com-spec{data-element=Vdp_SG_Fusion_Detections_049_052_AL, init-value=fields=[DET_AZIMUTH_049_Rx:0, DET_AZIMUTH_050_Rx:0, DET_AZIMUTH_051_Rx:0, DET_AZIMUTH_052_Rx:0, DET_AZIMUTH_ERR_049_Rx:0, DET_AZIMUTH_ERR_050_Rx:0, DET_AZIMUTH_ERR_051_Rx:0, DET_AZIMUTH_ERR_052_Rx:0, DET_BELOW_RAIN_THOLD_049_Rx:0, DET_BELOW_RAIN_THOLD_050_Rx:0, DET_BELOW_RAIN_THOLD_051_Rx:0, DET_BELOW_RAIN_THOLD_052_Rx:0, DET_BI_STATIC_FLAG_049_Rx:0, DET_BI_STATIC_FLAG_050_Rx:0, DET_BI_STATIC_FLAG_051_Rx:0, DET_BI_STATIC_FLAG_052_Rx:0, DET_CONFD_AZIMUTH_049_Rx:0, DET_CONFD_AZIMUTH_050_Rx:0, DET_CONFD_AZIMUTH_051_Rx:0, DET_CONFD_AZIMUTH_052_Rx:0, DET_CONFD_ELEVATION_049_Rx:0, DET_CONFD_ELEVATION_050_Rx:0, DET_CONFD_ELEVATION_051_Rx:0, DET_CONFD_ELEVATION_052_Rx:0, DET_ELEVATION_049_Rx:0, DET_ELEVATION_050_Rx:0, DET_ELEVATION_051_Rx:0, DET_ELEVATION_052_Rx:0, DET_ELEVATION_ERR_049_Rx:0, DET_ELEVATION_ERR_050_Rx:0, DET_ELEVATION_ERR_051_Rx:0, DET_ELEVATION_ERR_052_Rx:0, DET_EXISTENCE_PROB_049_Rx:0, DET_EXISTENCE_PROB_050_Rx:0, DET_EXISTENCE_PROB_051_Rx:0, DET_EXISTENCE_PROB_052_Rx:0, DET_HVC_FLAG_049_Rx:0, DET_HVC_FLAG_050_Rx:0, DET_HVC_FLAG_051_Rx:0, DET_HVC_FLAG_052_Rx:0, DET_IDM_049_Rx:0, DET_IDM_050_Rx:0, DET_IDM_051_Rx:0, DET_IDM_052_Rx:0, DET_MH_CRC16_049_052_Rx:0, DET_MH_CYCLE_COUNTER_049_052_Rx:0, DET_MH_SCAN_INDEX_4LSB_049_052_Rx:0, DET_MTD_049_Rx:0, DET_MTD_050_Rx:0, DET_MTD_051_Rx:0, DET_MTD_052_Rx:0, DET_PROB_1STAZHYPO_049_Rx:0, DET_PROB_1STAZHYPO_050_Rx:0, DET_PROB_1STAZHYPO_051_Rx:0, DET_PROB_1STAZHYPO_052_Rx:0, DET_RANGE_049_Rx:0, DET_RANGE_050_Rx:0, DET_RANGE_051_Rx:0, DET_RANGE_052_Rx:0, DET_RANGE_ERR_049_Rx:0, DET_RANGE_ERR_050_Rx:0, DET_RANGE_ERR_051_Rx:0, DET_RANGE_ERR_052_Rx:0, DET_RANGE_VELOCITY_049_Rx:0, DET_RANGE_VELOCITY_050_Rx:0, DET_RANGE_VELOCITY_051_Rx:0, DET_RANGE_VELOCITY_052_Rx:0, DET_RANGE_VELOCITY_ERR_049_Rx:0, DET_RANGE_VELOCITY_ERR_050_Rx:0, DET_RANGE_VELOCITY_ERR_051_Rx:0, DET_RANGE_VELOCITY_ERR_052_Rx:0, DET_RCS_049_Rx:0, DET_RCS_050_Rx:0, DET_RCS_051_Rx:0, DET_RCS_052_Rx:0, DET_SNR_049_Rx:0, DET_SNR_050_Rx:0, DET_SNR_051_Rx:0, DET_SNR_052_Rx:0, DET_SUPER_RES_TARGET_049_Rx:0, DET_SUPER_RES_TARGET_050_Rx:0, DET_SUPER_RES_TARGET_051_Rx:0, DET_SUPER_RES_TARGET_052_Rx:0]}, required-interface=Pi_SG_Fusion_Detections_049_052_AL
      Rp_SG_Fusion_Detections_053_056_AL: nonqueued-receiver-com-spec{data-element=Vdp_SG_Fusion_Detections_053_056_AL, init-value=fields=[DET_AZIMUTH_053_Rx:0, DET_AZIMUTH_054_Rx:0, DET_AZIMUTH_055_Rx:0, DET_AZIMUTH_056_Rx:0, DET_AZIMUTH_ERR_053_Rx:0, DET_AZIMUTH_ERR_054_Rx:0, DET_AZIMUTH_ERR_055_Rx:0, DET_AZIMUTH_ERR_056_Rx:0, DET_BELOW_RAIN_THOLD_053_Rx:0, DET_BELOW_RAIN_THOLD_054_Rx:0, DET_BELOW_RAIN_THOLD_055_Rx:0, DET_BELOW_RAIN_THOLD_056_Rx:0, DET_BI_STATIC_FLAG_053_Rx:0, DET_BI_STATIC_FLAG_054_Rx:0, DET_BI_STATIC_FLAG_055_Rx:0, DET_BI_STATIC_FLAG_056_Rx:0, DET_CONFD_AZIMUTH_053_Rx:0, DET_CONFD_AZIMUTH_054_Rx:0, DET_CONFD_AZIMUTH_055_Rx:0, DET_CONFD_AZIMUTH_056_Rx:0, DET_CONFD_ELEVATION_053_Rx:0, DET_CONFD_ELEVATION_054_Rx:0, DET_CONFD_ELEVATION_055_Rx:0, DET_CONFD_ELEVATION_056_Rx:0, DET_ELEVATION_053_Rx:0, DET_ELEVATION_054_Rx:0, DET_ELEVATION_055_Rx:0, DET_ELEVATION_056_Rx:0, DET_ELEVATION_ERR_053_Rx:0, DET_ELEVATION_ERR_054_Rx:0, DET_ELEVATION_ERR_055_Rx:0, DET_ELEVATION_ERR_056_Rx:0, DET_EXISTENCE_PROB_053_Rx:0, DET_EXISTENCE_PROB_054_Rx:0, DET_EXISTENCE_PROB_055_Rx:0, DET_EXISTENCE_PROB_056_Rx:0, DET_HVC_FLAG_053_Rx:0, DET_HVC_FLAG_054_Rx:0, DET_HVC_FLAG_055_Rx:0, DET_HVC_FLAG_056_Rx:0, DET_IDM_053_Rx:0, DET_IDM_054_Rx:0, DET_IDM_055_Rx:0, DET_IDM_056_Rx:0, DET_MH_CRC16_053_056_Rx:0, DET_MH_CYCLE_COUNTER_053_056_Rx:0, DET_MH_SCAN_INDEX_4LSB_053_056_Rx:0, DET_MTD_053_Rx:0, DET_MTD_054_Rx:0, DET_MTD_055_Rx:0, DET_MTD_056_Rx:0, DET_PROB_1STAZHYPO_053_Rx:0, DET_PROB_1STAZHYPO_054_Rx:0, DET_PROB_1STAZHYPO_055_Rx:0, DET_PROB_1STAZHYPO_056_Rx:0, DET_RANGE_053_Rx:0, DET_RANGE_054_Rx:0, DET_RANGE_055_Rx:0, DET_RANGE_056_Rx:0, DET_RANGE_ERR_053_Rx:0, DET_RANGE_ERR_054_Rx:0, DET_RANGE_ERR_055_Rx:0, DET_RANGE_ERR_056_Rx:0, DET_RANGE_VELOCITY_053_Rx:0, DET_RANGE_VELOCITY_054_Rx:0, DET_RANGE_VELOCITY_055_Rx:0, DET_RANGE_VELOCITY_056_Rx:0, DET_RANGE_VELOCITY_ERR_053_Rx:0, DET_RANGE_VELOCITY_ERR_054_Rx:0, DET_RANGE_VELOCITY_ERR_055_Rx:0, DET_RANGE_VELOCITY_ERR_056_Rx:0, DET_RCS_053_Rx:0, DET_RCS_054_Rx:0, DET_RCS_055_Rx:0, DET_RCS_056_Rx:0, DET_SNR_053_Rx:0, DET_SNR_054_Rx:0, DET_SNR_055_Rx:0, DET_SNR_056_Rx:0, DET_SUPER_RES_TARGET_053_Rx:0, DET_SUPER_RES_TARGET_054_Rx:0, DET_SUPER_RES_TARGET_055_Rx:0, DET_SUPER_RES_TARGET_056_Rx:0]}, required-interface=Pi_SG_Fusion_Detections_053_056_AL
      Rp_SG_Fusion_Detections_057_060_AL: nonqueued-receiver-com-spec{data-element=Vdp_SG_Fusion_Detections_057_060_AL, init-value=fields=[DET_AZIMUTH_057_Rx:0, DET_AZIMUTH_058_Rx:0, DET_AZIMUTH_059_Rx:0, DET_AZIMUTH_060_Rx:0, DET_AZIMUTH_ERR_057_Rx:0, DET_AZIMUTH_ERR_058_Rx:0, DET_AZIMUTH_ERR_059_Rx:0, DET_AZIMUTH_ERR_060_Rx:0, DET_BELOW_RAIN_THOLD_057_Rx:0, DET_BELOW_RAIN_THOLD_058_Rx:0, DET_BELOW_RAIN_THOLD_059_Rx:0, DET_BELOW_RAIN_THOLD_060_Rx:0, DET_BI_STATIC_FLAG_057_Rx:0, DET_BI_STATIC_FLAG_058_Rx:0, DET_BI_STATIC_FLAG_059_Rx:0, DET_BI_STATIC_FLAG_060_Rx:0, DET_CONFD_AZIMUTH_057_Rx:0, DET_CONFD_AZIMUTH_058_Rx:0, DET_CONFD_AZIMUTH_059_Rx:0, DET_CONFD_AZIMUTH_060_Rx:0, DET_CONFD_ELEVATION_057_Rx:0, DET_CONFD_ELEVATION_058_Rx:0, DET_CONFD_ELEVATION_059_Rx:0, DET_CONFD_ELEVATION_060_Rx:0, DET_ELEVATION_057_Rx:0, DET_ELEVATION_058_Rx:0, DET_ELEVATION_059_Rx:0, DET_ELEVATION_060_Rx:0, DET_ELEVATION_ERR_057_Rx:0, DET_ELEVATION_ERR_058_Rx:0, DET_ELEVATION_ERR_059_Rx:0, DET_ELEVATION_ERR_060_Rx:0, DET_EXISTENCE_PROB_057_Rx:0, DET_EXISTENCE_PROB_058_Rx:0, DET_EXISTENCE_PROB_059_Rx:0, DET_EXISTENCE_PROB_060_Rx:0, DET_HVC_FLAG_057_Rx:0, DET_HVC_FLAG_058_Rx:0, DET_HVC_FLAG_059_Rx:0, DET_HVC_FLAG_060_Rx:0, DET_IDM_057_Rx:0, DET_IDM_058_Rx:0, DET_IDM_059_Rx:0, DET_IDM_060_Rx:0, DET_MH_CRC16_057_060_Rx:0, DET_MH_CYCLE_COUNTER_057_060_Rx:0, DET_MH_SCAN_INDEX_4LSB_057_060_Rx:0, DET_MTD_057_Rx:0, DET_MTD_058_Rx:0, DET_MTD_059_Rx:0, DET_MTD_060_Rx:0, DET_PROB_1STAZHYPO_057_Rx:0, DET_PROB_1STAZHYPO_058_Rx:0, DET_PROB_1STAZHYPO_059_Rx:0, DET_PROB_1STAZHYPO_060_Rx:0, DET_RANGE_057_Rx:0, DET_RANGE_058_Rx:0, DET_RANGE_059_Rx:0, DET_RANGE_060_Rx:0, DET_RANGE_ERR_057_Rx:0, DET_RANGE_ERR_058_Rx:0, DET_RANGE_ERR_059_Rx:0, DET_RANGE_ERR_060_Rx:0, DET_RANGE_VELOCITY_057_Rx:0, DET_RANGE_VELOCITY_058_Rx:0, DET_RANGE_VELOCITY_059_Rx:0, DET_RANGE_VELOCITY_060_Rx:0, DET_RANGE_VELOCITY_ERR_057_Rx:0, DET_RANGE_VELOCITY_ERR_058_Rx:0, DET_RANGE_VELOCITY_ERR_059_Rx:0, DET_RANGE_VELOCITY_ERR_060_Rx:0, DET_RCS_057_Rx:0, DET_RCS_058_Rx:0, DET_RCS_059_Rx:0, DET_RCS_060_Rx:0, DET_SNR_057_Rx:0, DET_SNR_058_Rx:0, DET_SNR_059_Rx:0, DET_SNR_060_Rx:0, DET_SUPER_RES_TARGET_057_Rx:0, DET_SUPER_RES_TARGET_058_Rx:0, DET_SUPER_RES_TARGET_059_Rx:0, DET_SUPER_RES_TARGET_060_Rx:0]}, required-interface=Pi_SG_Fusion_Detections_057_060_AL
      Rp_SG_Fusion_Detections_061_064_AL: nonqueued-receiver-com-spec{data-element=Vdp_SG_Fusion_Detections_061_064_AL, init-value=fields=[DET_AZIMUTH_061_Rx:0, DET_AZIMUTH_062_Rx:0, DET_AZIMUTH_063_Rx:0, DET_AZIMUTH_064_Rx:0, DET_AZIMUTH_ERR_061_Rx:0, DET_AZIMUTH_ERR_062_Rx:0, DET_AZIMUTH_ERR_063_Rx:0, DET_AZIMUTH_ERR_064_Rx:0, DET_BELOW_RAIN_THOLD_061_Rx:0, DET_BELOW_RAIN_THOLD_062_Rx:0, DET_BELOW_RAIN_THOLD_063_Rx:0, DET_BELOW_RAIN_THOLD_064_Rx:0, DET_BI_STATIC_FLAG_061_Rx:0, DET_BI_STATIC_FLAG_062_Rx:0, DET_BI_STATIC_FLAG_063_Rx:0, DET_BI_STATIC_FLAG_064_Rx:0, DET_CONFD_AZIMUTH_061_Rx:0, DET_CONFD_AZIMUTH_062_Rx:0, DET_CONFD_AZIMUTH_063_Rx:0, DET_CONFD_AZIMUTH_064_Rx:0, DET_CONFD_ELEVATION_061_Rx:0, DET_CONFD_ELEVATION_062_Rx:0, DET_CONFD_ELEVATION_063_Rx:0, DET_CONFD_ELEVATION_064_Rx:0, DET_ELEVATION_061_Rx:0, DET_ELEVATION_062_Rx:0, DET_ELEVATION_063_Rx:0, DET_ELEVATION_064_Rx:0, DET_ELEVATION_ERR_061_Rx:0, DET_ELEVATION_ERR_062_Rx:0, DET_ELEVATION_ERR_063_Rx:0, DET_ELEVATION_ERR_064_Rx:0, DET_EXISTENCE_PROB_061_Rx:0, DET_EXISTENCE_PROB_062_Rx:0, DET_EXISTENCE_PROB_063_Rx:0, DET_EXISTENCE_PROB_064_Rx:0, DET_HVC_FLAG_061_Rx:0, DET_HVC_FLAG_062_Rx:0, DET_HVC_FLAG_063_Rx:0, DET_HVC_FLAG_064_Rx:0, DET_IDM_061_Rx:0, DET_IDM_062_Rx:0, DET_IDM_063_Rx:0, DET_IDM_064_Rx:0, DET_MH_CRC16_061_064_Rx:0, DET_MH_CYCLE_COUNTER_061_064_Rx:0, DET_MH_SCAN_INDEX_4LSB_061_064_Rx:0, DET_MTD_061_Rx:0, DET_MTD_062_Rx:0, DET_MTD_063_Rx:0, DET_MTD_064_Rx:0, DET_PROB_1STAZHYPO_061_Rx:0, DET_PROB_1STAZHYPO_062_Rx:0, DET_PROB_1STAZHYPO_063_Rx:0, DET_PROB_1STAZHYPO_064_Rx:0, DET_RANGE_061_Rx:0, DET_RANGE_062_Rx:0, DET_RANGE_063_Rx:0, DET_RANGE_064_Rx:0, DET_RANGE_ERR_061_Rx:0, DET_RANGE_ERR_062_Rx:0, DET_RANGE_ERR_063_Rx:0, DET_RANGE_ERR_064_Rx:0, DET_RANGE_VELOCITY_061_Rx:0, DET_RANGE_VELOCITY_062_Rx:0, DET_RANGE_VELOCITY_063_Rx:0, DET_RANGE_VELOCITY_064_Rx:0, DET_RANGE_VELOCITY_ERR_061_Rx:0, DET_RANGE_VELOCITY_ERR_062_Rx:0, DET_RANGE_VELOCITY_ERR_063_Rx:0, DET_RANGE_VELOCITY_ERR_064_Rx:0, DET_RCS_061_Rx:0, DET_RCS_062_Rx:0, DET_RCS_063_Rx:0, DET_RCS_064_Rx:0, DET_SNR_061_Rx:0, DET_SNR_062_Rx:0, DET_SNR_063_Rx:0, DET_SNR_064_Rx:0, DET_SUPER_RES_TARGET_061_Rx:0, DET_SUPER_RES_TARGET_062_Rx:0, DET_SUPER_RES_TARGET_063_Rx:0, DET_SUPER_RES_TARGET_064_Rx:0]}, required-interface=Pi_SG_Fusion_Detections_061_064_AL
      Rp_SG_Fusion_Detections_065_068_AL: nonqueued-receiver-com-spec{data-element=Vdp_SG_Fusion_Detections_065_068_AL, init-value=fields=[DET_AZIMUTH_065_Rx:0, DET_AZIMUTH_066_Rx:0, DET_AZIMUTH_067_Rx:0, DET_AZIMUTH_068_Rx:0, DET_AZIMUTH_ERR_065_Rx:0, DET_AZIMUTH_ERR_066_Rx:0, DET_AZIMUTH_ERR_067_Rx:0, DET_AZIMUTH_ERR_068_Rx:0, DET_BELOW_RAIN_THOLD_065_Rx:0, DET_BELOW_RAIN_THOLD_066_Rx:0, DET_BELOW_RAIN_THOLD_067_Rx:0, DET_BELOW_RAIN_THOLD_068_Rx:0, DET_BI_STATIC_FLAG_065_Rx:0, DET_BI_STATIC_FLAG_066_Rx:0, DET_BI_STATIC_FLAG_067_Rx:0, DET_BI_STATIC_FLAG_068_Rx:0, DET_CONFD_AZIMUTH_065_Rx:0, DET_CONFD_AZIMUTH_066_Rx:0, DET_CONFD_AZIMUTH_067_Rx:0, DET_CONFD_AZIMUTH_068_Rx:0, DET_CONFD_ELEVATION_065_Rx:0, DET_CONFD_ELEVATION_066_Rx:0, DET_CONFD_ELEVATION_067_Rx:0, DET_CONFD_ELEVATION_068_Rx:0, DET_ELEVATION_065_Rx:0, DET_ELEVATION_066_Rx:0, DET_ELEVATION_067_Rx:0, DET_ELEVATION_068_Rx:0, DET_ELEVATION_ERR_065_Rx:0, DET_ELEVATION_ERR_066_Rx:0, DET_ELEVATION_ERR_067_Rx:0, DET_ELEVATION_ERR_068_Rx:0, DET_EXISTENCE_PROB_065_Rx:0, DET_EXISTENCE_PROB_066_Rx:0, DET_EXISTENCE_PROB_067_Rx:0, DET_EXISTENCE_PROB_068_Rx:0, DET_HVC_FLAG_065_Rx:0, DET_HVC_FLAG_066_Rx:0, DET_HVC_FLAG_067_Rx:0, DET_HVC_FLAG_068_Rx:0, DET_IDM_065_Rx:0, DET_IDM_066_Rx:0, DET_IDM_067_Rx:0, DET_IDM_068_Rx:0, DET_MH_CRC16_065_068_Rx:0, DET_MH_CYCLE_COUNTER_065_068_Rx:0, DET_MH_SCAN_INDEX_4LSB_065_068_Rx:0, DET_MTD_065_Rx:0, DET_MTD_066_Rx:0, DET_MTD_067_Rx:0, DET_MTD_068_Rx:0, DET_PROB_1STAZHYPO_065_Rx:0, DET_PROB_1STAZHYPO_066_Rx:0, DET_PROB_1STAZHYPO_067_Rx:0, DET_PROB_1STAZHYPO_068_Rx:0, DET_RANGE_065_Rx:0, DET_RANGE_066_Rx:0, DET_RANGE_067_Rx:0, DET_RANGE_068_Rx:0, DET_RANGE_ERR_065_Rx:0, DET_RANGE_ERR_066_Rx:0, DET_RANGE_ERR_067_Rx:0, DET_RANGE_ERR_068_Rx:0, DET_RANGE_VELOCITY_065_Rx:0, DET_RANGE_VELOCITY_066_Rx:0, DET_RANGE_VELOCITY_067_Rx:0, DET_RANGE_VELOCITY_068_Rx:0, DET_RANGE_VELOCITY_ERR_065_Rx:0, DET_RANGE_VELOCITY_ERR_066_Rx:0, DET_RANGE_VELOCITY_ERR_067_Rx:0, DET_RANGE_VELOCITY_ERR_068_Rx:0, DET_RCS_065_Rx:0, DET_RCS_066_Rx:0, DET_RCS_067_Rx:0, DET_RCS_068_Rx:0, DET_SNR_065_Rx:0, DET_SNR_066_Rx:0, DET_SNR_067_Rx:0, DET_SNR_068_Rx:0, DET_SUPER_RES_TARGET_065_Rx:0, DET_SUPER_RES_TARGET_066_Rx:0, DET_SUPER_RES_TARGET_067_Rx:0, DET_SUPER_RES_TARGET_068_Rx:0]}, required-interface=Pi_SG_Fusion_Detections_065_068_AL
      Rp_SG_Fusion_Detections_069_072_AL: nonqueued-receiver-com-spec{data-element=Vdp_SG_Fusion_Detections_069_072_AL, init-value=fields=[DET_AZIMUTH_069_Rx:0, DET_AZIMUTH_070_Rx:0, DET_AZIMUTH_071_Rx:0, DET_AZIMUTH_072_Rx:0, DET_AZIMUTH_ERR_069_Rx:0, DET_AZIMUTH_ERR_070_Rx:0, DET_AZIMUTH_ERR_071_Rx:0, DET_AZIMUTH_ERR_072_Rx:0, DET_BELOW_RAIN_THOLD_069_Rx:0, DET_BELOW_RAIN_THOLD_070_Rx:0, DET_BELOW_RAIN_THOLD_071_Rx:0, DET_BELOW_RAIN_THOLD_072_Rx:0, DET_BI_STATIC_FLAG_069_Rx:0, DET_BI_STATIC_FLAG_070_Rx:0, DET_BI_STATIC_FLAG_071_Rx:0, DET_BI_STATIC_FLAG_072_Rx:0, DET_CONFD_AZIMUTH_069_Rx:0, DET_CONFD_AZIMUTH_070_Rx:0, DET_CONFD_AZIMUTH_071_Rx:0, DET_CONFD_AZIMUTH_072_Rx:0, DET_CONFD_ELEVATION_069_Rx:0, DET_CONFD_ELEVATION_070_Rx:0, DET_CONFD_ELEVATION_071_Rx:0, DET_CONFD_ELEVATION_072_Rx:0, DET_ELEVATION_069_Rx:0, DET_ELEVATION_070_Rx:0, DET_ELEVATION_071_Rx:0, DET_ELEVATION_072_Rx:0, DET_ELEVATION_ERR_069_Rx:0, DET_ELEVATION_ERR_070_Rx:0, DET_ELEVATION_ERR_071_Rx:0, DET_ELEVATION_ERR_072_Rx:0, DET_EXISTENCE_PROB_069_Rx:0, DET_EXISTENCE_PROB_070_Rx:0, DET_EXISTENCE_PROB_071_Rx:0, DET_EXISTENCE_PROB_072_Rx:0, DET_HVC_FLAG_069_Rx:0, DET_HVC_FLAG_070_Rx:0, DET_HVC_FLAG_071_Rx:0, DET_HVC_FLAG_072_Rx:0, DET_IDM_069_Rx:0, DET_IDM_070_Rx:0, DET_IDM_071_Rx:0, DET_IDM_072_Rx:0, DET_MH_CRC16_069_072_Rx:0, DET_MH_CYCLE_COUNTER_069_072_Rx:0, DET_MH_SCAN_INDEX_4LSB_069_072_Rx:0, DET_MTD_069_Rx:0, DET_MTD_070_Rx:0, DET_MTD_071_Rx:0, DET_MTD_072_Rx:0, DET_PROB_1STAZHYPO_069_Rx:0, DET_PROB_1STAZHYPO_070_Rx:0, DET_PROB_1STAZHYPO_071_Rx:0, DET_PROB_1STAZHYPO_072_Rx:0, DET_RANGE_069_Rx:0, DET_RANGE_070_Rx:0, DET_RANGE_071_Rx:0, DET_RANGE_072_Rx:0, DET_RANGE_ERR_069_Rx:0, DET_RANGE_ERR_070_Rx:0, DET_RANGE_ERR_071_Rx:0, DET_RANGE_ERR_072_Rx:0, DET_RANGE_VELOCITY_069_Rx:0, DET_RANGE_VELOCITY_070_Rx:0, DET_RANGE_VELOCITY_071_Rx:0, DET_RANGE_VELOCITY_072_Rx:0, DET_RANGE_VELOCITY_ERR_069_Rx:0, DET_RANGE_VELOCITY_ERR_070_Rx:0, DET_RANGE_VELOCITY_ERR_071_Rx:0, DET_RANGE_VELOCITY_ERR_072_Rx:0, DET_RCS_069_Rx:0, DET_RCS_070_Rx:0, DET_RCS_071_Rx:0, DET_RCS_072_Rx:0, DET_SNR_069_Rx:0, DET_SNR_070_Rx:0, DET_SNR_071_Rx:0, DET_SNR_072_Rx:0, DET_SUPER_RES_TARGET_069_Rx:0, DET_SUPER_RES_TARGET_070_Rx:0, DET_SUPER_RES_TARGET_071_Rx:0, DET_SUPER_RES_TARGET_072_Rx:0]}, required-interface=Pi_SG_Fusion_Detections_069_072_AL
      Rp_SG_Fusion_Detections_073_076_AL: nonqueued-receiver-com-spec{data-element=Vdp_SG_Fusion_Detections_073_076_AL, init-value=fields=[DET_AZIMUTH_073_Rx:0, DET_AZIMUTH_074_Rx:0, DET_AZIMUTH_075_Rx:0, DET_AZIMUTH_076_Rx:0, DET_AZIMUTH_ERR_073_Rx:0, DET_AZIMUTH_ERR_074_Rx:0, DET_AZIMUTH_ERR_075_Rx:0, DET_AZIMUTH_ERR_076_Rx:0, DET_BELOW_RAIN_THOLD_073_Rx:0, DET_BELOW_RAIN_THOLD_074_Rx:0, DET_BELOW_RAIN_THOLD_075_Rx:0, DET_BELOW_RAIN_THOLD_076_Rx:0, DET_BI_STATIC_FLAG_073_Rx:0, DET_BI_STATIC_FLAG_074_Rx:0, DET_BI_STATIC_FLAG_075_Rx:0, DET_BI_STATIC_FLAG_076_Rx:0, DET_CONFD_AZIMUTH_073_Rx:0, DET_CONFD_AZIMUTH_074_Rx:0, DET_CONFD_AZIMUTH_075_Rx:0, DET_CONFD_AZIMUTH_076_Rx:0, DET_CONFD_ELEVATION_073_Rx:0, DET_CONFD_ELEVATION_074_Rx:0, DET_CONFD_ELEVATION_075_Rx:0, DET_CONFD_ELEVATION_076_Rx:0, DET_ELEVATION_073_Rx:0, DET_ELEVATION_074_Rx:0, DET_ELEVATION_075_Rx:0, DET_ELEVATION_076_Rx:0, DET_ELEVATION_ERR_073_Rx:0, DET_ELEVATION_ERR_074_Rx:0, DET_ELEVATION_ERR_075_Rx:0, DET_ELEVATION_ERR_076_Rx:0, DET_EXISTENCE_PROB_073_Rx:0, DET_EXISTENCE_PROB_074_Rx:0, DET_EXISTENCE_PROB_075_Rx:0, DET_EXISTENCE_PROB_076_Rx:0, DET_HVC_FLAG_073_Rx:0, DET_HVC_FLAG_074_Rx:0, DET_HVC_FLAG_075_Rx:0, DET_HVC_FLAG_076_Rx:0, DET_IDM_073_Rx:0, DET_IDM_074_Rx:0, DET_IDM_075_Rx:0, DET_IDM_076_Rx:0, DET_MH_CRC16_073_076_Rx:0, DET_MH_CYCLE_COUNTER_073_076_Rx:0, DET_MH_SCAN_INDEX_4LSB_073_076_Rx:0, DET_MTD_073_Rx:0, DET_MTD_074_Rx:0, DET_MTD_075_Rx:0, DET_MTD_076_Rx:0, DET_PROB_1STAZHYPO_073_Rx:0, DET_PROB_1STAZHYPO_074_Rx:0, DET_PROB_1STAZHYPO_075_Rx:0, DET_PROB_1STAZHYPO_076_Rx:0, DET_RANGE_073_Rx:0, DET_RANGE_074_Rx:0, DET_RANGE_075_Rx:0, DET_RANGE_076_Rx:0, DET_RANGE_ERR_073_Rx:0, DET_RANGE_ERR_074_Rx:0, DET_RANGE_ERR_075_Rx:0, DET_RANGE_ERR_076_Rx:0, DET_RANGE_VELOCITY_073_Rx:0, DET_RANGE_VELOCITY_074_Rx:0, DET_RANGE_VELOCITY_075_Rx:0, DET_RANGE_VELOCITY_076_Rx:0, DET_RANGE_VELOCITY_ERR_073_Rx:0, DET_RANGE_VELOCITY_ERR_074_Rx:0, DET_RANGE_VELOCITY_ERR_075_Rx:0, DET_RANGE_VELOCITY_ERR_076_Rx:0, DET_RCS_073_Rx:0, DET_RCS_074_Rx:0, DET_RCS_075_Rx:0, DET_RCS_076_Rx:0, DET_SNR_073_Rx:0, DET_SNR_074_Rx:0, DET_SNR_075_Rx:0, DET_SNR_076_Rx:0, DET_SUPER_RES_TARGET_073_Rx:0, DET_SUPER_RES_TARGET_074_Rx:0, DET_SUPER_RES_TARGET_075_Rx:0, DET_SUPER_RES_TARGET_076_Rx:0]}, required-interface=Pi_SG_Fusion_Detections_073_076_AL
      Rp_SG_Fusion_Detections_077_080_AL: nonqueued-receiver-com-spec{data-element=Vdp_SG_Fusion_Detections_077_080_AL, init-value=fields=[DET_AZIMUTH_077_Rx:0, DET_AZIMUTH_078_Rx:0, DET_AZIMUTH_079_Rx:0, DET_AZIMUTH_080_Rx:0, DET_AZIMUTH_ERR_077_Rx:0, DET_AZIMUTH_ERR_078_Rx:0, DET_AZIMUTH_ERR_079_Rx:0, DET_AZIMUTH_ERR_080_Rx:0, DET_BELOW_RAIN_THOLD_077_Rx:0, DET_BELOW_RAIN_THOLD_078_Rx:0, DET_BELOW_RAIN_THOLD_079_Rx:0, DET_BELOW_RAIN_THOLD_080_Rx:0, DET_BI_STATIC_FLAG_077_Rx:0, DET_BI_STATIC_FLAG_078_Rx:0, DET_BI_STATIC_FLAG_079_Rx:0, DET_BI_STATIC_FLAG_080_Rx:0, DET_CONFD_AZIMUTH_077_Rx:0, DET_CONFD_AZIMUTH_078_Rx:0, DET_CONFD_AZIMUTH_079_Rx:0, DET_CONFD_AZIMUTH_080_Rx:0, DET_CONFD_ELEVATION_077_Rx:0, DET_CONFD_ELEVATION_078_Rx:0, DET_CONFD_ELEVATION_079_Rx:0, DET_CONFD_ELEVATION_080_Rx:0, DET_ELEVATION_077_Rx:0, DET_ELEVATION_078_Rx:0, DET_ELEVATION_079_Rx:0, DET_ELEVATION_080_Rx:0, DET_ELEVATION_ERR_077_Rx:0, DET_ELEVATION_ERR_078_Rx:0, DET_ELEVATION_ERR_079_Rx:0, DET_ELEVATION_ERR_080_Rx:0, DET_EXISTENCE_PROB_077_Rx:0, DET_EXISTENCE_PROB_078_Rx:0, DET_EXISTENCE_PROB_079_Rx:0, DET_EXISTENCE_PROB_080_Rx:0, DET_HVC_FLAG_077_Rx:0, DET_HVC_FLAG_078_Rx:0, DET_HVC_FLAG_079_Rx:0, DET_HVC_FLAG_080_Rx:0, DET_IDM_077_Rx:0, DET_IDM_078_Rx:0, DET_IDM_079_Rx:0, DET_IDM_080_Rx:0, DET_MH_CRC16_077_080_Rx:0, DET_MH_CYCLE_COUNTER_077_080_Rx:0, DET_MH_SCAN_INDEX_4LSB_077_080_Rx:0, DET_MTD_077_Rx:0, DET_MTD_078_Rx:0, DET_MTD_079_Rx:0, DET_MTD_080_Rx:0, DET_PROB_1STAZHYPO_077_Rx:0, DET_PROB_1STAZHYPO_078_Rx:0, DET_PROB_1STAZHYPO_079_Rx:0, DET_PROB_1STAZHYPO_080_Rx:0, DET_RANGE_077_Rx:0, DET_RANGE_078_Rx:0, DET_RANGE_079_Rx:0, DET_RANGE_080_Rx:0, DET_RANGE_ERR_077_Rx:0, DET_RANGE_ERR_078_Rx:0, DET_RANGE_ERR_079_Rx:0, DET_RANGE_ERR_080_Rx:0, DET_RANGE_VELOCITY_077_Rx:0, DET_RANGE_VELOCITY_078_Rx:0, DET_RANGE_VELOCITY_079_Rx:0, DET_RANGE_VELOCITY_080_Rx:0, DET_RANGE_VELOCITY_ERR_077_Rx:0, DET_RANGE_VELOCITY_ERR_078_Rx:0, DET_RANGE_VELOCITY_ERR_079_Rx:0, DET_RANGE_VELOCITY_ERR_080_Rx:0, DET_RCS_077_Rx:0, DET_RCS_078_Rx:0, DET_RCS_079_Rx:0, DET_RCS_080_Rx:0, DET_SNR_077_Rx:0, DET_SNR_078_Rx:0, DET_SNR_079_Rx:0, DET_SNR_080_Rx:0, DET_SUPER_RES_TARGET_077_Rx:0, DET_SUPER_RES_TARGET_078_Rx:0, DET_SUPER_RES_TARGET_079_Rx:0, DET_SUPER_RES_TARGET_080_Rx:0]}, required-interface=Pi_SG_Fusion_Detections_077_080_AL
      Rp_SG_Fusion_Detections_081_084_AL: nonqueued-receiver-com-spec{data-element=Vdp_SG_Fusion_Detections_081_084_AL, init-value=fields=[DET_AZIMUTH_081_Rx:0, DET_AZIMUTH_082_Rx:0, DET_AZIMUTH_083_Rx:0, DET_AZIMUTH_084_Rx:0, DET_AZIMUTH_ERR_081_Rx:0, DET_AZIMUTH_ERR_082_Rx:0, DET_AZIMUTH_ERR_083_Rx:0, DET_AZIMUTH_ERR_084_Rx:0, DET_BELOW_RAIN_THOLD_081_Rx:0, DET_BELOW_RAIN_THOLD_082_Rx:0, DET_BELOW_RAIN_THOLD_083_Rx:0, DET_BELOW_RAIN_THOLD_084_Rx:0, DET_BI_STATIC_FLAG_081_Rx:0, DET_BI_STATIC_FLAG_082_Rx:0, DET_BI_STATIC_FLAG_083_Rx:0, DET_BI_STATIC_FLAG_084_Rx:0, DET_CONFD_AZIMUTH_081_Rx:0, DET_CONFD_AZIMUTH_082_Rx:0, DET_CONFD_AZIMUTH_083_Rx:0, DET_CONFD_AZIMUTH_084_Rx:0, DET_CONFD_ELEVATION_081_Rx:0, DET_CONFD_ELEVATION_082_Rx:0, DET_CONFD_ELEVATION_083_Rx:0, DET_CONFD_ELEVATION_084_Rx:0, DET_ELEVATION_081_Rx:0, DET_ELEVATION_082_Rx:0, DET_ELEVATION_083_Rx:0, DET_ELEVATION_084_Rx:0, DET_ELEVATION_ERR_081_Rx:0, DET_ELEVATION_ERR_082_Rx:0, DET_ELEVATION_ERR_083_Rx:0, DET_ELEVATION_ERR_084_Rx:0, DET_EXISTENCE_PROB_081_Rx:0, DET_EXISTENCE_PROB_082_Rx:0, DET_EXISTENCE_PROB_083_Rx:0, DET_EXISTENCE_PROB_084_Rx:0, DET_HVC_FLAG_081_Rx:0, DET_HVC_FLAG_082_Rx:0, DET_HVC_FLAG_083_Rx:0, DET_HVC_FLAG_084_Rx:0, DET_IDM_081_Rx:0, DET_IDM_082_Rx:0, DET_IDM_083_Rx:0, DET_IDM_084_Rx:0, DET_MH_CRC16_081_084_Rx:0, DET_MH_CYCLE_COUNTER_081_084_Rx:0, DET_MH_SCAN_INDEX_4LSB_081_084_Rx:0, DET_MTD_081_Rx:0, DET_MTD_082_Rx:0, DET_MTD_083_Rx:0, DET_MTD_084_Rx:0, DET_PROB_1STAZHYPO_081_Rx:0, DET_PROB_1STAZHYPO_082_Rx:0, DET_PROB_1STAZHYPO_083_Rx:0, DET_PROB_1STAZHYPO_084_Rx:0, DET_RANGE_081_Rx:0, DET_RANGE_082_Rx:0, DET_RANGE_083_Rx:0, DET_RANGE_084_Rx:0, DET_RANGE_ERR_081_Rx:0, DET_RANGE_ERR_082_Rx:0, DET_RANGE_ERR_083_Rx:0, DET_RANGE_ERR_084_Rx:0, DET_RANGE_VELOCITY_081_Rx:0, DET_RANGE_VELOCITY_082_Rx:0, DET_RANGE_VELOCITY_083_Rx:0, DET_RANGE_VELOCITY_084_Rx:0, DET_RANGE_VELOCITY_ERR_081_Rx:0, DET_RANGE_VELOCITY_ERR_082_Rx:0, DET_RANGE_VELOCITY_ERR_083_Rx:0, DET_RANGE_VELOCITY_ERR_084_Rx:0, DET_RCS_081_Rx:0, DET_RCS_082_Rx:0, DET_RCS_083_Rx:0, DET_RCS_084_Rx:0, DET_SNR_081_Rx:0, DET_SNR_082_Rx:0, DET_SNR_083_Rx:0, DET_SNR_084_Rx:0, DET_SUPER_RES_TARGET_081_Rx:0, DET_SUPER_RES_TARGET_082_Rx:0, DET_SUPER_RES_TARGET_083_Rx:0, DET_SUPER_RES_TARGET_084_Rx:0]}, required-interface=Pi_SG_Fusion_Detections_081_084_AL
      Rp_SG_Fusion_Detections_085_088_AL: nonqueued-receiver-com-spec{data-element=Vdp_SG_Fusion_Detections_085_088_AL, init-value=fields=[DET_AZIMUTH_085_Rx:0, DET_AZIMUTH_086_Rx:0, DET_AZIMUTH_087_Rx:0, DET_AZIMUTH_088_Rx:0, DET_AZIMUTH_ERR_085_Rx:0, DET_AZIMUTH_ERR_086_Rx:0, DET_AZIMUTH_ERR_087_Rx:0, DET_AZIMUTH_ERR_088_Rx:0, DET_BELOW_RAIN_THOLD_085_Rx:0, DET_BELOW_RAIN_THOLD_086_Rx:0, DET_BELOW_RAIN_THOLD_087_Rx:0, DET_BELOW_RAIN_THOLD_088_Rx:0, DET_BI_STATIC_FLAG_085_Rx:0, DET_BI_STATIC_FLAG_086_Rx:0, DET_BI_STATIC_FLAG_087_Rx:0, DET_BI_STATIC_FLAG_088_Rx:0, DET_CONFD_AZIMUTH_085_Rx:0, DET_CONFD_AZIMUTH_086_Rx:0, DET_CONFD_AZIMUTH_087_Rx:0, DET_CONFD_AZIMUTH_088_Rx:0, DET_CONFD_ELEVATION_085_Rx:0, DET_CONFD_ELEVATION_086_Rx:0, DET_CONFD_ELEVATION_087_Rx:0, DET_CONFD_ELEVATION_088_Rx:0, DET_ELEVATION_085_Rx:0, DET_ELEVATION_086_Rx:0, DET_ELEVATION_087_Rx:0, DET_ELEVATION_088_Rx:0, DET_ELEVATION_ERR_085_Rx:0, DET_ELEVATION_ERR_086_Rx:0, DET_ELEVATION_ERR_087_Rx:0, DET_ELEVATION_ERR_088_Rx:0, DET_EXISTENCE_PROB_085_Rx:0, DET_EXISTENCE_PROB_086_Rx:0, DET_EXISTENCE_PROB_087_Rx:0, DET_EXISTENCE_PROB_088_Rx:0, DET_HVC_FLAG_085_Rx:0, DET_HVC_FLAG_086_Rx:0, DET_HVC_FLAG_087_Rx:0, DET_HVC_FLAG_088_Rx:0, DET_IDM_085_Rx:0, DET_IDM_086_Rx:0, DET_IDM_087_Rx:0, DET_IDM_088_Rx:0, DET_MH_CRC16_085_088_Rx:0, DET_MH_CYCLE_COUNTER_085_088_Rx:0, DET_MH_SCAN_INDEX_4LSB_085_088_Rx:0, DET_MTD_085_Rx:0, DET_MTD_086_Rx:0, DET_MTD_087_Rx:0, DET_MTD_088_Rx:0, DET_PROB_1STAZHYPO_085_Rx:0, DET_PROB_1STAZHYPO_086_Rx:0, DET_PROB_1STAZHYPO_087_Rx:0, DET_PROB_1STAZHYPO_088_Rx:0, DET_RANGE_085_Rx:0, DET_RANGE_086_Rx:0, DET_RANGE_087_Rx:0, DET_RANGE_088_Rx:0, DET_RANGE_ERR_085_Rx:0, DET_RANGE_ERR_086_Rx:0, DET_RANGE_ERR_087_Rx:0, DET_RANGE_ERR_088_Rx:0, DET_RANGE_VELOCITY_085_Rx:0, DET_RANGE_VELOCITY_086_Rx:0, DET_RANGE_VELOCITY_087_Rx:0, DET_RANGE_VELOCITY_088_Rx:0, DET_RANGE_VELOCITY_ERR_085_Rx:0, DET_RANGE_VELOCITY_ERR_086_Rx:0, DET_RANGE_VELOCITY_ERR_087_Rx:0, DET_RANGE_VELOCITY_ERR_088_Rx:0, DET_RCS_085_Rx:0, DET_RCS_086_Rx:0, DET_RCS_087_Rx:0, DET_RCS_088_Rx:0, DET_SNR_085_Rx:0, DET_SNR_086_Rx:0, DET_SNR_087_Rx:0, DET_SNR_088_Rx:0, DET_SUPER_RES_TARGET_085_Rx:0, DET_SUPER_RES_TARGET_086_Rx:0, DET_SUPER_RES_TARGET_087_Rx:0, DET_SUPER_RES_TARGET_088_Rx:0]}, required-interface=Pi_SG_Fusion_Detections_085_088_AL
      Rp_SG_Fusion_Detections_089_092_AL: nonqueued-receiver-com-spec{data-element=Vdp_SG_Fusion_Detections_089_092_AL, init-value=fields=[DET_AZIMUTH_089_Rx:0, DET_AZIMUTH_090_Rx:0, DET_AZIMUTH_091_Rx:0, DET_AZIMUTH_092_Rx:0, DET_AZIMUTH_ERR_089_Rx:0, DET_AZIMUTH_ERR_090_Rx:0, DET_AZIMUTH_ERR_091_Rx:0, DET_AZIMUTH_ERR_092_Rx:0, DET_BELOW_RAIN_THOLD_089_Rx:0, DET_BELOW_RAIN_THOLD_090_Rx:0, DET_BELOW_RAIN_THOLD_091_Rx:0, DET_BELOW_RAIN_THOLD_092_Rx:0, DET_BI_STATIC_FLAG_089_Rx:0, DET_BI_STATIC_FLAG_090_Rx:0, DET_BI_STATIC_FLAG_091_Rx:0, DET_BI_STATIC_FLAG_092_Rx:0, DET_CONFD_AZIMUTH_089_Rx:0, DET_CONFD_AZIMUTH_090_Rx:0, DET_CONFD_AZIMUTH_091_Rx:0, DET_CONFD_AZIMUTH_092_Rx:0, DET_CONFD_ELEVATION_089_Rx:0, DET_CONFD_ELEVATION_090_Rx:0, DET_CONFD_ELEVATION_091_Rx:0, DET_CONFD_ELEVATION_092_Rx:0, DET_ELEVATION_089_Rx:0, DET_ELEVATION_090_Rx:0, DET_ELEVATION_091_Rx:0, DET_ELEVATION_092_Rx:0, DET_ELEVATION_ERR_089_Rx:0, DET_ELEVATION_ERR_090_Rx:0, DET_ELEVATION_ERR_091_Rx:0, DET_ELEVATION_ERR_092_Rx:0, DET_EXISTENCE_PROB_089_Rx:0, DET_EXISTENCE_PROB_090_Rx:0, DET_EXISTENCE_PROB_091_Rx:0, DET_EXISTENCE_PROB_092_Rx:0, DET_HVC_FLAG_089_Rx:0, DET_HVC_FLAG_090_Rx:0, DET_HVC_FLAG_091_Rx:0, DET_HVC_FLAG_092_Rx:0, DET_IDM_089_Rx:0, DET_IDM_090_Rx:0, DET_IDM_091_Rx:0, DET_IDM_092_Rx:0, DET_MH_CRC16_089_092_Rx:0, DET_MH_CYCLE_COUNTER_089_092_Rx:0, DET_MH_SCAN_INDEX_4LSB_089_092_Rx:0, DET_MTD_089_Rx:0, DET_MTD_090_Rx:0, DET_MTD_091_Rx:0, DET_MTD_092_Rx:0, DET_PROB_1STAZHYPO_089_Rx:0, DET_PROB_1STAZHYPO_090_Rx:0, DET_PROB_1STAZHYPO_091_Rx:0, DET_PROB_1STAZHYPO_092_Rx:0, DET_RANGE_089_Rx:0, DET_RANGE_090_Rx:0, DET_RANGE_091_Rx:0, DET_RANGE_092_Rx:0, DET_RANGE_ERR_089_Rx:0, DET_RANGE_ERR_090_Rx:0, DET_RANGE_ERR_091_Rx:0, DET_RANGE_ERR_092_Rx:0, DET_RANGE_VELOCITY_089_Rx:0, DET_RANGE_VELOCITY_090_Rx:0, DET_RANGE_VELOCITY_091_Rx:0, DET_RANGE_VELOCITY_092_Rx:0, DET_RANGE_VELOCITY_ERR_089_Rx:0, DET_RANGE_VELOCITY_ERR_090_Rx:0, DET_RANGE_VELOCITY_ERR_091_Rx:0, DET_RANGE_VELOCITY_ERR_092_Rx:0, DET_RCS_089_Rx:0, DET_RCS_090_Rx:0, DET_RCS_091_Rx:0, DET_RCS_092_Rx:0, DET_SNR_089_Rx:0, DET_SNR_090_Rx:0, DET_SNR_091_Rx:0, DET_SNR_092_Rx:0, DET_SUPER_RES_TARGET_089_Rx:0, DET_SUPER_RES_TARGET_090_Rx:0, DET_SUPER_RES_TARGET_091_Rx:0, DET_SUPER_RES_TARGET_092_Rx:0]}, required-interface=Pi_SG_Fusion_Detections_089_092_AL
      Rp_SG_Fusion_Detections_093_096_AL: nonqueued-receiver-com-spec{data-element=Vdp_SG_Fusion_Detections_093_096_AL, init-value=fields=[DET_AZIMUTH_093_Rx:0, DET_AZIMUTH_094_Rx:0, DET_AZIMUTH_095_Rx:0, DET_AZIMUTH_096_Rx:0, DET_AZIMUTH_ERR_093_Rx:0, DET_AZIMUTH_ERR_094_Rx:0, DET_AZIMUTH_ERR_095_Rx:0, DET_AZIMUTH_ERR_096_Rx:0, DET_BELOW_RAIN_THOLD_093_Rx:0, DET_BELOW_RAIN_THOLD_094_Rx:0, DET_BELOW_RAIN_THOLD_095_Rx:0, DET_BELOW_RAIN_THOLD_096_Rx:0, DET_BI_STATIC_FLAG_093_Rx:0, DET_BI_STATIC_FLAG_094_Rx:0, DET_BI_STATIC_FLAG_095_Rx:0, DET_BI_STATIC_FLAG_096_Rx:0, DET_CONFD_AZIMUTH_093_Rx:0, DET_CONFD_AZIMUTH_094_Rx:0, DET_CONFD_AZIMUTH_095_Rx:0, DET_CONFD_AZIMUTH_096_Rx:0, DET_CONFD_ELEVATION_093_Rx:0, DET_CONFD_ELEVATION_094_Rx:0, DET_CONFD_ELEVATION_095_Rx:0, DET_CONFD_ELEVATION_096_Rx:0, DET_ELEVATION_093_Rx:0, DET_ELEVATION_094_Rx:0, DET_ELEVATION_095_Rx:0, DET_ELEVATION_096_Rx:0, DET_ELEVATION_ERR_093_Rx:0, DET_ELEVATION_ERR_094_Rx:0, DET_ELEVATION_ERR_095_Rx:0, DET_ELEVATION_ERR_096_Rx:0, DET_EXISTENCE_PROB_093_Rx:0, DET_EXISTENCE_PROB_094_Rx:0, DET_EXISTENCE_PROB_095_Rx:0, DET_EXISTENCE_PROB_096_Rx:0, DET_HVC_FLAG_093_Rx:0, DET_HVC_FLAG_094_Rx:0, DET_HVC_FLAG_095_Rx:0, DET_HVC_FLAG_096_Rx:0, DET_IDM_093_Rx:0, DET_IDM_094_Rx:0, DET_IDM_095_Rx:0, DET_IDM_096_Rx:0, DET_MH_CRC16_093_096_Rx:0, DET_MH_CYCLE_COUNTER_093_096_Rx:0, DET_MH_SCAN_INDEX_4LSB_093_096_Rx:0, DET_MTD_093_Rx:0, DET_MTD_094_Rx:0, DET_MTD_095_Rx:0, DET_MTD_096_Rx:0, DET_PROB_1STAZHYPO_093_Rx:0, DET_PROB_1STAZHYPO_094_Rx:0, DET_PROB_1STAZHYPO_095_Rx:0, DET_PROB_1STAZHYPO_096_Rx:0, DET_RANGE_093_Rx:0, DET_RANGE_094_Rx:0, DET_RANGE_095_Rx:0, DET_RANGE_096_Rx:0, DET_RANGE_ERR_093_Rx:0, DET_RANGE_ERR_094_Rx:0, DET_RANGE_ERR_095_Rx:0, DET_RANGE_ERR_096_Rx:0, DET_RANGE_VELOCITY_093_Rx:0, DET_RANGE_VELOCITY_094_Rx:0, DET_RANGE_VELOCITY_095_Rx:0, DET_RANGE_VELOCITY_096_Rx:0, DET_RANGE_VELOCITY_ERR_093_Rx:0, DET_RANGE_VELOCITY_ERR_094_Rx:0, DET_RANGE_VELOCITY_ERR_095_Rx:0, DET_RANGE_VELOCITY_ERR_096_Rx:0, DET_RCS_093_Rx:0, DET_RCS_094_Rx:0, DET_RCS_095_Rx:0, DET_RCS_096_Rx:0, DET_SNR_093_Rx:0, DET_SNR_094_Rx:0, DET_SNR_095_Rx:0, DET_SNR_096_Rx:0, DET_SUPER_RES_TARGET_093_Rx:0, DET_SUPER_RES_TARGET_094_Rx:0, DET_SUPER_RES_TARGET_095_Rx:0, DET_SUPER_RES_TARGET_096_Rx:0]}, required-interface=Pi_SG_Fusion_Detections_093_096_AL
      Rp_SG_Fusion_Detections_097_100_AL: nonqueued-receiver-com-spec{data-element=Vdp_SG_Fusion_Detections_097_100_AL, init-value=fields=[DET_AZIMUTH_097_Rx:0, DET_AZIMUTH_098_Rx:0, DET_AZIMUTH_099_Rx:0, DET_AZIMUTH_100_Rx:0, DET_AZIMUTH_ERR_097_Rx:0, DET_AZIMUTH_ERR_098_Rx:0, DET_AZIMUTH_ERR_099_Rx:0, DET_AZIMUTH_ERR_100_Rx:0, DET_BELOW_RAIN_THOLD_097_Rx:0, DET_BELOW_RAIN_THOLD_098_Rx:0, DET_BELOW_RAIN_THOLD_099_Rx:0, DET_BELOW_RAIN_THOLD_100_Rx:0, DET_BI_STATIC_FLAG_097_Rx:0, DET_BI_STATIC_FLAG_098_Rx:0, DET_BI_STATIC_FLAG_099_Rx:0, DET_BI_STATIC_FLAG_100_Rx:0, DET_CONFD_AZIMUTH_097_Rx:0, DET_CONFD_AZIMUTH_098_Rx:0, DET_CONFD_AZIMUTH_099_Rx:0, DET_CONFD_AZIMUTH_100_Rx:0, DET_CONFD_ELEVATION_097_Rx:0, DET_CONFD_ELEVATION_098_Rx:0, DET_CONFD_ELEVATION_099_Rx:0, DET_CONFD_ELEVATION_100_Rx:0, DET_ELEVATION_097_Rx:0, DET_ELEVATION_098_Rx:0, DET_ELEVATION_099_Rx:0, DET_ELEVATION_100_Rx:0, DET_ELEVATION_ERR_097_Rx:0, DET_ELEVATION_ERR_098_Rx:0, DET_ELEVATION_ERR_099_Rx:0, DET_ELEVATION_ERR_100_Rx:0, DET_EXISTENCE_PROB_097_Rx:0, DET_EXISTENCE_PROB_098_Rx:0, DET_EXISTENCE_PROB_099_Rx:0, DET_EXISTENCE_PROB_100_Rx:0, DET_HVC_FLAG_097_Rx:0, DET_HVC_FLAG_098_Rx:0, DET_HVC_FLAG_099_Rx:0, DET_HVC_FLAG_100_Rx:0, DET_IDM_097_Rx:0, DET_IDM_098_Rx:0, DET_IDM_099_Rx:0, DET_IDM_100_Rx:0, DET_MH_CRC16_097_100_Rx:0, DET_MH_CYCLE_COUNTER_097_100_Rx:0, DET_MH_SCAN_INDEX_4LSB_097_100_Rx:0, DET_MTD_097_Rx:0, DET_MTD_098_Rx:0, DET_MTD_099_Rx:0, DET_MTD_100_Rx:0, DET_PROB_1STAZHYPO_097_Rx:0, DET_PROB_1STAZHYPO_098_Rx:0, DET_PROB_1STAZHYPO_099_Rx:0, DET_PROB_1STAZHYPO_100_Rx:0, DET_RANGE_097_Rx:0, DET_RANGE_098_Rx:0, DET_RANGE_099_Rx:0, DET_RANGE_100_Rx:0, DET_RANGE_ERR_097_Rx:0, DET_RANGE_ERR_098_Rx:0, DET_RANGE_ERR_099_Rx:0, DET_RANGE_ERR_100_Rx:0, DET_RANGE_VELOCITY_097_Rx:0, DET_RANGE_VELOCITY_098_Rx:0, DET_RANGE_VELOCITY_099_Rx:0, DET_RANGE_VELOCITY_100_Rx:0, DET_RANGE_VELOCITY_ERR_097_Rx:0, DET_RANGE_VELOCITY_ERR_098_Rx:0, DET_RANGE_VELOCITY_ERR_099_Rx:0, DET_RANGE_VELOCITY_ERR_100_Rx:0, DET_RCS_097_Rx:0, DET_RCS_098_Rx:0, DET_RCS_099_Rx:0, DET_RCS_100_Rx:0, DET_SNR_097_Rx:0, DET_SNR_098_Rx:0, DET_SNR_099_Rx:0, DET_SNR_100_Rx:0, DET_SUPER_RES_TARGET_097_Rx:0, DET_SUPER_RES_TARGET_098_Rx:0, DET_SUPER_RES_TARGET_099_Rx:0, DET_SUPER_RES_TARGET_100_Rx:0]}, required-interface=Pi_SG_Fusion_Detections_097_100_AL
      Rp_SG_Fusion_Detections_101_104_AL: nonqueued-receiver-com-spec{data-element=Vdp_SG_Fusion_Detections_101_104_AL, init-value=fields=[DET_AZIMUTH_101_Rx:0, DET_AZIMUTH_102_Rx:0, DET_AZIMUTH_103_Rx:0, DET_AZIMUTH_104_Rx:0, DET_AZIMUTH_ERR_101_Rx:0, DET_AZIMUTH_ERR_102_Rx:0, DET_AZIMUTH_ERR_103_Rx:0, DET_AZIMUTH_ERR_104_Rx:0, DET_BELOW_RAIN_THOLD_101_Rx:0, DET_BELOW_RAIN_THOLD_102_Rx:0, DET_BELOW_RAIN_THOLD_103_Rx:0, DET_BELOW_RAIN_THOLD_104_Rx:0, DET_BI_STATIC_FLAG_101_Rx:0, DET_BI_STATIC_FLAG_102_Rx:0, DET_BI_STATIC_FLAG_103_Rx:0, DET_BI_STATIC_FLAG_104_Rx:0, DET_CONFD_AZIMUTH_101_Rx:0, DET_CONFD_AZIMUTH_102_Rx:0, DET_CONFD_AZIMUTH_103_Rx:0, DET_CONFD_AZIMUTH_104_Rx:0, DET_CONFD_ELEVATION_101_Rx:0, DET_CONFD_ELEVATION_102_Rx:0, DET_CONFD_ELEVATION_103_Rx:0, DET_CONFD_ELEVATION_104_Rx:0, DET_ELEVATION_101_Rx:0, DET_ELEVATION_102_Rx:0, DET_ELEVATION_103_Rx:0, DET_ELEVATION_104_Rx:0, DET_ELEVATION_ERR_101_Rx:0, DET_ELEVATION_ERR_102_Rx:0, DET_ELEVATION_ERR_103_Rx:0, DET_ELEVATION_ERR_104_Rx:0, DET_EXISTENCE_PROB_101_Rx:0, DET_EXISTENCE_PROB_102_Rx:0, DET_EXISTENCE_PROB_103_Rx:0, DET_EXISTENCE_PROB_104_Rx:0, DET_HVC_FLAG_101_Rx:0, DET_HVC_FLAG_102_Rx:0, DET_HVC_FLAG_103_Rx:0, DET_HVC_FLAG_104_Rx:0, DET_IDM_101_Rx:0, DET_IDM_102_Rx:0, DET_IDM_103_Rx:0, DET_IDM_104_Rx:0, DET_MH_CRC16_101_104_Rx:0, DET_MH_CYCLE_COUNTER_101_104_Rx:0, DET_MH_SCAN_INDEX_4LSB_101_104_Rx:0, DET_MTD_101_Rx:0, DET_MTD_102_Rx:0, DET_MTD_103_Rx:0, DET_MTD_104_Rx:0, DET_PROB_1STAZHYPO_101_Rx:0, DET_PROB_1STAZHYPO_102_Rx:0, DET_PROB_1STAZHYPO_103_Rx:0, DET_PROB_1STAZHYPO_104_Rx:0, DET_RANGE_101_Rx:0, DET_RANGE_102_Rx:0, DET_RANGE_103_Rx:0, DET_RANGE_104_Rx:0, DET_RANGE_ERR_101_Rx:0, DET_RANGE_ERR_102_Rx:0, DET_RANGE_ERR_103_Rx:0, DET_RANGE_ERR_104_Rx:0, DET_RANGE_VELOCITY_101_Rx:0, DET_RANGE_VELOCITY_102_Rx:0, DET_RANGE_VELOCITY_103_Rx:0, DET_RANGE_VELOCITY_104_Rx:0, DET_RANGE_VELOCITY_ERR_101_Rx:0, DET_RANGE_VELOCITY_ERR_102_Rx:0, DET_RANGE_VELOCITY_ERR_103_Rx:0, DET_RANGE_VELOCITY_ERR_104_Rx:0, DET_RCS_101_Rx:0, DET_RCS_102_Rx:0, DET_RCS_103_Rx:0, DET_RCS_104_Rx:0, DET_SNR_101_Rx:0, DET_SNR_102_Rx:0, DET_SNR_103_Rx:0, DET_SNR_104_Rx:0, DET_SUPER_RES_TARGET_101_Rx:0, DET_SUPER_RES_TARGET_102_Rx:0, DET_SUPER_RES_TARGET_103_Rx:0, DET_SUPER_RES_TARGET_104_Rx:0]}, required-interface=Pi_SG_Fusion_Detections_101_104_AL
      Rp_SG_Fusion_Detections_105_108_AL: nonqueued-receiver-com-spec{data-element=Vdp_SG_Fusion_Detections_105_108_AL, init-value=fields=[DET_AZIMUTH_105_Rx:0, DET_AZIMUTH_106_Rx:0, DET_AZIMUTH_107_Rx:0, DET_AZIMUTH_108_Rx:0, DET_AZIMUTH_ERR_105_Rx:0, DET_AZIMUTH_ERR_106_Rx:0, DET_AZIMUTH_ERR_107_Rx:0, DET_AZIMUTH_ERR_108_Rx:0, DET_BELOW_RAIN_THOLD_105_Rx:0, DET_BELOW_RAIN_THOLD_106_Rx:0, DET_BELOW_RAIN_THOLD_107_Rx:0, DET_BELOW_RAIN_THOLD_108_Rx:0, DET_BI_STATIC_FLAG_105_Rx:0, DET_BI_STATIC_FLAG_106_Rx:0, DET_BI_STATIC_FLAG_107_Rx:0, DET_BI_STATIC_FLAG_108_Rx:0, DET_CONFD_AZIMUTH_105_Rx:0, DET_CONFD_AZIMUTH_106_Rx:0, DET_CONFD_AZIMUTH_107_Rx:0, DET_CONFD_AZIMUTH_108_Rx:0, DET_CONFD_ELEVATION_105_Rx:0, DET_CONFD_ELEVATION_106_Rx:0, DET_CONFD_ELEVATION_107_Rx:0, DET_CONFD_ELEVATION_108_Rx:0, DET_ELEVATION_105_Rx:0, DET_ELEVATION_106_Rx:0, DET_ELEVATION_107_Rx:0, DET_ELEVATION_108_Rx:0, DET_ELEVATION_ERR_105_Rx:0, DET_ELEVATION_ERR_106_Rx:0, DET_ELEVATION_ERR_107_Rx:0, DET_ELEVATION_ERR_108_Rx:0, DET_EXISTENCE_PROB_105_Rx:0, DET_EXISTENCE_PROB_106_Rx:0, DET_EXISTENCE_PROB_107_Rx:0, DET_EXISTENCE_PROB_108_Rx:0, DET_HVC_FLAG_105_Rx:0, DET_HVC_FLAG_106_Rx:0, DET_HVC_FLAG_107_Rx:0, DET_HVC_FLAG_108_Rx:0, DET_IDM_105_Rx:0, DET_IDM_106_Rx:0, DET_IDM_107_Rx:0, DET_IDM_108_Rx:0, DET_MH_CRC16_105_108_Rx:0, DET_MH_CYCLE_COUNTER_105_108_Rx:0, DET_MH_SCAN_INDEX_4LSB_105_108_Rx:0, DET_MTD_105_Rx:0, DET_MTD_106_Rx:0, DET_MTD_107_Rx:0, DET_MTD_108_Rx:0, DET_PROB_1STAZHYPO_105_Rx:0, DET_PROB_1STAZHYPO_106_Rx:0, DET_PROB_1STAZHYPO_107_Rx:0, DET_PROB_1STAZHYPO_108_Rx:0, DET_RANGE_105_Rx:0, DET_RANGE_106_Rx:0, DET_RANGE_107_Rx:0, DET_RANGE_108_Rx:0, DET_RANGE_ERR_105_Rx:0, DET_RANGE_ERR_106_Rx:0, DET_RANGE_ERR_107_Rx:0, DET_RANGE_ERR_108_Rx:0, DET_RANGE_VELOCITY_105_Rx:0, DET_RANGE_VELOCITY_106_Rx:0, DET_RANGE_VELOCITY_107_Rx:0, DET_RANGE_VELOCITY_108_Rx:0, DET_RANGE_VELOCITY_ERR_105_Rx:0, DET_RANGE_VELOCITY_ERR_106_Rx:0, DET_RANGE_VELOCITY_ERR_107_Rx:0, DET_RANGE_VELOCITY_ERR_108_Rx:0, DET_RCS_105_Rx:0, DET_RCS_106_Rx:0, DET_RCS_107_Rx:0, DET_RCS_108_Rx:0, DET_SNR_105_Rx:0, DET_SNR_106_Rx:0, DET_SNR_107_Rx:0, DET_SNR_108_Rx:0, DET_SUPER_RES_TARGET_105_Rx:0, DET_SUPER_RES_TARGET_106_Rx:0, DET_SUPER_RES_TARGET_107_Rx:0, DET_SUPER_RES_TARGET_108_Rx:0]}, required-interface=Pi_SG_Fusion_Detections_105_108_AL
      Rp_SG_Fusion_Detections_109_112_AL: nonqueued-receiver-com-spec{data-element=Vdp_SG_Fusion_Detections_109_112_AL, init-value=fields=[DET_AZIMUTH_109_Rx:0, DET_AZIMUTH_110_Rx:0, DET_AZIMUTH_111_Rx:0, DET_AZIMUTH_112_Rx:0, DET_AZIMUTH_ERR_109_Rx:0, DET_AZIMUTH_ERR_110_Rx:0, DET_AZIMUTH_ERR_111_Rx:0, DET_AZIMUTH_ERR_112_Rx:0, DET_BELOW_RAIN_THOLD_109_Rx:0, DET_BELOW_RAIN_THOLD_110_Rx:0, DET_BELOW_RAIN_THOLD_111_Rx:0, DET_BELOW_RAIN_THOLD_112_Rx:0, DET_BI_STATIC_FLAG_109_Rx:0, DET_BI_STATIC_FLAG_110_Rx:0, DET_BI_STATIC_FLAG_111_Rx:0, DET_BI_STATIC_FLAG_112_Rx:0, DET_CONFD_AZIMUTH_109_Rx:0, DET_CONFD_AZIMUTH_110_Rx:0, DET_CONFD_AZIMUTH_111_Rx:0, DET_CONFD_AZIMUTH_112_Rx:0, DET_CONFD_ELEVATION_109_Rx:0, DET_CONFD_ELEVATION_110_Rx:0, DET_CONFD_ELEVATION_111_Rx:0, DET_CONFD_ELEVATION_112_Rx:0, DET_ELEVATION_109_Rx:0, DET_ELEVATION_110_Rx:0, DET_ELEVATION_111_Rx:0, DET_ELEVATION_112_Rx:0, DET_ELEVATION_ERR_109_Rx:0, DET_ELEVATION_ERR_110_Rx:0, DET_ELEVATION_ERR_111_Rx:0, DET_ELEVATION_ERR_112_Rx:0, DET_EXISTENCE_PROB_109_Rx:0, DET_EXISTENCE_PROB_110_Rx:0, DET_EXISTENCE_PROB_111_Rx:0, DET_EXISTENCE_PROB_112_Rx:0, DET_HVC_FLAG_109_Rx:0, DET_HVC_FLAG_110_Rx:0, DET_HVC_FLAG_111_Rx:0, DET_HVC_FLAG_112_Rx:0, DET_IDM_109_Rx:0, DET_IDM_110_Rx:0, DET_IDM_111_Rx:0, DET_IDM_112_Rx:0, DET_MH_CRC16_109_112_Rx:0, DET_MH_CYCLE_COUNTER_109_112_Rx:0, DET_MH_SCAN_INDEX_4LSB_109_112_Rx:0, DET_MTD_109_Rx:0, DET_MTD_110_Rx:0, DET_MTD_111_Rx:0, DET_MTD_112_Rx:0, DET_PROB_1STAZHYPO_109_Rx:0, DET_PROB_1STAZHYPO_110_Rx:0, DET_PROB_1STAZHYPO_111_Rx:0, DET_PROB_1STAZHYPO_112_Rx:0, DET_RANGE_109_Rx:0, DET_RANGE_110_Rx:0, DET_RANGE_111_Rx:0, DET_RANGE_112_Rx:0, DET_RANGE_ERR_109_Rx:0, DET_RANGE_ERR_110_Rx:0, DET_RANGE_ERR_111_Rx:0, DET_RANGE_ERR_112_Rx:0, DET_RANGE_VELOCITY_109_Rx:0, DET_RANGE_VELOCITY_110_Rx:0, DET_RANGE_VELOCITY_111_Rx:0, DET_RANGE_VELOCITY_112_Rx:0, DET_RANGE_VELOCITY_ERR_109_Rx:0, DET_RANGE_VELOCITY_ERR_110_Rx:0, DET_RANGE_VELOCITY_ERR_111_Rx:0, DET_RANGE_VELOCITY_ERR_112_Rx:0, DET_RCS_109_Rx:0, DET_RCS_110_Rx:0, DET_RCS_111_Rx:0, DET_RCS_112_Rx:0, DET_SNR_109_Rx:0, DET_SNR_110_Rx:0, DET_SNR_111_Rx:0, DET_SNR_112_Rx:0, DET_SUPER_RES_TARGET_109_Rx:0, DET_SUPER_RES_TARGET_110_Rx:0, DET_SUPER_RES_TARGET_111_Rx:0, DET_SUPER_RES_TARGET_112_Rx:0]}, required-interface=Pi_SG_Fusion_Detections_109_112_AL
      Rp_SG_Fusion_Detections_113_116_AL: nonqueued-receiver-com-spec{data-element=Vdp_SG_Fusion_Detections_113_116_AL, init-value=fields=[DET_AZIMUTH_113_Rx:0, DET_AZIMUTH_114_Rx:0, DET_AZIMUTH_115_Rx:0, DET_AZIMUTH_116_Rx:0, DET_AZIMUTH_ERR_113_Rx:0, DET_AZIMUTH_ERR_114_Rx:0, DET_AZIMUTH_ERR_115_Rx:0, DET_AZIMUTH_ERR_116_Rx:0, DET_BELOW_RAIN_THOLD_113_Rx:0, DET_BELOW_RAIN_THOLD_114_Rx:0, DET_BELOW_RAIN_THOLD_115_Rx:0, DET_BELOW_RAIN_THOLD_116_Rx:0, DET_BI_STATIC_FLAG_113_Rx:0, DET_BI_STATIC_FLAG_114_Rx:0, DET_BI_STATIC_FLAG_115_Rx:0, DET_BI_STATIC_FLAG_116_Rx:0, DET_CONFD_AZIMUTH_113_Rx:0, DET_CONFD_AZIMUTH_114_Rx:0, DET_CONFD_AZIMUTH_115_Rx:0, DET_CONFD_AZIMUTH_116_Rx:0, DET_CONFD_ELEVATION_113_Rx:0, DET_CONFD_ELEVATION_114_Rx:0, DET_CONFD_ELEVATION_115_Rx:0, DET_CONFD_ELEVATION_116_Rx:0, DET_ELEVATION_113_Rx:0, DET_ELEVATION_114_Rx:0, DET_ELEVATION_115_Rx:0, DET_ELEVATION_116_Rx:0, DET_ELEVATION_ERR_113_Rx:0, DET_ELEVATION_ERR_114_Rx:0, DET_ELEVATION_ERR_115_Rx:0, DET_ELEVATION_ERR_116_Rx:0, DET_EXISTENCE_PROB_113_Rx:0, DET_EXISTENCE_PROB_114_Rx:0, DET_EXISTENCE_PROB_115_Rx:0, DET_EXISTENCE_PROB_116_Rx:0, DET_HVC_FLAG_113_Rx:0, DET_HVC_FLAG_114_Rx:0, DET_HVC_FLAG_115_Rx:0, DET_HVC_FLAG_116_Rx:0, DET_IDM_113_Rx:0, DET_IDM_114_Rx:0, DET_IDM_115_Rx:0, DET_IDM_116_Rx:0, DET_MH_CRC16_113_116_Rx:0, DET_MH_CYCLE_COUNTER_113_116_Rx:0, DET_MH_SCAN_INDEX_4LSB_113_116_Rx:0, DET_MTD_113_Rx:0, DET_MTD_114_Rx:0, DET_MTD_115_Rx:0, DET_MTD_116_Rx:0, DET_PROB_1STAZHYPO_113_Rx:0, DET_PROB_1STAZHYPO_114_Rx:0, DET_PROB_1STAZHYPO_115_Rx:0, DET_PROB_1STAZHYPO_116_Rx:0, DET_RANGE_113_Rx:0, DET_RANGE_114_Rx:0, DET_RANGE_115_Rx:0, DET_RANGE_116_Rx:0, DET_RANGE_ERR_113_Rx:0, DET_RANGE_ERR_114_Rx:0, DET_RANGE_ERR_115_Rx:0, DET_RANGE_ERR_116_Rx:0, DET_RANGE_VELOCITY_113_Rx:0, DET_RANGE_VELOCITY_114_Rx:0, DET_RANGE_VELOCITY_115_Rx:0, DET_RANGE_VELOCITY_116_Rx:0, DET_RANGE_VELOCITY_ERR_113_Rx:0, DET_RANGE_VELOCITY_ERR_114_Rx:0, DET_RANGE_VELOCITY_ERR_115_Rx:0, DET_RANGE_VELOCITY_ERR_116_Rx:0, DET_RCS_113_Rx:0, DET_RCS_114_Rx:0, DET_RCS_115_Rx:0, DET_RCS_116_Rx:0, DET_SNR_113_Rx:0, DET_SNR_114_Rx:0, DET_SNR_115_Rx:0, DET_SNR_116_Rx:0, DET_SUPER_RES_TARGET_113_Rx:0, DET_SUPER_RES_TARGET_114_Rx:0, DET_SUPER_RES_TARGET_115_Rx:0, DET_SUPER_RES_TARGET_116_Rx:0]}, required-interface=Pi_SG_Fusion_Detections_113_116_AL
      Rp_SG_Fusion_Detections_117_120_AL: nonqueued-receiver-com-spec{data-element=Vdp_SG_Fusion_Detections_117_120_AL, init-value=fields=[DET_AZIMUTH_117_Rx:0, DET_AZIMUTH_118_Rx:0, DET_AZIMUTH_119_Rx:0, DET_AZIMUTH_120_Rx:0, DET_AZIMUTH_ERR_117_Rx:0, DET_AZIMUTH_ERR_118_Rx:0, DET_AZIMUTH_ERR_119_Rx:0, DET_AZIMUTH_ERR_120_Rx:0, DET_BELOW_RAIN_THOLD_117_Rx:0, DET_BELOW_RAIN_THOLD_118_Rx:0, DET_BELOW_RAIN_THOLD_119_Rx:0, DET_BELOW_RAIN_THOLD_120_Rx:0, DET_BI_STATIC_FLAG_117_Rx:0, DET_BI_STATIC_FLAG_118_Rx:0, DET_BI_STATIC_FLAG_119_Rx:0, DET_BI_STATIC_FLAG_120_Rx:0, DET_CONFD_AZIMUTH_117_Rx:0, DET_CONFD_AZIMUTH_118_Rx:0, DET_CONFD_AZIMUTH_119_Rx:0, DET_CONFD_AZIMUTH_120_Rx:0, DET_CONFD_ELEVATION_117_Rx:0, DET_CONFD_ELEVATION_118_Rx:0, DET_CONFD_ELEVATION_119_Rx:0, DET_CONFD_ELEVATION_120_Rx:0, DET_ELEVATION_117_Rx:0, DET_ELEVATION_118_Rx:0, DET_ELEVATION_119_Rx:0, DET_ELEVATION_120_Rx:0, DET_ELEVATION_ERR_117_Rx:0, DET_ELEVATION_ERR_118_Rx:0, DET_ELEVATION_ERR_119_Rx:0, DET_ELEVATION_ERR_120_Rx:0, DET_EXISTENCE_PROB_117_Rx:0, DET_EXISTENCE_PROB_118_Rx:0, DET_EXISTENCE_PROB_119_Rx:0, DET_EXISTENCE_PROB_120_Rx:0, DET_HVC_FLAG_117_Rx:0, DET_HVC_FLAG_118_Rx:0, DET_HVC_FLAG_119_Rx:0, DET_HVC_FLAG_120_Rx:0, DET_IDM_117_Rx:0, DET_IDM_118_Rx:0, DET_IDM_119_Rx:0, DET_IDM_120_Rx:0, DET_MH_CRC16_117_120_Rx:0, DET_MH_CYCLE_COUNTER_117_120_Rx:0, DET_MH_SCAN_INDEX_4LSB_117_120_Rx:0, DET_MTD_117_Rx:0, DET_MTD_118_Rx:0, DET_MTD_119_Rx:0, DET_MTD_120_Rx:0, DET_PROB_1STAZHYPO_117_Rx:0, DET_PROB_1STAZHYPO_118_Rx:0, DET_PROB_1STAZHYPO_119_Rx:0, DET_PROB_1STAZHYPO_120_Rx:0, DET_RANGE_117_Rx:0, DET_RANGE_118_Rx:0, DET_RANGE_119_Rx:0, DET_RANGE_120_Rx:0, DET_RANGE_ERR_117_Rx:0, DET_RANGE_ERR_118_Rx:0, DET_RANGE_ERR_119_Rx:0, DET_RANGE_ERR_120_Rx:0, DET_RANGE_VELOCITY_117_Rx:0, DET_RANGE_VELOCITY_118_Rx:0, DET_RANGE_VELOCITY_119_Rx:0, DET_RANGE_VELOCITY_120_Rx:0, DET_RANGE_VELOCITY_ERR_117_Rx:0, DET_RANGE_VELOCITY_ERR_118_Rx:0, DET_RANGE_VELOCITY_ERR_119_Rx:0, DET_RANGE_VELOCITY_ERR_120_Rx:0, DET_RCS_117_Rx:0, DET_RCS_118_Rx:0, DET_RCS_119_Rx:0, DET_RCS_120_Rx:0, DET_SNR_117_Rx:0, DET_SNR_118_Rx:0, DET_SNR_119_Rx:0, DET_SNR_120_Rx:0, DET_SUPER_RES_TARGET_117_Rx:0, DET_SUPER_RES_TARGET_118_Rx:0, DET_SUPER_RES_TARGET_119_Rx:0, DET_SUPER_RES_TARGET_120_Rx:0]}, required-interface=Pi_SG_Fusion_Detections_117_120_AL
      Rp_SG_Fusion_Detections_121_124_AL: nonqueued-receiver-com-spec{data-element=Vdp_SG_Fusion_Detections_121_124_AL, init-value=fields=[DET_AZIMUTH_121_Rx:0, DET_AZIMUTH_122_Rx:0, DET_AZIMUTH_123_Rx:0, DET_AZIMUTH_124_Rx:0, DET_AZIMUTH_ERR_121_Rx:0, DET_AZIMUTH_ERR_122_Rx:0, DET_AZIMUTH_ERR_123_Rx:0, DET_AZIMUTH_ERR_124_Rx:0, DET_BELOW_RAIN_THOLD_121_Rx:0, DET_BELOW_RAIN_THOLD_122_Rx:0, DET_BELOW_RAIN_THOLD_123_Rx:0, DET_BELOW_RAIN_THOLD_124_Rx:0, DET_BI_STATIC_FLAG_121_Rx:0, DET_BI_STATIC_FLAG_122_Rx:0, DET_BI_STATIC_FLAG_123_Rx:0, DET_BI_STATIC_FLAG_124_Rx:0, DET_CONFD_AZIMUTH_121_Rx:0, DET_CONFD_AZIMUTH_122_Rx:0, DET_CONFD_AZIMUTH_123_Rx:0, DET_CONFD_AZIMUTH_124_Rx:0, DET_CONFD_ELEVATION_121_Rx:0, DET_CONFD_ELEVATION_122_Rx:0, DET_CONFD_ELEVATION_123_Rx:0, DET_CONFD_ELEVATION_124_Rx:0, DET_ELEVATION_121_Rx:0, DET_ELEVATION_122_Rx:0, DET_ELEVATION_123_Rx:0, DET_ELEVATION_124_Rx:0, DET_ELEVATION_ERR_121_Rx:0, DET_ELEVATION_ERR_122_Rx:0, DET_ELEVATION_ERR_123_Rx:0, DET_ELEVATION_ERR_124_Rx:0, DET_EXISTENCE_PROB_121_Rx:0, DET_EXISTENCE_PROB_122_Rx:0, DET_EXISTENCE_PROB_123_Rx:0, DET_EXISTENCE_PROB_124_Rx:0, DET_HVC_FLAG_121_Rx:0, DET_HVC_FLAG_122_Rx:0, DET_HVC_FLAG_123_Rx:0, DET_HVC_FLAG_124_Rx:0, DET_IDM_121_Rx:0, DET_IDM_122_Rx:0, DET_IDM_123_Rx:0, DET_IDM_124_Rx:0, DET_MH_CRC16_121_124_Rx:0, DET_MH_CYCLE_COUNTER_121_124_Rx:0, DET_MH_SCAN_INDEX_4LSB_121_124_Rx:0, DET_MTD_121_Rx:0, DET_MTD_122_Rx:0, DET_MTD_123_Rx:0, DET_MTD_124_Rx:0, DET_PROB_1STAZHYPO_121_Rx:0, DET_PROB_1STAZHYPO_122_Rx:0, DET_PROB_1STAZHYPO_123_Rx:0, DET_PROB_1STAZHYPO_124_Rx:0, DET_RANGE_121_Rx:0, DET_RANGE_122_Rx:0, DET_RANGE_123_Rx:0, DET_RANGE_124_Rx:0, DET_RANGE_ERR_121_Rx:0, DET_RANGE_ERR_122_Rx:0, DET_RANGE_ERR_123_Rx:0, DET_RANGE_ERR_124_Rx:0, DET_RANGE_VELOCITY_121_Rx:0, DET_RANGE_VELOCITY_122_Rx:0, DET_RANGE_VELOCITY_123_Rx:0, DET_RANGE_VELOCITY_124_Rx:0, DET_RANGE_VELOCITY_ERR_121_Rx:0, DET_RANGE_VELOCITY_ERR_122_Rx:0, DET_RANGE_VELOCITY_ERR_123_Rx:0, DET_RANGE_VELOCITY_ERR_124_Rx:0, DET_RCS_121_Rx:0, DET_RCS_122_Rx:0, DET_RCS_123_Rx:0, DET_RCS_124_Rx:0, DET_SNR_121_Rx:0, DET_SNR_122_Rx:0, DET_SNR_123_Rx:0, DET_SNR_124_Rx:0, DET_SUPER_RES_TARGET_121_Rx:0, DET_SUPER_RES_TARGET_122_Rx:0, DET_SUPER_RES_TARGET_123_Rx:0, DET_SUPER_RES_TARGET_124_Rx:0]}, required-interface=Pi_SG_Fusion_Detections_121_124_AL
      Rp_SG_Fusion_Detections_125_128_AL: nonqueued-receiver-com-spec{data-element=Vdp_SG_Fusion_Detections_125_128_AL, init-value=fields=[DET_AZIMUTH_125_Rx:0, DET_AZIMUTH_126_Rx:0, DET_AZIMUTH_127_Rx:0, DET_AZIMUTH_128_Rx:0, DET_AZIMUTH_ERR_125_Rx:0, DET_AZIMUTH_ERR_126_Rx:0, DET_AZIMUTH_ERR_127_Rx:0, DET_AZIMUTH_ERR_128_Rx:0, DET_BELOW_RAIN_THOLD_125_Rx:0, DET_BELOW_RAIN_THOLD_126_Rx:0, DET_BELOW_RAIN_THOLD_127_Rx:0, DET_BELOW_RAIN_THOLD_128_Rx:0, DET_BI_STATIC_FLAG_125_Rx:0, DET_BI_STATIC_FLAG_126_Rx:0, DET_BI_STATIC_FLAG_127_Rx:0, DET_BI_STATIC_FLAG_128_Rx:0, DET_CONFD_AZIMUTH_125_Rx:0, DET_CONFD_AZIMUTH_126_Rx:0, DET_CONFD_AZIMUTH_127_Rx:0, DET_CONFD_AZIMUTH_128_Rx:0, DET_CONFD_ELEVATION_125_Rx:0, DET_CONFD_ELEVATION_126_Rx:0, DET_CONFD_ELEVATION_127_Rx:0, DET_CONFD_ELEVATION_128_Rx:0, DET_ELEVATION_125_Rx:0, DET_ELEVATION_126_Rx:0, DET_ELEVATION_127_Rx:0, DET_ELEVATION_128_Rx:0, DET_ELEVATION_ERR_125_Rx:0, DET_ELEVATION_ERR_126_Rx:0, DET_ELEVATION_ERR_127_Rx:0, DET_ELEVATION_ERR_128_Rx:0, DET_EXISTENCE_PROB_125_Rx:0, DET_EXISTENCE_PROB_126_Rx:0, DET_EXISTENCE_PROB_127_Rx:0, DET_EXISTENCE_PROB_128_Rx:0, DET_HVC_FLAG_125_Rx:0, DET_HVC_FLAG_126_Rx:0, DET_HVC_FLAG_127_Rx:0, DET_HVC_FLAG_128_Rx:0, DET_IDM_125_Rx:0, DET_IDM_126_Rx:0, DET_IDM_127_Rx:0, DET_IDM_128_Rx:0, DET_MH_CRC16_125_128_Rx:0, DET_MH_CYCLE_COUNTER_125_128_Rx:0, DET_MH_SCAN_INDEX_4LSB_125_128_Rx:0, DET_MTD_125_Rx:0, DET_MTD_126_Rx:0, DET_MTD_127_Rx:0, DET_MTD_128_Rx:0, DET_PROB_1STAZHYPO_125_Rx:0, DET_PROB_1STAZHYPO_126_Rx:0, DET_PROB_1STAZHYPO_127_Rx:0, DET_PROB_1STAZHYPO_128_Rx:0, DET_RANGE_125_Rx:0, DET_RANGE_126_Rx:0, DET_RANGE_127_Rx:0, DET_RANGE_128_Rx:0, DET_RANGE_ERR_125_Rx:0, DET_RANGE_ERR_126_Rx:0, DET_RANGE_ERR_127_Rx:0, DET_RANGE_ERR_128_Rx:0, DET_RANGE_VELOCITY_125_Rx:0, DET_RANGE_VELOCITY_126_Rx:0, DET_RANGE_VELOCITY_127_Rx:0, DET_RANGE_VELOCITY_128_Rx:0, DET_RANGE_VELOCITY_ERR_125_Rx:0, DET_RANGE_VELOCITY_ERR_126_Rx:0, DET_RANGE_VELOCITY_ERR_127_Rx:0, DET_RANGE_VELOCITY_ERR_128_Rx:0, DET_RCS_125_Rx:0, DET_RCS_126_Rx:0, DET_RCS_127_Rx:0, DET_RCS_128_Rx:0, DET_SNR_125_Rx:0, DET_SNR_126_Rx:0, DET_SNR_127_Rx:0, DET_SNR_128_Rx:0, DET_SUPER_RES_TARGET_125_Rx:0, DET_SUPER_RES_TARGET_126_Rx:0, DET_SUPER_RES_TARGET_127_Rx:0, DET_SUPER_RES_TARGET_128_Rx:0]}, required-interface=Pi_SG_Fusion_Detections_125_128_AL
    provide port Pp_SG_RadarCapability_AL: nonqueued-sender-com-spec{data-element=Vdp_SG_RadarCapability_AL, init-value=fields=[CAP_AngleAzimuthRangeEnd:0, CAP_AngleAzimuthRangeStart:0, CAP_BlockageActive:1, CAP_BlockageProbability:0, CAP_BlockageSensitivity:2, CAP_BlockageStatus:3, CAP_BlockageValue:5, CAP_CYCLE_COUNTER:0, CAP_DampingActive:0, CAP_DampingCurrent:25500, CAP_DampingStandardDeviation:0, CAP_DampingStatus:3, CAP_FreeSightCheckActive:1, CAP_FreeSightCheckStatus:255, CAP_MaxDetectionRangeCar_0:0, CAP_MaxDetectionRangeCar_1:0, CAP_MaxDetectionRangeCar_2:0, CAP_MaxDetRangeMotorbike_0:0, CAP_MaxDetRangeMotorbike_1:0, CAP_MaxDetRangeMotorbike_2:0, CAP_MaxDetRangePedestrian_0:0, CAP_MaxDetRangePedestrian_1:0, CAP_MaxDetRangePedestrian_2:0, CAP_MH_CRC16:0, CAP_RangeEstimationActive:1, CAP_RangeEstimationStatus:3, CAP_SideLobeLevelBeamformer:0, CAP_SLBlockageFilterValue:0, CAP_SLBlockageFlag:0, CAP_SLLMonitoringActive:1, CAP_SLLMonitoringStatus:3]}, provided-interface=Pi_SG_RadarCapability_AL
    provide port Pp_SG_RadarStatus2_AL: nonqueued-sender-com-spec{data-element=Vdp_SG_RadarStatus2_AL, init-value=fields=[STS_AF_CORE_THROUGHPUT:0, STS_BRR_STATUS:0, STS_CAN_NM_State:0, STS_CORE_ACTV_FLT_BYTE_0_to_3:0, STS_CORE_ACTV_FLT_BYTE_4_to_7:0, STS_CORE_ACTV_FLT_BYTE_8_to_11:0, STS_CORE_ACTV_FLT_BYTE_11_to_15:0, STS_First_CAN_Det_Inst_Latency:0, STS_Gear_Position:0, STS_INTRFC_VERSION_ID_MAJOR:0, STS_INTRFC_VERSION_ID_MINOR:0, STS_INTRFC_VERSION_ID_PATCH:0, STS_Last_CAN_Det_Inst_Latency:0, STS_MCU_TEMP:0, STS_MH_002_CRC16:0, STS_MH_002_CYCLE_COUNTER:0, 0, STS_MMIC_TEMP_RX:0, STS_MMIC_TEMP_TX0:0, STS_MMIC_TEMP_TX1_2:0, STS_MMIC_TEMP_TX3_4:0, STS_NO_TSYN_ERROR:0, STS_POINT_OF_TRIGGER:0, STS_RAIN_COUNT:0, STS_RDD_CORE_THROUGHPUT:0, STS_SCAN_TYPE:0, STS_STEERING_ANGLE:0, STS_STEERING_ANGLE_SIGN:0, STS_TIME_SYNC_OFFSET:0, STS_TKEY_ACTV_FLT_BYTE_0_to_3:0, STS_TKEY_ACTV_FLT_BYTE_4_to_5:0, STS_VEH_SPEED_DIRECTION:0, STS_VEHICLE_SPEED_CALC:0, STS_Vehicle_Speed_Calc_QF:0, STS_VEHICLE_SUPPLY_VOLTAGE:0, STS_XCVR_OPERATIONAL:0, STS_YAW_RATE_BIAS:0, STS_Yaw_Rate_Calc_QF:0]}, provided-interface=Pi_SG_RadarStatus2_AL
    require port Rp_SG_VehicleStatus_AL: nonqueued-receiver-com-spec{data-element=Vdp_SG_VehicleStatus_AL, init-value=fields=[SSTS_CAN_PCAN_MAJOR_ADAS:0, SSTS_CAN_PCAN_MINOR_ADAS:0, SSTS_DRIVE_DIR:0, SSTS_DRIVE_REVERSE:0, SSTS_GEAR_POSITION:0, SSTS_IGN_STATUS:0, SSTS_MH_VS_CRC16:0, SSTS_MH_VS_CYCLE_COUNTER:0, SSTS_STEERING_ANGLE:0, SSTS_STEERING_ANGLE_SIGN:0, SSTS_SW_VERSION_ADAS:0, SSTS_VEH_AbsoluteTime_Day:1, SSTS_VEH_AbsoluteTime_Hour:0, SSTS_VEH_AbsoluteTime_Minute:0, SSTS_VEH_AbsoluteTime_Month:1, SSTS_VEH_AbsoluteTime_Second:0, SSTS_VEH_AbsoluteTime_Year:0, SSTS_VEH_ODOMETER:5 x 0, SSTS_VEH_POWER_MODE_STATUS:7 x 0, SSTS_VEH_SPD_COMP_FACTOR:0, SSTS_VEH_Status_CMAC:5 x 0, SSTS_VEH_Status_FV:7 x 0, SSTS_VEH_SYSTEM_VOLTAGE:0, SSTS_VEH_TRAILER_CONNECTED:0, SSTS_VEH_VARIANT:0, SSTS_VEHICLE_SPEED_CALC:0, SSTS_VEHICLE_SPEED_CALC_QF:0, SSTS_VEHICLE_STATE:0, SSTS_VIN_Data_Byte0:0, SSTS_VIN_Data_Byte1:0, SSTS_VIN_Data_Byte2:0, SSTS_VIN_Data_Byte3:0, SSTS_VIN_Data_Byte4:0, SSTS_VIN_Data_Byte5:0, SSTS_VIN_Data_Byte6:0, SSTS_VIN_FrameIdx:0, SSTS_YAW_RATE_BIAS:0, SSTS_YAW_RATE_CALC:448, SSTS_YAW_RATE_CALC_QF:0]}, required-interface=Pi_SG_VehicleStatus_AL
